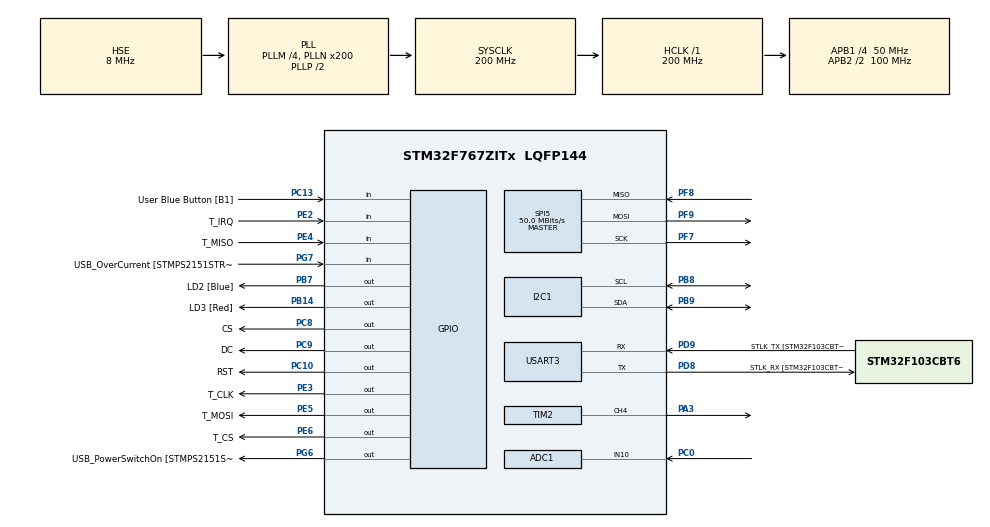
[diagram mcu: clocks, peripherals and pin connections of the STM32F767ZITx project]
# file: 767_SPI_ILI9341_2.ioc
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ADC1.Channel-0\#ChannelRegularConversion=ADC_CHANNEL_10
ADC1.ContinuousConvMode=ENABLE
ADC1.EOCSelection=ADC_EOC_SEQ_CONV
ADC1.NbrOfConversionFlag=1
ADC1.Rank-0\#ChannelRegularConversion=1
ADC1.SamplingTime-0\#ChannelRegularConversion=ADC_SAMPLETIME_3CYCLES
ADC1.master=1
CORTEX_M7.ART_ACCLERATOR_ENABLE=1
CORTEX_M7.CPU_DCache=Enabled
CORTEX_M7.CPU_ICache=Enabled
CORTEX_M7.PREFETCH_ENABLE=1
I2C1.Timing=0x00C0EAFF
Mcu.Family=STM32F7
Mcu.Name=STM32F767ZITx
Mcu.Package=LQFP144
NVIC.PriorityGroup=NVIC_PRIORITYGROUP_4
NVIC.TIM1_UP_TIM10_IRQn=true\:1\:0\:true\:false\:true\:true\:true\:true
NVIC.TIM2_IRQn=true\:2\:0\:true\:false\:true\:true\:true\:true
PA1.GPIO_Label=RMII_REF_CLK [LAN8742A-CZ-TR_REFCLK0]
PA1.Signal=ETH_REF_CLK
PA13.GPIO_Label=TMS
PA13.Mode=Serial_Wire
PA13.Signal=SYS_JTMS-SWDIO
PA14.GPIO_Label=TCK
PA14.Mode=Serial_Wire
PA14.Signal=SYS_JTCK-SWCLK
PA2.GPIO_Label=RMII_MDIO [LAN8742A-CZ-TR_MDIO]
PA2.Signal=ETH_MDIO
PA3.GPIO_Speed=GPIO_SPEED_FREQ_LOW
PA3.Signal=S_TIM2_CH4
PA7.GPIO_Label=RMII_CRS_DV [LAN8742A-CZ-TR_CRS_DV]
PA7.Signal=ETH_CRS_DV
PB13.GPIO_Label=RMII_TXD1 [LAN8742A-CZ-TR_TXD1]
PB13.Signal=ETH_TXD1
PB14.GPIO_Label=LD3 [Red]
PB14.Signal=GPIO_Output
PB3.GPIO_Label=SWO
PB3.Signal=SYS_JTDO-SWO
PB7.GPIO_Label=LD2 [Blue]
PB7.Signal=GPIO_Output
PB8.Mode=I2C
PB8.Signal=I2C1_SCL
PB9.Mode=I2C
PB9.Signal=I2C1_SDA
PC0.Signal=ADCx_IN10
PC1.GPIO_Label=RMII_MDC [LAN8742A-CZ-TR_MDC]
PC1.Signal=ETH_MDC
PC10.GPIO_Label=RST
PC10.GPIO_Speed=GPIO_SPEED_FREQ_VERY_HIGH
PC10.Signal=GPIO_Output
PC13.GPIO_Label=User Blue Button [B1]
PC13.Signal=GPIO_Input
PC14/OSC32_IN.Mode=LSE-External-Oscillator
PC14/OSC32_IN.Signal=RCC_OSC32_IN
PC15/OSC32_OUT.Mode=LSE-External-Oscillator
PC15/OSC32_OUT.Signal=RCC_OSC32_OUT
PC4.GPIO_Label=RMII_RXD0 [LAN8742A-CZ-TR_RXD0]
PC4.Signal=ETH_RXD0
PC5.GPIO_Label=RMII_RXD1 [LAN8742A-CZ-TR_RXD1]
PC5.Signal=ETH_RXD1
PC8.GPIO_Label=CS
PC8.GPIO_Speed=GPIO_SPEED_FREQ_VERY_HIGH
PC8.Signal=GPIO_Output
PC9.GPIO_Label=DC
PC9.GPIO_Speed=GPIO_SPEED_FREQ_VERY_HIGH
PC9.Signal=GPIO_Output
PD8.GPIO_Label=STLK_RX [STM32F103CBT6_PA3]
PD8.Mode=Asynchronous
PD8.Signal=USART3_TX
PD9.GPIO_Label=STLK_TX [STM32F103CBT6_PA2]
PD9.Mode=Asynchronous
PD9.Signal=USART3_RX
PE2.GPIO_Label=T_IRQ
PE2.Signal=GPIO_Input
PE3.GPIO_Label=T_CLK
PE3.GPIO_Speed=GPIO_SPEED_FREQ_VERY_HIGH
PE3.Signal=GPIO_Output
PE4.GPIO_Label=T_MISO
PE4.Signal=GPIO_Input
PE5.GPIO_Label=T_MOSI
PE5.GPIO_Speed=GPIO_SPEED_FREQ_VERY_HIGH
PE5.Signal=GPIO_Output
PE6.GPIO_Label=T_CS
PE6.GPIO_Speed=GPIO_SPEED_FREQ_VERY_HIGH
PE6.Signal=GPIO_Output
PF7.Mode=Full_Duplex_Master
PF7.Signal=SPI5_SCK
PF8.Mode=Full_Duplex_Master
PF8.Signal=SPI5_MISO
PF9.Mode=Full_Duplex_Master
PF9.Signal=SPI5_MOSI
PG11.GPIO_Label=RMII_TX_EN [LAN8742A-CZ-TR_TXEN]
PG11.Signal=ETH_TX_EN
PG13.GPIO_Label=RMII_TXD0 [LAN8742A-CZ-TR_TXD0]
PG13.Signal=ETH_TXD0
PG6.GPIO_Label=USB_PowerSwitchOn [STMPS2151STR_EN]
PG6.Signal=GPIO_Output
PG7.GPIO_Label=USB_OverCurrent [STMPS2151STR_FAULT]
PG7.Signal=GPIO_Input
PH0/OSC_IN.GPIO_Label=MCO [STM32F103CBT6_PA8]
PH0/OSC_IN.Mode=HSE-External-Clock-Source
PH0/OSC_IN.Signal=RCC_OSC_IN
PH1/OSC_OUT.Mode=HSE-External-Clock-Source
PH1/OSC_OUT.Signal=RCC_OSC_OUT
ProjectManager.HeapSize=0x200
ProjectManager.StackSize=0x400
ProjectManager.TargetToolchain=STM32CubeIDE
RCC.48MHZClocksFreq_Value=24000000
RCC.AHBFreq_Value=200000000
RCC.APB1CLKDivider=RCC_HCLK_DIV4
RCC.APB1Freq_Value=50000000
RCC.APB1TimFreq_Value=100000000
RCC.APB2CLKDivider=RCC_HCLK_DIV2
RCC.APB2Freq_Value=100000000
RCC.APB2TimFreq_Value=200000000
RCC.CortexFreq_Value=200000000
RCC.HCLKFreq_Value=200000000
RCC.HSE_VALUE=8000000
RCC.HSI_VALUE=16000000
RCC.PLLM=4
RCC.PLLMUL=RCC_PLL_MUL9
RCC.PLLN=200
RCC.PLLQ=9
RCC.PLLSourceVirtual=RCC_PLLSOURCE_HSE
RCC.PRESCALERUSB=RCC_USBCLKSOURCE_PLL_DIV1_5
RCC.SYSCLKFreq_VALUE=200000000
RCC.SYSCLKSource=RCC_SYSCLKSOURCE_PLLCLK
RCC.SYSCLKSourceVirtual=RCC_SYSCLKSOURCE_PLLCLK
RCC.USBFreq_Value=44444444.44444445
RCC.VCOOutputFreq_Value=400000000
SH.ADCx_IN10.0=ADC1_IN10,IN10
SH.S_TIM2_CH4.0=TIM2_CH4,PWM Generation4 CH4
SPI5.CalculateBaudRate=50.0 MBits/s
SPI5.DataSize=SPI_DATASIZE_8BIT
SPI5.Direction=SPI_DIRECTION_2LINES
SPI5.Mode=SPI_MODE_MASTER
SPI5.NSSPMode=SPI_NSS_PULSE_DISABLE
SPI5.VirtualType=VM_MASTER
TIM1.ClockDivision=TIM_CLOCKDIVISION_DIV1
TIM1.Period=65536-1
TIM1.Prescaler=20000-1
TIM2.Channel-PWM\ Generation4\ CH4=TIM_CHANNEL_4
TIM2.Period=199
TIM2.Prescaler=539
USART3.VirtualMode-Asynchronous=VM_ASYNC
VP_RNG_VS_RNG.Mode=RNG_Activate
VP_TIM1_VS_ClockSourceINT.Mode=Internal
VP_TIM2_VS_ClockSourceINT.Mode=Internal
board=NUCLEO-F767ZI

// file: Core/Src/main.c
/* USER CODE BEGIN Header */
/**
  ******************************************************************************
  * @file           : main.c
  * @brief          : Main program body
  ******************************************************************************
  * @attention
  *
  * <h2><center>&copy; Copyright (c) 2021 STMicroelectronics.
  * All rights reserved.</center></h2>
  *
  * This software component is licensed by ST under BSD 3-Clause license,
  * the "License"; You may not use this file except in compliance with the
  * License. You may obtain a copy of the License at:
  *                        opensource.org/licenses/BSD-3-Clause
  *
  ******************************************************************************
  */
/* USER CODE END Header */
#include "main.h"
#include "adc.h"
#include "i2c.h"
#include "rng.h"
#include "spi.h"
#include "tim.h"
#include "usart.h"
#include "gpio.h"

/* USER CODE BEGIN Includes */
#include "stdio.h"
#include "ILI9341_Touchscreen.h"

#include "ILI9341_STM32_Driver.h"
#include "ILI9341_GFX.h"

#include "snow_tiger.h"

#include "string.h"
#include <stdlib.h>
#include "stm32f7xx_hal.h"
#include "stdbool.h"
/* USER CODE END Includes */

/* USER CODE BEGIN PV */
/* Private variables ---------------------------------------------------------*/
float h = 30.0, t = 40.0;
uint16_t x_pos, y_pos = 0;
uint8_t step = 0;
HAL_StatusTypeDef status;
uint16_t Red = 0;
uint16_t Green = 0;
uint16_t Blue = 0;
uint16_t RGB_color;
uint8_t rCount = 0;
uint8_t gCount = 0;
uint8_t bCount = 0;
uint8_t rLength = 0;
uint8_t gLength = 0;
uint8_t bLength = 0;
int show_screen_2 = 0;
uint32_t count;
uint32_t prevCount;
uint32_t delayTime = 0;
uint16_t rgb = 0;
uint16_t exit_screen_2 = 1;
volatile uint32_t adc_val = 0;
#define P1011387_HEIGHT 132
#define P1011387_WIDTH 100
float brightness;

const uint16_t student_photo[26400]  = {
  0x9ef7, 0x9def, 0x9def, 0x7def, 0x7def, 0x7def, 0x7def, 0x5ce7, 0x5cef, 0x7def, 0x5de7, 0x5de7, 0xfade, 0xd5d5, 0xd1cc, 0x70c4, 0xb1cc, 0x33e5, 0x74ed, 0x74ed, 0xb6ed, 0x75ed, 0xd2e4, 0xf3e4, 0xd6ed, 0x17ee, 0x94e5, 0xd9ee, 0xfaee, 0x1aef, 0x1aef, 0x3bf7, 0x3bf7, 0x3bf7, 0x3bf7, 0x3bf7, 0x3bf7, 0x3bf7, 0x5bf7, 0x5bf7, 0x5bf7, 0x5bf7, 0x5bf7, 0x5bf7, 0x5bf7, 0x3bf7, 0x1bef, 0x1bef, 0x1aef, 0x1aef, 0x1aef, 0x1aef, 0x1aef, 0x1bf7, 0x1bef, 0x1aef, 0x5bef, 0x9df7, 0x9df7, 0x5bef, 0x16ef, 0xd4ee, 0xf5ee, 0x39ef, 0x7df7, 0x9ef7, 0x9ef7, 0x9ef7, 0x9ef7, 0x9ef7, 0x9ef7, 0x9ef7, 0x9ef7, 0x7def, 0x3ce7, 0xfcde, 0xfcd6, 0xfcd6, 0xfcd6, 0xfbd6, 0xfbd6, 0xfbd6, 0xfcd6, 0xfcd6, 0xfcd6, 0xdbde, 0x38e6, 0x96ed, 0xd4ed, 0x52ee, 0x32ee, 0xb5ed, 0x96ed, 0xb6ed, 0xf4ed, 0x91ee, 0x90ee, 0x90ee, 0x51ee, 0xd0ed,
  0x9ef7, 0x9ef7, 0x9ef7, 0x9def, 0x7def, 0x7def, 0x7bef, 0x5ae7, 0x5ae7, 0x5bef, 0x7def, 0x7de7, 0x5ce7, 0x57d6, 0xf1cc, 0x71c4, 0xb1cc, 0x53e5, 0x94ed, 0x54ed, 0x74ed, 0x95ed, 0x13e5, 0xd2dc, 0x74ed, 0xf6ed, 0x95e5, 0xd5dd, 0xf9ee, 0x1aef, 0x1aef, 0x1aef, 0x3bf7, 0x3bf7, 0x3bf7, 0x3bf7, 0x3bf7, 0x3bf7, 0x5bf7, 0x5bf7, 0x5bf7, 0x5bf7, 0x5bf7, 0x5bf7, 0x3bf7, 0x3bf7, 0x3bf7, 0x3bf7, 0x3bf7, 0x3bf7, 0x1aef, 0x1aef, 0x3bf7, 0x3bf7, 0x1bef, 0x1aef, 0x39ef, 0x7cf7, 0x9ef7, 0x9ef7, 0x9df7, 0x7cef, 0x38ef, 0x14ef, 0x58ef, 0x9cf7, 0x9ef7, 0x9ef7, 0x9ef7, 0x9ef7, 0x9ef7, 0x9ef7, 0x9ef7, 0x7def, 0x3ce7, 0xfcd6, 0xfcd6, 0xfcd6, 0xfcd6, 0xfbd6, 0xfbd6, 0xfbd6, 0xfcd6, 0xfcd6, 0xfcd6, 0xbade, 0xf8e5, 0xb5ed, 0x13ee, 0x52ee, 0xf4ed, 0x96ed, 0xb6ed, 0xd5ed, 0x72ee, 0x71ee, 0x32ee, 0xf4ed, 0x32ee, 0x71ee,
  0x9def, 0x9ef7, 0x9ef7, 0x9eef, 0x9def, 0x7cef, 0x7bef, 0x5ae7, 0x58e7, 0x5ae7, 0x7def, 0x7def, 0x7ce7, 0x99de, 0x33cd, 0x91c4, 0xf2d4, 0x93e5, 0xd3ed, 0x93ed, 0x33ed, 0x95ed, 0x54e5, 0xb1e4, 0xf2e4, 0x95ed, 0xd6ed, 0x33d5, 0x77e6, 0xfaee, 0xfaee, 0xfaee, 0x1aef, 0x3bf7, 0x3bf7, 0x3bf7, 0x3bf7, 0x3bf7, 0x3bf7, 0x5bf7, 0x5bf7, 0x5bf7, 0x5bf7, 0x3bf7, 0x3bf7, 0x3cf7, 0x5cf7, 0x3cf7, 0x3cf7, 0x3bf7, 0x3bf7, 0x3bf7, 0x3bf7, 0x3bf7, 0x1aef, 0x1aef, 0x17ef, 0x7bef, 0x9df7, 0x9ef7, 0x9ef7, 0x7bf7, 0x16ef, 0xd3f6, 0xf3f6, 0x56f7, 0x7bef, 0x9df7, 0x9ef7, 0x9ef7, 0x9ef7, 0x9ef7, 0x9ef7, 0x7def, 0x1cdf, 0xfcd6, 0xfcd6, 0xfcd6, 0xfcd6, 0xfbd6, 0xfbd6, 0xfbd6, 0xfcd6, 0xfcd6, 0xfcd6, 0x79de, 0xd7e5, 0xf4ed, 0x52ee, 0x13ee, 0xb5ed, 0xd5ed, 0x14ee, 0x52ee, 0x52ee, 0xd5ed, 0xd5ed, 0x32ee, 0x52ee, 0x95ed,
  0x7def, 0x9eef, 0x9ef7, 0x9ef7, 0x9def, 0x7bef, 0x7aef, 0x5ae7, 0x5ae7, 0x5be7, 0x7cef, 0x7bef, 0x39ef, 0xd8e6, 0xb5cd, 0xd1cc, 0x53dd, 0xf4ed, 0x13ee, 0xd3ed, 0x32ed, 0x53ed, 0x95ed, 0xd2e4, 0xb1e4, 0x13e5, 0xb6ed, 0x75e5, 0xb4d5, 0xd9ee, 0xfaee, 0xfaee, 0xfaee, 0x1aef, 0x3af7, 0x3bf7, 0x3bf7, 0x3bf7, 0x5bf7, 0x5bf7, 0x5bf7, 0x5bf7, 0x5bf7, 0x3bf7, 0x3bf7, 0x5cf7, 0x5cf7, 0x5cf7, 0x3bf7, 0x3bf7, 0x3bf7, 0x3bf7, 0x3bf7, 0x1bef, 0x1aef, 0x39ef, 0x16ef, 0x59ef, 0x9df7, 0x9ef7, 0x9ef7, 0x59f7, 0xf4f6, 0xb3ee, 0xd3f6, 0xf3f6, 0x35f7, 0x7af7, 0x9cf7, 0x9ef7, 0x9ef7, 0x9ef7, 0x9ef7, 0x5def, 0x1cdf, 0xfcd6, 0xfcd6, 0xfcd6, 0xfcd6, 0xfcd6, 0xfcd6, 0xfcd6, 0xfcd6, 0xfcd6, 0xfbd6, 0x59e6, 0xf6ed, 0x33ee, 0x72ee, 0x33ee, 0x33ee, 0x52ee, 0x71ee, 0x71ee, 0xd5ed, 0xd5ed, 0x52ee, 0x32ee, 0xb5ed, 0xb5ed,
  0x7def, 0x9def, 0x9ef7, 0x9ef7, 0x9def, 0x7cef, 0x7aef, 0x59e7, 0x5ae7, 0x5bef, 0x5bef, 0x58ef, 0x15ef, 0xd5ee, 0x15d6, 0x53cd, 0xb3dd, 0x14e6, 0xd3e5, 0xb2e5, 0x52ed, 0x12ed, 0x95ed, 0xf2e4, 0x91e4, 0xd2e4, 0x54ed, 0xd6ed, 0x74dd, 0x57e6, 0xfaee, 0xfaee, 0xd9ee, 0xfaee, 0x1aef, 0x1af7, 0x3bf7, 0x3bf7, 0x5bf7, 0x5bf7, 0x5bf7, 0x5bf7, 0x5bf7, 0x3bf7, 0x3bf7, 0x3bf7, 0x3bf7, 0x5cf7, 0x3bf7, 0x3bf7, 0x3bf7, 0x1aef, 0x1aef, 0x1aef, 0x1aef, 0x39ef, 0x16ef, 0x37ef, 0x7bf7, 0x9ef7, 0x9df7, 0x58f7, 0xd3f6, 0xd3ee, 0xf5ee, 0xd4ee, 0xf3f6, 0x34f7, 0x79f7, 0x9df7, 0x9ef7, 0x9ef7, 0x9ef7, 0x5de7, 0x1cdf, 0x1cdf, 0xfcd6, 0xfcd6, 0xfcd6, 0xfcd6, 0xfcd6, 0xfcd6, 0xfcd6, 0xfcd6, 0xfbde, 0x38e6, 0x14ee, 0x72ee, 0x91ee, 0x72ee, 0x53ee, 0x14ee, 0x13ee, 0x52ee, 0x14ee, 0x52ee, 0x52ee, 0xb5ed, 0xd5ed, 0x52ee,
  0x5bef, 0x7cef, 0x9df7, 0x9ef7, 0x9df7, 0x7cef, 0x7aef, 0x59e7, 0x5aef, 0x5bef, 0x5aef, 0x58ef, 0x36ef, 0xf4ee, 0x75de, 0xf5d5, 0xf4e5, 0x14e6, 0xd3e5, 0xb2e5, 0x72e5, 0xf2ec, 0x74ed, 0x13e5, 0x91e4, 0xd2e4, 0x13e5, 0xd6ed, 0xd6ed, 0xd5e5, 0xb9ee, 0xfaee, 0xd9ee, 0xd9ee, 0xd9ee, 0xfaee, 0x1aef, 0x3bf7, 0x3bf7, 0x3bf7, 0x5bf7, 0x3bf7, 0x3bf7, 0x3bf7, 0x3af7, 0x3af7, 0x3af7, 0x3bf7, 0x3bf7, 0x3bf7, 0x3af7, 0x1aef, 0x1aef, 0x1aef, 0x3bef, 0x39ef, 0x38ef, 0x15f7, 0x59f7, 0x7cf7, 0x7df7, 0x37f7, 0xf3f6, 0xf5ee, 0x38ef, 0x5aef, 0x37ef, 0x36ef, 0x59ef, 0x9df7, 0x9ef7, 0x9ef7, 0x9eef, 0x3ce7, 0x1cdf, 0x1cdf, 0xfcd6, 0xfcd6, 0xfcd6, 0xfcde, 0xfcd6, 0xfcd6, 0xfcd6, 0xfcde, 0xdbde, 0x57e6, 0x52ee, 0x91ee, 0x53ee, 0x14ee, 0xd5ed, 0xd5ed, 0x33ee, 0x91ee, 0x91ee, 0x71ee, 0x32ee, 0xd5ed, 0x32ee, 0x71ee,
  0x59ef, 0x37ef, 0x5bef, 0x9df7, 0x9df7, 0x7bef, 0x59ef, 0x59ef, 0x7bef, 0x5bef, 0x5aef, 0x59ef, 0x16ef, 0xf4ee, 0xd6ee, 0x98e6, 0x34e6, 0x34e6, 0xf3e5, 0x92e5, 0x72e5, 0xd1ec, 0x34ed, 0x13e5, 0xb1e4, 0x13ed, 0x33e5, 0xd6ed, 0x17ee, 0xb5ed, 0x37ee, 0xd9ee, 0xd9ee, 0xd9e6, 0xd9e6, 0xd9ee, 0xfaee, 0x1aef, 0x3bf7, 0x3bf7, 0x3bf7, 0x3bf7, 0x3bf7, 0x3af7, 0x3aef, 0x1aef, 0x1aef, 0x3aef, 0x3af7, 0x3af7, 0x3aef, 0x1aef, 0x1aef, 0x1aef, 0x5bef, 0x38ef, 0x59ef, 0x16f7, 0x15f7, 0x7af7, 0x7bf7, 0x36ef, 0xf4ee, 0x15ef, 0x59f7, 0x9df7, 0x7cf7, 0x7bef, 0x9cf7, 0x9ef7, 0x9ef7, 0x9ef7, 0x7def, 0x3ce7, 0x1cdf, 0xfcd6, 0xfcd6, 0x1cdf, 0xfcde, 0xfcde, 0xfcd6, 0xfcd6, 0xfcd6, 0x1cdf, 0xbade, 0x75ee, 0x72ee, 0x33ee, 0xd5ed, 0xb6ed, 0xb6ed, 0x14ee, 0x72ee, 0x53ee, 0x14ee, 0x13ee, 0x91ee, 0x52ee, 0x71ee, 0x90ee,
  0x5bef, 0x16ef, 0xf5ee, 0x5aef, 0x7def, 0x7bef, 0x7aef, 0x7aef, 0x7bef, 0x5bef, 0x5bef, 0x58ef, 0x15ef, 0xd3ee, 0xf7ee, 0xf9e6, 0x75e6, 0x53e6, 0xf2e5, 0x92e5, 0x72e5, 0xb1e4, 0x13ed, 0x33ed, 0xf2e4, 0x34ed, 0x34ed, 0xb5ed, 0xf6ed, 0xd6ed, 0xb5ed, 0x98ee, 0xd9ee, 0xd9e6, 0xb9e6, 0xb9e6, 0xd9ee, 0xf9ee, 0xfaee, 0x1aef, 0x3bf7, 0x3bf7, 0x3af7, 0x1aef, 0x1aef, 0x1aef, 0x1aef, 0x1aef, 0x3aef, 0x1aef, 0x1aef, 0x1aef, 0xfaee, 0x5cef, 0x5bef, 0x37ef, 0x5bef, 0x17f7, 0x14f7, 0x58f7, 0x58f7, 0x36ef, 0x16ef, 0x37ef, 0x7af7, 0x9ef7, 0x9ef7, 0x9ef7, 0x9ef7, 0x9ef7, 0x9ef7, 0x9ef7, 0x7def, 0x3ce7, 0xfcde, 0xfcd6, 0xfcd6, 0xfcde, 0x1cdf, 0x1cdf, 0x1cdf, 0xfcde, 0x1cdf, 0x1cdf, 0x99e6, 0x93ee, 0x52ee, 0xd5ed, 0x96ed, 0xb6ed, 0x14ee, 0x72ee, 0x33ee, 0xd5ed, 0xd5ed, 0x32ee, 0x52ee, 0xf3ed, 0xd4ed, 0x33ee,
  0x7def, 0x5bef, 0x16ef, 0x17ef, 0x5bef, 0x7cef, 0x7cef, 0x7cef, 0x7cef, 0x5cef, 0x59ef, 0x36ef, 0xf4ee, 0xd4ee, 0xf8ee, 0x1ae7, 0x95e6, 0x33e6, 0xf2e5, 0xb2e5, 0x92e5, 0xb1e4, 0xf2ec, 0x54ed, 0x34ed, 0x34ed, 0x33ed, 0x95ed, 0xb6ed, 0xf7ed, 0x95ed, 0x36ee, 0xb9e6, 0xd9e6, 0xd9e6, 0xb9e6, 0xb9e6, 0xb9e6, 0xd9ee, 0xfaee, 0x1aef, 0x1af7, 0x1aef, 0x1af7, 0x1af7, 0x1af7, 0x1af7, 0x1aef, 0x1aef, 0x1aef, 0x1aef, 0xfaee, 0x1bef, 0x7def, 0x5aef, 0x36ef, 0x7bf7, 0x59ef, 0x15f7, 0x37f7, 0x36f7, 0x57f7, 0x58ef, 0x38ef, 0x7aef, 0x9ef7, 0x9ef7, 0x9ef7, 0x9ef7, 0x9ef7, 0x9ef7, 0x9ef7, 0x7def, 0x3ce7, 0x1cdf, 0xfcd6, 0x1cdf, 0xfcde, 0xfcde, 0x1cdf, 0xfcde, 0x1cdf, 0x1cdf, 0xfcde, 0x97e6, 0x92ee, 0x33ee, 0xf5ed, 0x14ee, 0x53ee, 0x72ee, 0x33ee, 0xd6ed, 0xd6ed, 0x13ee, 0x52ee, 0xd5ed, 0x95ed, 0xf4ed, 0x71ee,
  0x7aef, 0x58ef, 0x35ef, 0x16ef, 0x7bef, 0x9def, 0x7def, 0x7def, 0x7def, 0x7cef, 0x38ef, 0x14ef, 0xf4f6, 0xd5ee, 0x19ef, 0x3be7, 0x76e6, 0x13e6, 0xf3ed, 0xb3e5, 0x52e5, 0xb1e4, 0xf2ec, 0x75ed, 0x75ed, 0x54ed, 0x13ed, 0x54ed, 0x95ed, 0xb6ed, 0xd6ed, 0xb5ed, 0x78e6, 0xd9e6, 0xd9e6, 0xb9e6, 0xb9e6, 0x98e6, 0x99e6, 0xb9ee, 0xf9ee, 0x1aef, 0x1af7, 0x1af7, 0x1af7, 0x1af7, 0x1af7, 0x1af7, 0x1aef, 0x1aef, 0x1aef, 0x3bef, 0x7df7, 0x9ef7, 0x7cef, 0x38ef, 0x7bf7, 0x7cf7, 0x38ef, 0x59ef, 0x79ef, 0x7aef, 0x7bef, 0x59ef, 0x7cef, 0x9ef7, 0x9ef7, 0x9ef7, 0x9ef7, 0x9ef7, 0x9ef7, 0x9ef7, 0x5def, 0x1cdf, 0x1cdf, 0x1cdf, 0x1cdf, 0xfcde, 0xfcde, 0xfcde, 0x1cdf, 0x1cdf, 0x1cdf, 0xfbde, 0xb6e6, 0x92ee, 0x92ee, 0x92ee, 0x91ee, 0x91ee, 0x53ee, 0xd5ed, 0xb6ed, 0xf5ed, 0x52ee, 0xd4ed, 0xb6ed, 0xd5ed, 0x91ee, 0x33ee,
  0x37ef, 0x37ef, 0x15ef, 0x59ef, 0x9def, 0x9def, 0x7def, 0x7def, 0x7def, 0x7def, 0x38ef, 0xf4ee, 0xd3ee, 0xd6ee, 0x5bef, 0x5ce7, 0x98e6, 0xf3e5, 0xd2ed, 0x52e5, 0xd1dc, 0x91e4, 0xf2ec, 0x75ed, 0x95ed, 0x54ed, 0x13ed, 0x33ed, 0x54ed, 0x75ed, 0xd6ed, 0x95ed, 0x57e6, 0xd9e6, 0xd9e6, 0xb9e6, 0xb9e6, 0xb9e6, 0x98e6, 0x98e6, 0xb9ee, 0xd9ee, 0xf9ee, 0xf9ee, 0x19ef, 0x19ef, 0x19ef, 0x1aef, 0x1aef, 0xfaee, 0x3cef, 0x9def, 0x9ef7, 0xbef7, 0x9ef7, 0x9df7, 0x9ef7, 0x9ef7, 0x9df7, 0x9df7, 0x9df7, 0x9df7, 0x9df7, 0x9cf7, 0x9df7, 0x9ef7, 0x9ef7, 0x9ef7, 0x9ef7, 0x9ef7, 0x9ef7, 0x9ef7, 0x5de7, 0x1cdf, 0x1cdf, 0x1cdf, 0x1cdf, 0x1cdf, 0x1cdf, 0xfcde, 0xfcde, 0xfcd6, 0x1cdf, 0xfbde, 0xd4e6, 0xb1ee, 0x72ee, 0x14ee, 0x15ee, 0x53ee, 0x14ee, 0x96ed, 0xb6ed, 0xf4ed, 0x52ee, 0x96ed, 0xb6f5, 0x32ee, 0x32ee, 0x76ed,
  0x59e7, 0x57ef, 0x36ef, 0x5bef, 0x9def, 0x9eef, 0x9def, 0x9def, 0x9eef, 0x9def, 0x3bef, 0xb6e6, 0xb5ee, 0x1aef, 0x7def, 0x7def, 0xfae6, 0x14de, 0x92e5, 0xf1dc, 0x91d4, 0x91e4, 0xb1ec, 0x75ed, 0xb5ed, 0x33ed, 0x13ed, 0x53ed, 0x54ed, 0x33ed, 0xd6ed, 0x95ed, 0xf6e5, 0x98e6, 0xd9ee, 0xd9ee, 0xb9e6, 0xb9e6, 0xb9e6, 0x98e6, 0x98e6, 0x58e6, 0x37e6, 0x37e6, 0x78e6, 0x78ee, 0xb8ee, 0xf9ee, 0x3bef, 0x7def, 0x9ef7, 0x9eef, 0x9def, 0x9eef, 0x9eef, 0x9eef, 0xbef7, 0xbef7, 0x9ef7, 0x9ef7, 0x9ef7, 0x9ef7, 0x9ef7, 0x9ef7, 0x9ef7, 0x9ef7, 0x9ef7, 0x9ef7, 0x9ef7, 0x9ef7, 0x9ef7, 0x9eef, 0x3ce7, 0x1cdf, 0x1cdf, 0x1cdf, 0x1cdf, 0xfcde, 0xfcde, 0xfcde, 0xfcde, 0x1cdf, 0x1cdf, 0xfade, 0xd4ee, 0x53ee, 0xd5ed, 0x96ed, 0xf5ed, 0x53ee, 0x52ee, 0x72ee, 0x92ee, 0x92ee, 0x92ee, 0x34ee, 0x53ee, 0x91ee, 0x72ee, 0x13ee,
  0x58ef, 0x36ef, 0x5ae7, 0x7def, 0x9def, 0x9eef, 0x9def, 0x9def, 0x9eef, 0x9def, 0x7def, 0x5bef, 0x5cef, 0x7def, 0x7de7, 0x7def, 0x3be7, 0x36de, 0x72e5, 0xd1dc, 0x91dc, 0x91e4, 0xb1ec, 0x33ed, 0x95ed, 0x54ed, 0x33ed, 0x53ed, 0x54ed, 0x13ed, 0x95ed, 0x95ed, 0xb5e5, 0x78e6, 0xb9e6, 0xb9e6, 0xb9e6, 0xb9e6, 0xb9e6, 0x99e6, 0x78e6, 0xb6cd, 0x929c, 0x318c, 0x929c, 0x17ce, 0x5def, 0x9def, 0x9ef7, 0x9ef7, 0x9eef, 0x9eef, 0x9def, 0x7def, 0x7def, 0x9def, 0x9def, 0x9eef, 0x9eef, 0x9ef7, 0x9ef7, 0x9ef7, 0x9ef7, 0x9ef7, 0x9ef7, 0x9ef7, 0x9ef7, 0x9ef7, 0x9ef7, 0x9ef7, 0x9ef7, 0x7def, 0x3ce7, 0x1cdf, 0x1cdf, 0x1cdf, 0x1cdf, 0x1cdf, 0x1cdf, 0x1cdf, 0x1cdf, 0x1cdf, 0x1cdf, 0xf9de, 0x75ee, 0xd5ed, 0x96ed, 0xb6ed, 0xf4ed, 0x72ee, 0x72ee, 0xf4ed, 0xb5ed, 0xd5ed, 0x52ee, 0x72ee, 0x54ee, 0x33ee, 0xb0ee, 0x52ee,
  0x59ef, 0x5be7, 0x7de7, 0x9def, 0x9eef, 0x9eef, 0x9eef, 0x9eef, 0x9def, 0x7cef, 0x7bef, 0x7bef, 0x7cef, 0x7def, 0x7de7, 0x9def, 0x5def, 0x58de, 0xf1d4, 0x91d4, 0x91dc, 0x91ec, 0x70ec, 0xd2ec, 0x54ed, 0x54ed, 0x33ed, 0x34ed, 0x75ed, 0x33ed, 0x74ed, 0x95ed, 0x74e5, 0x37e6, 0xb9e6, 0xb9e6, 0xb9e6, 0xb8e6, 0x98e6, 0x98e6, 0xf6d5, 0xf3ac, 0x1084, 0x1094, 0x929c, 0xbad6, 0x9ef7, 0x9ef7, 0x9ef7, 0x9eef, 0x9eef, 0x9eef, 0x9eef, 0x9eef, 0x9eef, 0x9def, 0x9def, 0x9def, 0x9def, 0x9eef, 0x9ef7, 0x9ef7, 0x9ef7, 0x9ef7, 0x9ef7, 0x9ef7, 0x9ef7, 0x9ef7, 0x9ef7, 0x9ef7, 0x9ef7, 0x7def, 0x1cdf, 0x1cdf, 0x1cdf, 0x1cdf, 0x1cdf, 0x1cdf, 0x1cdf, 0x1cdf, 0x1cdf, 0x1cdf, 0x1cdf, 0xf8e6, 0x35ee, 0xb6ed, 0xb6ed, 0xf5ed, 0x33ee, 0x53ee, 0xd5ed, 0xb6ed, 0xb6ed, 0x14ee, 0x33ee, 0xd5ed, 0xb6ed, 0xd5ed, 0xf4ed, 0x96ed,
  0x7de7, 0x7de7, 0x7de7, 0x7def, 0x9eef, 0x9eef, 0x9def, 0x7cef, 0x7aef, 0x57ef, 0x5aef, 0x5aef, 0x59ef, 0x7bef, 0x7def, 0x9eef, 0x7def, 0xbae6, 0x53d5, 0xb1dc, 0xb1e4, 0x91ec, 0x70ec, 0x91ec, 0xf2ec, 0x12ed, 0x33ed, 0x33ed, 0x54ed, 0x75ed, 0x54ed, 0x95ed, 0x53e5, 0xf6e5, 0x98e6, 0xb9e6, 0xb8e6, 0xb8e6, 0x98e6, 0x57de, 0x54bd, 0x518c, 0xf083, 0x109c, 0x92ac, 0xdade, 0x9eef, 0x9ef7, 0x9ef7, 0xbef7, 0xbef7, 0xbef7, 0x9ef7, 0x9eef, 0x9eef, 0x9eef, 0x9eef, 0x9def, 0x9def, 0x9def, 0x9eef, 0x9ef7, 0x9ef7, 0x9ef7, 0x9ef7, 0x9ef7, 0x9ef7, 0x9ef7, 0x9ef7, 0x9ef7, 0x9ef7, 0x7def, 0x1cdf, 0x1cdf, 0x1cdf, 0x1cdf, 0x1cdf, 0x1cdf, 0xfcde, 0x1cdf, 0xfcde, 0x1cdf, 0x1cdf, 0xb8e6, 0xf6ed, 0xb6ed, 0xf5ed, 0x53ee, 0x53ee, 0xf5ed, 0xd5ed, 0xf5ed, 0x14ee, 0x33ee, 0xd5ed, 0xb6ed, 0xd5ed, 0xd4ed, 0x96ed, 0x96f5,
  0x7de7, 0x7de7, 0x7def, 0x7def, 0x9def, 0x9def, 0x7bef, 0x58ef, 0x35f7, 0x14f7, 0x59ef, 0x5aef, 0x37ef, 0x59ef, 0x9def, 0x9ef7, 0x7def, 0x3bef, 0x37e6, 0x13e5, 0xd2ec, 0xb1ec, 0x70ec, 0x50ec, 0x90ec, 0xb1ec, 0x12ed, 0x33ed, 0x34ed, 0x75ed, 0x74ed, 0x95ed, 0x33ed, 0x95e5, 0x57e6, 0xb8e6, 0xb9e6, 0xb8e6, 0x78e6, 0xb5cd, 0x929c, 0x1184, 0x1094, 0x30ac, 0xb2b4, 0xfbde, 0x9eef, 0x9eef, 0x9ef7, 0xbef7, 0xbef7, 0xbef7, 0xbef7, 0xbef7, 0xbef7, 0xbef7, 0x9eef, 0x9eef, 0x9eef, 0x9def, 0x9def, 0x9eef, 0x9ef7, 0x9ef7, 0x9ef7, 0x9ef7, 0x9ef7, 0x9ef7, 0x9ef7, 0x9ef7, 0x9ef7, 0x5de7, 0x1cdf, 0x1cdf, 0x1cdf, 0x1cdf, 0xfcde, 0x1cdf, 0xfcde, 0x1cdf, 0xfcde, 0x1cdf, 0x1cdf, 0x99e6, 0xf6ed, 0x14ee, 0x73ee, 0x72ee, 0x33ee, 0x14ee, 0x53ee, 0x53ee, 0x53ee, 0xf5ed, 0xb6ed, 0xd5ed, 0xf4ed, 0x96ed, 0x96ed, 0x96ed,
  0x7de7, 0x7de7, 0x9def, 0x9def, 0x9def, 0x7cef, 0x58ef, 0x35f7, 0x33f7, 0x15ef, 0x5aef, 0x59ef, 0x35f7, 0x57ef, 0x7cef, 0x7def, 0x7bef, 0x59ef, 0x1be7, 0x37e6, 0x12e5, 0xb1ec, 0x50ec, 0x2fec, 0x50ec, 0x70ec, 0xd1ec, 0x13ed, 0x33ed, 0x34ed, 0x54ed, 0x75ed, 0x54ed, 0x74e5, 0x36e6, 0x98e6, 0x98e6, 0x98e6, 0xf6d5, 0xd2ac, 0x308c, 0x1084, 0x30a4, 0x91cc, 0xf2cc, 0xfbe6, 0x9ef7, 0x9eef, 0x9ef7, 0xbef7, 0xbef7, 0xbef7, 0xbef7, 0xbef7, 0xbef7, 0xbef7, 0x9ef7, 0x9eef, 0x9eef, 0x9def, 0x9def, 0x9def, 0x9ef7, 0x9ef7, 0x9ef7, 0x9ef7, 0x9ef7, 0x9ef7, 0x9ef7, 0x9ef7, 0x9def, 0x3ce7, 0x1cdf, 0x1cdf, 0x1cdf, 0x1cdf, 0x1cdf, 0x1cdf, 0x1cdf, 0x1cdf, 0x1cdf, 0x1cdf, 0x1cdf, 0x78e6, 0x54ee, 0x73ee, 0x53ee, 0x53ee, 0x52ee, 0x53ee, 0x34ee, 0x34ee, 0x53ee, 0xf5ed, 0xf5ed, 0x13ee, 0xf4ed, 0x96ed, 0xb6ed, 0xf4ed,
  0x7de7, 0x7de7, 0x7def, 0x9eef, 0x9def, 0x7def, 0x5aef, 0x57ef, 0x36ef, 0x38ef, 0x5bef, 0x39ef, 0x15f7, 0x36f7, 0x5aef, 0x5aef, 0x37ef, 0x38ef, 0x7def, 0xfbe6, 0x74e5, 0x91ec, 0x50ec, 0x2fec, 0x2fec, 0x30ec, 0x70ec, 0xd2ec, 0x33ed, 0x33ed, 0x33ed, 0x54ed, 0x54ed, 0x33e5, 0xf6e5, 0x98e6, 0x98e6, 0x16de, 0x13b5, 0x3094, 0x1094, 0x1094, 0x51b4, 0xd2dc, 0x54dd, 0xfbe6, 0x9def, 0x9eef, 0x9ef7, 0xbef7, 0xbef7, 0xbef7, 0xbef7, 0xbef7, 0xbef7, 0xbef7, 0x9ef7, 0x9ef7, 0x9eef, 0x9def, 0x7def, 0x9def, 0x9eef, 0x9ef7, 0x9ef7, 0x9ef7, 0x9ef7, 0x9ef7, 0x9ef7, 0x9ef7, 0x7def, 0x3cdf, 0x1cdf, 0x1cdf, 0x1cdf, 0x1cdf, 0x1cdf, 0x1cdf, 0x1cdf, 0x1cdf, 0x1cdf, 0x1cdf, 0xfbde, 0x76e6, 0x11e6, 0x71e5, 0x92e5, 0x32ee, 0x32ee, 0xb4ed, 0xd5ed, 0x33ee, 0x92ee, 0x73ee, 0x53ee, 0x72ee, 0x53ee, 0x14ee, 0x53ee, 0x92ee,
  0x7de7, 0x7def, 0x7eef, 0x9eef, 0x7eef, 0x7def, 0x7bef, 0x59ef, 0x59ef, 0x5bef, 0x5cef, 0x38ef, 0x15ef, 0x36ef, 0x37ef, 0x36ef, 0x15f7, 0x38ef, 0x7def, 0x5cef, 0x38e6, 0x91ec, 0x50ec, 0x2fec, 0x2fec, 0x2fec, 0x50ec, 0xb1ec, 0x13ed, 0x13ed, 0x13ed, 0x13ed, 0x34ed, 0x33e5, 0xd5e5, 0x77e6, 0x57e6, 0x74c5, 0x71a4, 0x109c, 0x109c, 0x0f9c, 0x50bc, 0xd2e4, 0x75e5, 0x1be7, 0x7def, 0x9ef7, 0x9ef7, 0xbef7, 0xbef7, 0xbef7, 0xbef7, 0xbef7, 0xbef7, 0xbef7, 0xbef7, 0x9ef7, 0x9ef7, 0x9eef, 0x7def, 0x7def, 0x9def, 0x9ef7, 0x9ef7, 0x9ef7, 0x9ef7, 0x9ef7, 0x9ef7, 0x9ef7, 0x7def, 0x1cdf, 0x1cdf, 0x1cdf, 0x1cdf, 0x1cdf, 0x1cdf, 0xfcde, 0x1cdf, 0x1cdf, 0x1cdf, 0x1cdf, 0xdbde, 0x74e6, 0x0fdd, 0x4ed4, 0x50e5, 0xd0e5, 0xf0e4, 0x90e4, 0x71e5, 0x11ee, 0xb0ed, 0xd1ed, 0x71ee, 0x91ee, 0x72ee, 0x92ee, 0x72ee, 0x52ee,
  0x7de7, 0x7eef, 0x9eef, 0x7eef, 0x7def, 0x7def, 0x7cef, 0x7cef, 0x5aef, 0x5bef, 0x7cef, 0x38ef, 0x36ef, 0x58ef, 0x57ef, 0x35f7, 0x14f7, 0x38ef, 0x7def, 0x7def, 0xdae6, 0xd2e4, 0x50ec, 0x50ec, 0x2fec, 0x2fec, 0x2fec, 0x71ec, 0xf2ec, 0x33ed, 0x13ed, 0xf3ec, 0x13ed, 0xf2e4, 0xd5e5, 0x57e6, 0xb5cd, 0xb1a4, 0x309c, 0x0f9c, 0xef93, 0xefa3, 0x0fcc, 0x70dc, 0x75dd, 0x3ce7, 0x9def, 0x9ef7, 0x9ef7, 0xbef7, 0xbef7, 0xbef7, 0xbef7, 0xbef7, 0xbef7, 0xbef7, 0xbef7, 0x9ef7, 0x9ef7, 0x9eef, 0x7def, 0x7def, 0x9def, 0x9eef, 0x9ef7, 0x9ef7, 0x9ef7, 0x9ef7, 0x9ef7, 0x9ef7, 0x7def, 0x1cdf, 0x1cdf, 0x1cdf, 0xfcde, 0xfcde, 0xfcde, 0xfcde, 0x1cdf, 0x1cdf, 0x1cdf, 0x1cdf, 0xbad6, 0xf2d5, 0x4dc4, 0x4dcc, 0x8fdd, 0xefdc, 0xcedb, 0x8ee4, 0xd0e5, 0x6fe5, 0x6eec, 0xb0ed, 0x51ee, 0x0fe5, 0x8fe4, 0xf0e4, 0xd1ed, 0x31e5,
  0x7ddf, 0x7ee7, 0x9eef, 0x7eef, 0x7eef, 0x7def, 0x7def, 0x7def, 0x5bef, 0x7cef, 0x7cef, 0x59ef, 0x38ef, 0x5aef, 0x58ef, 0x34f7, 0x14f7, 0x38ef, 0x7def, 0x7def, 0x1cef, 0x74e5, 0x70ec, 0x50ec, 0x2fe4, 0x2fe4, 0x2fec, 0x50ec, 0xd2ec, 0x33ed, 0x13ed, 0xf2ec, 0xf3ec, 0xf2e4, 0x74e5, 0xb5cd, 0xd39c, 0x308c, 0x0f9c, 0x0f9c, 0x0f9c, 0xeeab, 0xeed3, 0x2fdc, 0x54dd, 0x5de7, 0x9eef, 0x9ef7, 0x9ef7, 0xbef7, 0xbef7, 0xbef7, 0xbef7, 0xbef7, 0xbef7, 0xbef7, 0xbef7, 0xbef7, 0x9ef7, 0x9eef, 0x9def, 0x7de7, 0x7de7, 0x9def, 0x9ef7, 0x9ef7, 0x9ef7, 0x9ef7, 0x9ef7, 0x9eef, 0x5de7, 0x1cdf, 0x1cdf, 0x1cdf, 0xfcde, 0xfcde, 0x1cdf, 0x1cdf, 0x1cdf, 0x1cdf, 0x1cdf, 0x1cdf, 0x79ce, 0xb0c4, 0x0cbc, 0x4ed5, 0x4fd5, 0xedc3, 0xccc3, 0x2ed5, 0xafdd, 0x6dd4, 0xcedc, 0x10e6, 0xafe4, 0xcee3, 0xcee3, 0x8fe4, 0x2fe5, 0xcee3,
  0x5ddf, 0x7de7, 0x9eef, 0x7eef, 0x7eef, 0x7def, 0x7def, 0x7def, 0x7de7, 0x7de7, 0x7cef, 0x5aef, 0x59ef, 0x5aef, 0x58ef, 0x36ef, 0x36ef, 0x38ef, 0x7def, 0x7def, 0x5def, 0x38e6, 0x70ec, 0x50ec, 0x0fec, 0x0fec, 0x0fec, 0x50ec, 0x91ec, 0xf2ec, 0x12ed, 0xd2ec, 0xf2ec, 0xf3e4, 0xb2cc, 0x5194, 0x317c, 0x308c, 0x30a4, 0x50ac, 0x70b4, 0x50cc, 0x0fdc, 0x2fd4, 0x75d5, 0x5de7, 0x9def, 0x9ef7, 0x9ef7, 0xbef7, 0xbef7, 0xbef7, 0xbef7, 0xbef7, 0xbef7, 0xbef7, 0xbef7, 0x9ef7, 0x9ef7, 0x9eef, 0x9def, 0x7de7, 0x7de7, 0x7de7, 0x7def, 0x9eef, 0x9ef7, 0x9ef7, 0x9ef7, 0x7def, 0x5de7, 0x1cdf, 0x1cdf, 0x1cdf, 0x1cdf, 0x1cdf, 0x1cdf, 0x1cdf, 0x1cdf, 0x1cdf, 0x1cdf, 0x1cdf, 0x17ce, 0x90c4, 0x6fd5, 0x50e6, 0xeecc, 0xacbb, 0xcecc, 0xefe5, 0xced4, 0x0dcc, 0x6edd, 0x0ed5, 0x6cbb, 0x4cbb, 0xcdcb, 0x4fdd, 0xadc3, 0x8dcb,
  0x5edf, 0x7de7, 0x7eef, 0x7eef, 0x7eef, 0x7eef, 0x9def, 0x7de7, 0x7de7, 0x7de7, 0x7de7, 0x5ce7, 0x5cef, 0x5aef, 0x59ef, 0x7aef, 0x36ef, 0x37ef, 0x7def, 0x7def, 0x7def, 0xdae6, 0xd2e4, 0x71ec, 0x2fec, 0x0fe4, 0x50e4, 0x30ec, 0x91ec, 0xf2ec, 0x13ed, 0xf3ec, 0xd2ec, 0xd2e4, 0x71c4, 0x118c, 0x1174, 0x309c, 0x91c4, 0xd2dc, 0xd2dc, 0x91dc, 0x2fd4, 0x70c4, 0xb6cd, 0x7def, 0x9def, 0x9ef7, 0xbef7, 0xbef7, 0xbef7, 0xbef7, 0xbef7, 0xbef7, 0xbef7, 0xbef7, 0x9ef7, 0x9ef7, 0x9ef7, 0x9eef, 0x9def, 0x7de7, 0x7de7, 0x7de7, 0x7de7, 0x9def, 0x9ef7, 0x9ef7, 0x9ef7, 0x7def, 0x5de7, 0x1cdf, 0x1cdf, 0x1cdf, 0xfcde, 0xfcde, 0x1cdf, 0x1cdf, 0x1cdf, 0x1cdf, 0x1cdf, 0x1cdf, 0xb6cd, 0x91d5, 0xd0dd, 0x10de, 0xeecc, 0x0ecd, 0x50e6, 0x8fdd, 0xecc3, 0x4dcc, 0xafdd, 0x6dcc, 0x2bbb, 0x6cbb, 0x6dc4, 0x6dc4, 0x4bbb, 0x8cbb,
  0x5ddf, 0x7ddf, 0x7eef, 0x7eef, 0x7eef, 0x7eef, 0x9def, 0x7def, 0x7de7, 0x7de7, 0x7def, 0x7de7, 0x7def, 0x7cef, 0x7cef, 0x7aef, 0x37ef, 0x39ef, 0x7de7, 0x7def, 0x7de7, 0x3cef, 0x75e5, 0x71ec, 0x30e4, 0x0fec, 0x2fe4, 0x50ec, 0x71ec, 0xb2ec, 0xf3ec, 0xf3ec, 0xd2ec, 0x91e4, 0x91d4, 0x3194, 0xf07b, 0x0fa4, 0x50c4, 0xb1d4, 0x91d4, 0x70d4, 0x0fcc, 0x91bc, 0xf7cd, 0x7def, 0x9eef, 0x9ef7, 0xbef7, 0xbef7, 0xbef7, 0x9ef7, 0x9ef7, 0x9ef7, 0x9ef7, 0xbef7, 0xbef7, 0x9ef7, 0x9ef7, 0x9ef7, 0x9ef7, 0x7def, 0x7de7, 0x7ddf, 0x7de7, 0x7def, 0x9eef, 0x9ef7, 0x9ef7, 0x7def, 0x3ce7, 0xfcde, 0x1cdf, 0x1cdf, 0x1cdf, 0x1cdf, 0x1cdf, 0xfcd6, 0xfcde, 0xfcde, 0xfcde, 0xfcde, 0x36d6, 0x11de, 0x2ecd, 0x8fd5, 0xf0dd, 0xf0dd, 0x30e6, 0x0ed5, 0x0dc4, 0x6fd5, 0x30e6, 0xeed4, 0xacbb, 0x2dc4, 0x6fd5, 0x4dc4, 0x6dc4, 0xf0dd,
  0x5ddf, 0x5ddf, 0x7ee7, 0x9eef, 0x7eef, 0x7eef, 0x7def, 0x7def, 0x7de7, 0x7def, 0x9def, 0x7def, 0x7de7, 0x7def, 0x9def, 0x7cef, 0x7bef, 0x7cef, 0x7de7, 0x7def, 0x7de7, 0x5ce7, 0x58de, 0x91e4, 0x70e4, 0x2fe4, 0x0fe4, 0x2fec, 0x70ec, 0x91ec, 0xd2ec, 0xf2ec, 0xf2ec, 0x71ec, 0x71dc, 0x31a4, 0xf083, 0xefa3, 0x0fc4, 0x0ed4, 0x0ed4, 0x2fcc, 0x30bc, 0xb2bc, 0x58d6, 0x9eef, 0x9eef, 0x9eef, 0x9ef7, 0x9ef7, 0x9ef7, 0x9ef7, 0x9ef7, 0x9ef7, 0x9eef, 0x9ef7, 0xbef7, 0xbef7, 0xbef7, 0x9ef7, 0x9ef7, 0x9def, 0x7de7, 0x7ddf, 0x7de7, 0x7de7, 0x9eef, 0x9ef7, 0x9ef7, 0x7def, 0x3ce7, 0xfcd6, 0xfcde, 0x1cdf, 0x1cdf, 0x1cdf, 0xfcde, 0xfcde, 0x1cdf, 0x1cdf, 0xfcde, 0xfcde, 0xb6e6, 0x90d5, 0x2dc4, 0x2fd5, 0x10e6, 0xcfdd, 0xefdd, 0x8fdd, 0x4fd5, 0x10de, 0xefdd, 0xcfdd, 0xafdd, 0x6fd5, 0xf0dd, 0x30e6, 0x30e6, 0xafdd,
  0x5ddf, 0x5ddf, 0x7de7, 0x7eef, 0x7eef, 0x7eef, 0x7def, 0x7def, 0x7de7, 0x9eef, 0x9eef, 0x9def, 0x7de7, 0x7de7, 0x9def, 0x9df7, 0x9def, 0x9def, 0x7de7, 0x7def, 0x7de7, 0x5de7, 0xfbe6, 0xf2dc, 0x71ec, 0x2fe4, 0x0fdc, 0x0fe4, 0x50ec, 0x71ec, 0xb1ec, 0xf2ec, 0xf2ec, 0x71ec, 0x71e4, 0x51ac, 0xf083, 0xef9b, 0x0fbc, 0xeecb, 0x0fd4, 0x2fc4, 0x30b4, 0xb2bc, 0xbad6, 0x9eef, 0x9eef, 0x9eef, 0x9ef7, 0x9ef7, 0x9ef7, 0xbef7, 0xbef7, 0x9ef7, 0x9def, 0x9eef, 0x9ef7, 0xbef7, 0xbef7, 0x9ef7, 0x9ef7, 0x9def, 0x7de7, 0x7ddf, 0x7ddf, 0x7de7, 0x9def, 0x9ef7, 0x9ef7, 0x7def, 0x3cdf, 0xfcde, 0xfcde, 0x1cdf, 0x1cdf, 0x1cdf, 0x1cdf, 0x1cdf, 0x1cdf, 0x1cdf, 0xfcde, 0xfcde, 0xd5e6, 0xefcc, 0xecc3, 0x2ed5, 0x2ed5, 0x2ed5, 0x30e6, 0x30e6, 0xefdd, 0x8fd5, 0x4dc4, 0xcdc3, 0xedc3, 0x2cc4, 0xcfdd, 0x4fd5, 0x8dcc, 0x2dbc,
  0x5ddf, 0x5ddf, 0x7de7, 0x7eef, 0x7eef, 0x7eef, 0x7eef, 0x7def, 0x7de7, 0x9eef, 0x9eef, 0x9eef, 0x7de7, 0x7de7, 0x7def, 0x9ef7, 0x9ef7, 0x9eef, 0x7def, 0x7de7, 0x7def, 0x7de7, 0x5cef, 0xb6dd, 0x91e4, 0x2fe4, 0x0edc, 0x2fdc, 0x50ec, 0x70ec, 0x91ec, 0xd2ec, 0xd2ec, 0x91ec, 0x91ec, 0x51b4, 0xf08b, 0xef93, 0xefb3, 0x0fc4, 0x30cc, 0x2fbc, 0x0fb4, 0xd3b4, 0x1bdf, 0x9eef, 0x9eef, 0x9eef, 0xbef7, 0xbef7, 0xbef7, 0xbef7, 0xbef7, 0x9eef, 0x9def, 0x7def, 0x9eef, 0x9ef7, 0xbef7, 0xbef7, 0x9ef7, 0x9eef, 0x7de7, 0x7ddf, 0x7ddf, 0x7de7, 0x7de7, 0x9eef, 0x9ef7, 0x7def, 0x1cdf, 0x1cdf, 0x1cdf, 0x1cdf, 0x1cdf, 0x1cdf, 0xfcd6, 0xfcde, 0x1cdf, 0x1cdf, 0xfcde, 0xfbde, 0x94de, 0x0fd5, 0x0ed5, 0xcfdd, 0x0ed5, 0xcdcc, 0x4fdd, 0x0ed5, 0x2ed5, 0x0ed5, 0x8cc3, 0x4cc3, 0xccc3, 0x4ed5, 0x2ed5, 0x6cbb, 0x4cbb, 0x2fd5,
  0x5ddf, 0x5ddf, 0x7ddf, 0x7de7, 0x7eef, 0x7ee7, 0x7eef, 0x7def, 0x7de7, 0x9def, 0x9eef, 0x9eef, 0x7def, 0x7de7, 0x7de7, 0x9ef7, 0x9ef7, 0x9ef7, 0x9def, 0x7de7, 0x7def, 0x7def, 0x7def, 0xbade, 0xd2d4, 0x50e4, 0x0fdc, 0x0fdc, 0x30e4, 0x50ec, 0x91ec, 0xb2ec, 0xd2ec, 0xb1ec, 0x71ec, 0x50c4, 0x1094, 0xef93, 0x0fac, 0x30bc, 0x50cc, 0x0fcc, 0xefbb, 0x13b5, 0x5ce7, 0x9eef, 0x9eef, 0x9eef, 0x9ef7, 0x9ef7, 0xbef7, 0xbef7, 0xbef7, 0x9eef, 0x7de7, 0x7de7, 0x9def, 0x9ef7, 0xbef7, 0x9ef7, 0x9ef7, 0x9eef, 0x9def, 0x7de7, 0x7ddf, 0x7ddf, 0x7de7, 0x9eef, 0x9ef7, 0x7def, 0x1cdf, 0x1cdf, 0x1cdf, 0x1cdf, 0x1cdf, 0x1cdf, 0xfcde, 0xfcd6, 0xfcd6, 0xfcde, 0xfcde, 0xfcde, 0x54de, 0xf0dd, 0xcfdd, 0xefdd, 0x8fdd, 0xadcc, 0x0cc4, 0x4dcc, 0x0ed5, 0x4dcc, 0x4cc3, 0x8cc3, 0x8dcc, 0xafdd, 0xacc3, 0x4cbb, 0x6cbb, 0x51e6,
  0x7ddf, 0x5dd7, 0x7ddf, 0x7de7, 0x7eef, 0x7de7, 0x7de7, 0x7def, 0x7de7, 0x9def, 0x9eef, 0x9eef, 0x7def, 0x7de7, 0x7de7, 0x9eef, 0x9ef7, 0x9ef7, 0x9def, 0x7def, 0x7def, 0x7def, 0x7def, 0x3ce7, 0x95c5, 0x71dc, 0x2fdc, 0x2fd4, 0x0fe4, 0x50ec, 0x91ec, 0xb2ec, 0xb2ec, 0xb2ec, 0x70ec, 0x50d4, 0x10a4, 0xefa3, 0xefb3, 0x0fac, 0x0fbc, 0xeecb, 0xeec3, 0x34bd, 0x7def, 0x9eef, 0x9eef, 0x9ef7, 0x9ef7, 0x9ef7, 0x9ef7, 0xbef7, 0xbef7, 0x9eef, 0x7de7, 0x5ddf, 0x7de7, 0x9eef, 0x9ef7, 0x9ef7, 0x9ef7, 0x9eef, 0x9eef, 0x7de7, 0x7de7, 0x7de7, 0x7de7, 0x7de7, 0x9def, 0x5def, 0x1cdf, 0x1cdf, 0xfcd6, 0x1cdf, 0x1cdf, 0x1cdf, 0x1cdf, 0x1cdf, 0xfcde, 0xfcde, 0x1cdf, 0xfcde, 0x54de, 0xf0dd, 0xaed4, 0x2edd, 0x8fdd, 0x4dcc, 0xacc3, 0xcdd4, 0x4ed5, 0xacbb, 0x4cbb, 0xcdc3, 0x6fdd, 0xeed4, 0x4cbb, 0x4cbb, 0x8cc3, 0x91ee,
  0x7ddf, 0x5dd7, 0x5ddf, 0x7de7, 0x7eef, 0x7ee7, 0x7de7, 0x7def, 0x7def, 0x7eef, 0x9eef, 0x9eef, 0x7def, 0x7de7, 0x7de7, 0x7def, 0x9ef7, 0x9ef7, 0x9def, 0x7def, 0x7def, 0x7def, 0x7def, 0x7de7, 0xbace, 0x91cc, 0x50dc, 0x2fd4, 0x0fdc, 0x2fe4, 0x71ec, 0xb2ec, 0xd2ec, 0xb2ec, 0x50ec, 0x30dc, 0x10b4, 0xefab, 0xeebb, 0x0fb4, 0x0fb4, 0x0ec4, 0x2fc4, 0x95cd, 0x7def, 0x9def, 0x9eef, 0x9ef7, 0x9ef7, 0x9ef7, 0x9ef7, 0x9ef7, 0x9ef7, 0x9eef, 0x5ddf, 0x3dbf, 0x5dcf, 0x7def, 0x9ef7, 0xbef7, 0x9ef7, 0x9eef, 0x9eef, 0x9def, 0x7de7, 0x7de7, 0x7ddf, 0x7de7, 0x7def, 0x5def, 0x1cdf, 0xfcde, 0xfcde, 0x1cdf, 0x1cdf, 0x1cdf, 0x1cdf, 0x1cdf, 0x1cdf, 0x1cdf, 0x1cdf, 0xfcde, 0xb5e6, 0x4fd5, 0xcccb, 0xaed4, 0xced4, 0x0dcc, 0xaed4, 0xefdd, 0x4ed5, 0x6cbb, 0x4cbb, 0x2dc4, 0xf0e5, 0x2dc4, 0x4cbb, 0x4cbb, 0x2cc4, 0x91e6,
  0x7de7, 0x5dd7, 0x5dd7, 0x7de7, 0x7ee7, 0x7ee7, 0x7de7, 0x7de7, 0x7def, 0x7def, 0x9eef, 0x9eef, 0x9def, 0x7de7, 0x7de7, 0x7de7, 0x9def, 0x9ef7, 0x9eef, 0x7def, 0x7def, 0x7def, 0x7def, 0x7def, 0x3ce7, 0x75c5, 0x71dc, 0x2fcc, 0x2fd4, 0x2fe4, 0x70ec, 0xb1ec, 0xd2ec, 0xb2ec, 0x70ec, 0x50e4, 0x30c4, 0xefab, 0xefb3, 0x2fbc, 0x2fbc, 0x50bc, 0xb1bc, 0x74bd, 0x99ce, 0xbad6, 0x3ce7, 0x7def, 0x7def, 0x5def, 0x7def, 0x5de7, 0x7def, 0x9def, 0x5ddf, 0x1da7, 0x1db7, 0x5ddf, 0x9ef7, 0x9ef7, 0xbef7, 0x9eef, 0x9eef, 0x9def, 0x7def, 0x7de7, 0x7de7, 0x7de7, 0x7de7, 0x5def, 0x1cdf, 0xfcd6, 0xfcde, 0x1cdf, 0xfcde, 0x1cdf, 0xfcde, 0x1cdf, 0x1cdf, 0x1cdf, 0xfcde, 0xfcde, 0xb5e6, 0xcecc, 0x8dd4, 0x6fdd, 0xcecc, 0xeed4, 0xafdd, 0xcfdd, 0x0ed5, 0x6cbb, 0xacbb, 0x0ed5, 0xf0e5, 0x8cbb, 0x4cbb, 0xccc3, 0x6ed5, 0xefdd,
  0x7de7, 0x5dd7, 0x5dd7, 0x5ddf, 0x7de7, 0x7ee7, 0x7de7, 0x7de7, 0x7def, 0x7def, 0x9eef, 0x9eef, 0x9def, 0x7def, 0x7de7, 0x7de7, 0x7def, 0x9ef7, 0x9ef7, 0x9def, 0x7def, 0x7def, 0x7def, 0x7def, 0x7def, 0x9ace, 0x91cc, 0x2fc4, 0x2fc4, 0x2fdc, 0x50e4, 0x91ec, 0xb1ec, 0xd2ec, 0xb2ec, 0xb1e4, 0x71c4, 0x50ac, 0x50ac, 0x70ac, 0x71ac, 0x91a4, 0x919c, 0x719c, 0x7194, 0x9294, 0x55ad, 0x79ce, 0x38ce, 0xb6bd, 0xb6b5, 0x14a5, 0x55ad, 0x79ce, 0x1cd7, 0xfcae, 0xdca6, 0x3dd7, 0x7def, 0x9eef, 0x9eef, 0x9eef, 0x9eef, 0x9eef, 0x9def, 0x7de7, 0x7de7, 0x7de7, 0x7de7, 0x5de7, 0x1cdf, 0x1cdf, 0x1cdf, 0x1cdf, 0xfcd6, 0xfcde, 0xfcd6, 0x1cdf, 0x1cdf, 0x1cdf, 0x1cdf, 0xfcde, 0x35d6, 0x4fcd, 0x8fd5, 0xafdd, 0xafdd, 0x6fdd, 0xadcc, 0x2ed5, 0x8ed5, 0x2dbc, 0xadcc, 0x2ecd, 0xf0dd, 0xacbb, 0x2dc4, 0x8fdd, 0xcdcc, 0x0fe6,
  0x7de7, 0x5ddf, 0x5dd7, 0x5ddf, 0x7de7, 0x7eef, 0x7de7, 0x7de7, 0x7def, 0x7def, 0x9eef, 0x9eef, 0x9ef7, 0x7def, 0x7de7, 0x7de7, 0x7de7, 0x9eef, 0x9ef7, 0x7def, 0x7def, 0x7def, 0x7def, 0x7def, 0x7def, 0x5ce7, 0x34bd, 0x30c4, 0x0fbc, 0x2fcc, 0x70e4, 0x91e4, 0xb1ec, 0xd1e4, 0xb1d4, 0x91c4, 0x71ac, 0x719c, 0x919c, 0x919c, 0x5094, 0xef8b, 0x8e7b, 0x4d73, 0x0c6b, 0xaa5a, 0xcb62, 0xcf83, 0xef83, 0x8e7b, 0xcf83, 0xcf7b, 0x8e73, 0x3084, 0x349d, 0x5695, 0xd895, 0xbbbe, 0x5de7, 0x7def, 0x9def, 0x9def, 0x9def, 0x9eef, 0x9eef, 0x9def, 0x7de7, 0x7ddf, 0x7de7, 0x5ce7, 0x1cdf, 0xfcd6, 0xfcd6, 0xfcde, 0xfcd6, 0xfcd6, 0xfcde, 0xfcde, 0xfcd6, 0x1cdf, 0x1cdf, 0x1cdf, 0xf6cd, 0xf1dd, 0xcdd4, 0x2ed5, 0x10de, 0xcecc, 0x8cbb, 0x8dcc, 0x30e6, 0xefdd, 0x6dc4, 0x6dcc, 0x70e6, 0x10de, 0xf0dd, 0x8dc4, 0xadcc, 0x6ed5,
  0x7de7, 0x5ddf, 0x5dd7, 0x5edf, 0x7de7, 0x7eef, 0x7de7, 0x7de7, 0x7def, 0x7def, 0x9def, 0x9def, 0x9eef, 0x9eef, 0x7def, 0x5de7, 0x7de7, 0x7def, 0x9ef7, 0x9def, 0x7def, 0x7def, 0x7def, 0x7def, 0x7def, 0x7de7, 0x58ce, 0x50bc, 0x0fb4, 0x2fc4, 0x70dc, 0x70dc, 0x70dc, 0x90cc, 0x2fb4, 0x0f9c, 0x3094, 0x719c, 0x919c, 0x308c, 0xae7b, 0xae7b, 0x0f84, 0xce7b, 0x0c6b, 0x2852, 0x074a, 0x695a, 0x895a, 0x8a5a, 0x2c6b, 0xef83, 0x0f8c, 0x6d7b, 0x107c, 0xd37c, 0x7374, 0x7695, 0xdbce, 0x5de7, 0x5de7, 0x5de7, 0x7de7, 0x9def, 0x9def, 0x7def, 0x7de7, 0x7de7, 0x7de7, 0x5de7, 0x1cdf, 0xfcde, 0xfcde, 0xfcde, 0xfcde, 0xfcd6, 0xfcde, 0xfcde, 0xfcd6, 0xfcde, 0x1cdf, 0x1cdf, 0x77d6, 0x70d5, 0xecc3, 0xeed4, 0x6fd5, 0x0dc4, 0x4cbb, 0x8cbb, 0x2dc4, 0x4ec4, 0x4bb3, 0x2dc4, 0x0fde, 0xcfdd, 0xccc3, 0x6cc3, 0xafdd, 0x6dcc,
  0x7de7, 0x5ddf, 0x5dd7, 0x5dd7, 0x7ddf, 0x7ee7, 0x7de7, 0x7de7, 0x7def, 0x7def, 0x7def, 0x9def, 0x9def, 0x9eef, 0x7def, 0x7de7, 0x5de7, 0x7def, 0x9ef7, 0x9ef7, 0x9def, 0x7def, 0x7def, 0x7def, 0x7def, 0x7def, 0x3cdf, 0xf3bc, 0x50bc, 0x50bc, 0x50cc, 0x50d4, 0x50c4, 0x70b4, 0x70ac, 0x509c, 0x5094, 0x919c, 0x719c, 0xcf83, 0x6d73, 0xae7b, 0xcf7b, 0x0c6b, 0x6952, 0x6952, 0x4852, 0x895a, 0x0752, 0xa641, 0x084a, 0x2c6b, 0x4c73, 0xcb62, 0xcb62, 0x4d6b, 0xae6b, 0xcf73, 0x75a5, 0x79ce, 0x9ace, 0xbace, 0xfbd6, 0x5ce7, 0x7def, 0x9def, 0x7de7, 0x7de7, 0x7de7, 0x5de7, 0x1cdf, 0xfcde, 0x1cdf, 0x1cdf, 0xfcde, 0xfcd6, 0xfcd6, 0xfcde, 0xfcde, 0xfcde, 0xfcde, 0xfcde, 0x97de, 0xafcc, 0xecc3, 0x4ed5, 0xeed4, 0xacc3, 0xccc3, 0x2dc4, 0x4dc4, 0xccc3, 0xacc3, 0xcdcc, 0x2ed5, 0x0dd5, 0x2bbb, 0xabc3, 0x30e6, 0xaccb,
  0x7de7, 0x5ddf, 0x5dd7, 0x5dd7, 0x7ddf, 0x7de7, 0x7ee7, 0x7ee7, 0x7def, 0x7def, 0x7def, 0x9def, 0x9def, 0x9eef, 0x9def, 0x7de7, 0x5ddf, 0x7de7, 0x9eef, 0x9ef7, 0x9eef, 0x7def, 0x7def, 0x7def, 0x7de7, 0x7def, 0x5de7, 0xf7c5, 0x91b4, 0x70bc, 0x70bc, 0x91bc, 0x70ac, 0x509c, 0x5094, 0xef8b, 0xae83, 0xce83, 0xce83, 0x6d73, 0x0c6b, 0x2c6b, 0xeb62, 0x4852, 0x695a, 0xea72, 0x0b73, 0x4b7b, 0x0a7b, 0x685a, 0xe749, 0x4952, 0x4952, 0x084a, 0xaa5a, 0x4d73, 0x6d73, 0x6d73, 0x308c, 0x55ad, 0x17be, 0x99c6, 0xbace, 0xfbd6, 0x5ce7, 0x7def, 0x7def, 0x7de7, 0x7de7, 0x5de7, 0x1cdf, 0x1cdf, 0x1cdf, 0x1cdf, 0x1cdf, 0x1cdf, 0x1cdf, 0x1cdf, 0xfcde, 0xfcde, 0xfcde, 0xfcde, 0x37d6, 0x4fc4, 0xeed4, 0x10e6, 0x0ed5, 0xadcc, 0x6dcc, 0x4dc4, 0xaecc, 0x8cc3, 0x4dcc, 0xcfdd, 0x4ed5, 0x2ccc, 0x2bc3, 0x0ccc, 0x50e6, 0x4bc3,
  0x9def, 0x7ddf, 0x5dd7, 0x5dd7, 0x7ddf, 0x7de7, 0x7eef, 0x7ee7, 0x7def, 0x7def, 0x7def, 0x7def, 0x9def, 0x9eef, 0x9eef, 0x7de7, 0x5ddf, 0x7de7, 0x9def, 0x9ef7, 0x9ef7, 0x7def, 0x7def, 0x7de7, 0x7de7, 0x5de7, 0x3cdf, 0x9ace, 0xf3bc, 0x70b4, 0x91bc, 0xd2b4, 0x509c, 0xae83, 0x4d73, 0x0c6b, 0xeb6a, 0x2c73, 0x6d73, 0x2c6b, 0xeb62, 0xaa5a, 0x8a62, 0x0a7b, 0x2ea4, 0x31c5, 0x73c5, 0xd5cd, 0xb4d5, 0x8fb4, 0xea72, 0x2752, 0xa641, 0xa741, 0xaa5a, 0x0c63, 0x0c6b, 0x2c6b, 0x8e7b, 0xef83, 0xd29c, 0xb6ad, 0xf7b5, 0xf7bd, 0xbad6, 0x5de7, 0x7de7, 0x7de7, 0x7de7, 0x5de7, 0x1cdf, 0x1cdf, 0x1cdf, 0x1cdf, 0xfcd6, 0x1cdf, 0x1cdf, 0x1cdf, 0xfcd6, 0xfcde, 0xfcde, 0x1cdf, 0xb6cd, 0xafc4, 0x6fd5, 0x10de, 0xefdd, 0xcdcc, 0xecc3, 0x8dcc, 0x0ed5, 0x6dcc, 0x2ed5, 0x6ed5, 0x6edd, 0x6bbb, 0x2bc3, 0x8dd4, 0x50e6, 0x4dd4,
  0x9eef, 0x7de7, 0x5ddf, 0x5dd7, 0x7ddf, 0x7de7, 0x7de7, 0x7de7, 0x7def, 0x9def, 0x7def, 0x7def, 0x9def, 0x9def, 0x9ef7, 0x7def, 0x5ddf, 0x5ddf, 0x7def, 0x9ef7, 0x9ef7, 0x7def, 0x7def, 0x7def, 0x7ddf, 0x5ddf, 0x3cdf, 0xfcde, 0x75bd, 0xd2b4, 0xb1b4, 0x50a4, 0x8d7b, 0x4d73, 0x0c6b, 0x8a5a, 0x4952, 0x695a, 0xaa62, 0xca62, 0xca62, 0xaa62, 0xa96a, 0xcd9b, 0xd4dd, 0xb8e6, 0x1aef, 0x3bf7, 0x1aef, 0x36e6, 0x6ebc, 0x0a83, 0x275a, 0xa639, 0x8a5a, 0x0c63, 0xeb62, 0xcb62, 0x0c6b, 0x4d73, 0x8d7b, 0x518c, 0x75a5, 0xd7b5, 0x17be, 0xbace, 0x3cdf, 0x7de7, 0x7de7, 0x7de7, 0x3cdf, 0x1cdf, 0x1cdf, 0x1cdf, 0xfcd6, 0xfcde, 0xfcde, 0xfcd6, 0xfcd6, 0xfcde, 0x1cdf, 0x1bdf, 0xb6cd, 0x91d5, 0xeecc, 0x4ed5, 0xafdd, 0x6dcc, 0xccc3, 0xadcc, 0x6fd5, 0xcfdd, 0x4ed5, 0xcdcc, 0x6ed5, 0x2bbb, 0x6bc3, 0x6fd5, 0x50e6, 0xafdd,
  0x9def, 0x7de7, 0x7de7, 0x5dd7, 0x7ddf, 0x7de7, 0x7de7, 0x7de7, 0x7def, 0x9def, 0x7def, 0x9def, 0x9def, 0x9def, 0x9ef7, 0x7def, 0x7de7, 0x5ddf, 0x7de7, 0x9ef7, 0x9ef7, 0x7def, 0x7def, 0x7def, 0x5ddf, 0x3cd7, 0xdbce, 0xdbd6, 0x17c6, 0x33b5, 0x70a4, 0x8d83, 0xca6a, 0x0b6b, 0x2c6b, 0xaa62, 0x084a, 0xc741, 0x284a, 0x4952, 0x695a, 0xca6a, 0x2b83, 0x2eac, 0x56e6, 0x1aef, 0x5bf7, 0x5cf7, 0x3bf7, 0xd9ee, 0x92dd, 0xeca3, 0xc96a, 0x6952, 0x8a5a, 0x8a5a, 0x8a5a, 0xaa5a, 0xeb6a, 0x2c6b, 0x4d73, 0x8e7b, 0x9194, 0xf7b5, 0x99ce, 0x38c6, 0x79ce, 0x3cdf, 0x7de7, 0x7de7, 0x3ce7, 0x1cdf, 0x1cdf, 0x1cdf, 0x1cdf, 0xfcde, 0xfcde, 0xfcd6, 0xfbd6, 0xfcd6, 0x1cdf, 0xfcde, 0xf6d5, 0xd1dd, 0x8edc, 0xeedc, 0x2edd, 0x2dd4, 0x0dcc, 0x6ed4, 0x2fdd, 0x6fdd, 0x4dd4, 0x0ed5, 0x6edd, 0x6cc3, 0x2dcc, 0xf0dd, 0xaee5, 0x0cd4,
  0x9eef, 0x7def, 0x7def, 0x7ddf, 0x7de7, 0x7ee7, 0x7de7, 0x7de7, 0x7def, 0x9def, 0x9def, 0x9def, 0x7def, 0x7def, 0x9ef7, 0x9eef, 0x7de7, 0x5ddf, 0x7ddf, 0x9def, 0x9ef7, 0x7def, 0x7def, 0x5de7, 0x3cdf, 0x39be, 0xd394, 0xb29c, 0x54ad, 0xd2a4, 0x8d83, 0xaa62, 0xca62, 0x2c73, 0x8d7b, 0x6d7b, 0xaa62, 0xe749, 0xe741, 0x8a5a, 0xca62, 0xca6a, 0x8c8b, 0xf1bc, 0xd9ee, 0x3bf7, 0x5cf7, 0x7cf7, 0x5cf7, 0x1aef, 0x56e6, 0x6eb4, 0x6962, 0xaa5a, 0xcb62, 0xaa5a, 0x8a5a, 0xaa62, 0xeb62, 0xeb62, 0x0c6b, 0x4d73, 0xef83, 0x55ad, 0x9ace, 0x79c6, 0x9ace, 0x3cdf, 0x7de7, 0x7de7, 0x5de7, 0x1cdf, 0xfcde, 0x1cdf, 0x1cdf, 0xfcde, 0xfcde, 0xfcd6, 0xfbd6, 0xfbd6, 0xfcde, 0xfcde, 0x56de, 0x92e5, 0xafe4, 0x70e5, 0x2fe5, 0x4ee4, 0xafdc, 0x0fdd, 0x2fe5, 0xaee4, 0xcde3, 0x2ee5, 0xcfe5, 0x4ddc, 0x8fe5, 0x6fe5, 0x2ee5, 0x2be3,
  0x9ef7, 0x9def, 0x7def, 0x7de7, 0x7de7, 0x7eef, 0x7eef, 0x7eef, 0x7def, 0x9def, 0x9def, 0x9def, 0x9def, 0x7def, 0x9eef, 0x9ef7, 0x7def, 0x5ddf, 0x5dd7, 0x7def, 0x9eef, 0x7def, 0x7def, 0x5ce7, 0x9ac6, 0x96a5, 0xd38c, 0x8e73, 0xae83, 0xae83, 0xeb6a, 0xaa62, 0x0b73, 0x6d7b, 0x8d7b, 0x4c73, 0x895a, 0xe749, 0x084a, 0xaa62, 0xea6a, 0xea72, 0xcc9b, 0x93d5, 0xf9ee, 0x5cf7, 0x7cf7, 0x7dff, 0x7cf7, 0x5bf7, 0xf9ee, 0xd0c4, 0x686a, 0x2852, 0x4952, 0x6952, 0xeb62, 0x0c6b, 0xeb62, 0x8a5a, 0x8a5a, 0xeb6a, 0x8e7b, 0xb29c, 0xd6b5, 0xf7bd, 0xbace, 0xfbd6, 0x3cdf, 0x5ddf, 0x5de7, 0x1cdf, 0x1cdf, 0xfcde, 0xfcde, 0xfcde, 0xfcd6, 0x1cdf, 0xfcd6, 0xfcd6, 0xfcde, 0xfcde, 0x97e6, 0xd4ed, 0xb2ed, 0x31ee, 0xd1ed, 0x72e5, 0x92e5, 0xb2e5, 0xd1e5, 0x32ed, 0xd2ec, 0xb1ed, 0x70ee, 0xd0ed, 0xd2ed, 0x70e5, 0x50e5, 0xefeb,
  0x9ef7, 0x9def, 0x7def, 0x7def, 0x7def, 0x7eef, 0x7def, 0x7eef, 0x7eef, 0x9eef, 0x9def, 0x9def, 0x9def, 0x9def, 0x9def, 0x9ef7, 0x9eef, 0x7de7, 0x5dd7, 0x7de7, 0x9def, 0x9def, 0x7def, 0x3ce7, 0xf8b5, 0xd7ad, 0xb6a5, 0x1084, 0x2c73, 0xeb6a, 0xaa62, 0xaa62, 0x6d7b, 0x8d7b, 0xcb62, 0x284a, 0xa641, 0xa639, 0xe749, 0x4852, 0x8962, 0x2b7b, 0x2ea4, 0x72d5, 0x76e6, 0xf8ee, 0x1af7, 0x3bf7, 0x3af7, 0x1af7, 0xf9ee, 0x31cd, 0xea7a, 0x285a, 0xc749, 0x4852, 0x4d73, 0xcb62, 0x4952, 0x284a, 0xe741, 0x4852, 0x0b6b, 0xb294, 0xf7b5, 0xf7b5, 0xbace, 0xfbd6, 0x1bd7, 0x5ddf, 0x7de7, 0x1cdf, 0xfcde, 0xfcde, 0xfcde, 0xfcde, 0x1cdf, 0xfcde, 0xfcd6, 0xfcd6, 0xfcde, 0xfcde, 0x77e6, 0xf4ed, 0x33ee, 0x33ee, 0xf3ed, 0x32ee, 0x13ee, 0xf3ed, 0x12ee, 0xb5ed, 0x95ed, 0x12ee, 0x52ee, 0xf3ed, 0x95ed, 0xf2ed, 0xd2ed, 0x55ed,
  0x9ef7, 0x9eef, 0x9def, 0x9def, 0x9def, 0x9def, 0x9def, 0x9eef, 0x9eef, 0x9eef, 0x9eef, 0x9eef, 0x9eef, 0x9def, 0x9def, 0x9eef, 0x9ef7, 0x7de7, 0x5dd7, 0x5ddf, 0x9def, 0x7def, 0x7def, 0x3ce7, 0x18b6, 0x149d, 0x55a5, 0x108c, 0x0c73, 0xeb6a, 0xeb6a, 0xeb6a, 0x8e7b, 0x8e73, 0x0c63, 0x895a, 0xc741, 0x8639, 0xc741, 0xc749, 0xc749, 0x4852, 0xca6a, 0x4b7b, 0x4eac, 0x92d5, 0x55e6, 0x97ee, 0x55e6, 0xd4dd, 0x52cd, 0xed9b, 0x8962, 0x2852, 0xc749, 0x4852, 0x8a5a, 0xe741, 0xe741, 0xc741, 0x8639, 0xa641, 0x2852, 0x3084, 0x17be, 0x58c6, 0xdbd6, 0x1cd7, 0x1cd7, 0x5ddf, 0x7de7, 0x3ce7, 0xfcde, 0x1cdf, 0xfcde, 0xfcde, 0xfcde, 0xfcde, 0xfcd6, 0xfcde, 0xfcde, 0xfbde, 0x17e6, 0x13ee, 0x13ee, 0xb5ed, 0xd4ed, 0x52ee, 0x52ee, 0x32ee, 0x32ee, 0xd5ed, 0xd4ed, 0x51ee, 0x13ee, 0xb5ed, 0x95ed, 0x12ee, 0x13ee, 0xb5ed,
  0x9eef, 0x9def, 0x9def, 0x9def, 0x9def, 0x9eef, 0x9eef, 0x9eef, 0x9def, 0x9eef, 0x9eef, 0x9eef, 0x9eef, 0x9eef, 0x9eef, 0x9eef, 0x9ef7, 0x9eef, 0x7ddf, 0x5dd7, 0x7de7, 0x7def, 0x7def, 0x5ce7, 0xdbc6, 0x3184, 0xae7b, 0x4d73, 0xaa62, 0x495a, 0xeb6a, 0x0b6b, 0xaa62, 0x6952, 0x084a, 0x4952, 0x284a, 0xe749, 0x695a, 0xea72, 0x6b8b, 0x2ea4, 0x4ea4, 0x4b83, 0x2983, 0x4db4, 0xd2e5, 0x55e6, 0x71dd, 0xcba3, 0x2b7b, 0x8d83, 0x2b73, 0x8962, 0x8639, 0x6539, 0x8639, 0x8639, 0x8639, 0x6639, 0x2531, 0x4531, 0xe749, 0x2c6b, 0xd29c, 0x38be, 0xfbd6, 0x1cdf, 0x3cdf, 0x5ddf, 0x7de7, 0x5de7, 0xfcde, 0xfcde, 0x1cdf, 0xfcde, 0xfcde, 0xfcd6, 0xfcd6, 0xfcd6, 0xfcde, 0xfbde, 0x37e6, 0x33ee, 0xf4ed, 0x96ed, 0x13ee, 0x32ee, 0xf3ed, 0x13ee, 0x13ee, 0x33ee, 0x13ee, 0x13ee, 0x33ee, 0x96ed, 0x96f5, 0x13ee, 0x71ee, 0x71ee,
  0x9def, 0x7def, 0x7def, 0x7def, 0x9def, 0x9eef, 0x9eef, 0x9eef, 0x9eef, 0x9eef, 0x9eef, 0x9eef, 0x9eef, 0x9eef, 0x9eef, 0x9eef, 0x9ef7, 0x9eef, 0x7de7, 0x5ddf, 0x7ddf, 0x9def, 0x7def, 0x5ce7, 0xbbc6, 0x8e73, 0x084a, 0xaa5a, 0xaa5a, 0x4952, 0xeb62, 0xca62, 0xe749, 0xa741, 0xc741, 0x8639, 0xe749, 0xeb6a, 0x4c7b, 0x4a8b, 0x0dac, 0x31cd, 0xb3d5, 0xafbc, 0xcc9b, 0xcba3, 0xb2dd, 0x35e6, 0xcfcc, 0xeca3, 0x8fb4, 0x8fb4, 0x8fb4, 0x4a83, 0x8541, 0x6539, 0x8639, 0x8639, 0xa639, 0x6531, 0x0429, 0x2529, 0xe749, 0x4852, 0x0852, 0xcb62, 0xb29c, 0x99ce, 0x3cdf, 0x5ddf, 0x7de7, 0x7de7, 0x1cdf, 0xfcde, 0xfcde, 0xfcde, 0xfcde, 0xfcd6, 0xfcd6, 0xfcd6, 0xfcde, 0xdbde, 0x55e6, 0x13ee, 0xb5ed, 0x95ed, 0x32ee, 0x13ee, 0x96ed, 0xb5ed, 0xf4ed, 0x71ee, 0x33ee, 0xd4ed, 0x52ee, 0x95ed, 0x95ed, 0x13ee, 0x33ee, 0xd4ed,
  0x7def, 0x7def, 0x7def, 0x7def, 0x9def, 0x9eef, 0x9eef, 0x9ef7, 0x9eef, 0x9eef, 0x9eef, 0x9ef7, 0x9ef7, 0x9eef, 0x9eef, 0x7def, 0x9eef, 0x9eef, 0x7def, 0x5ddf, 0x5ddf, 0x7de7, 0x7def, 0x5ce7, 0xbbc6, 0xab5a, 0x6631, 0xa639, 0xe741, 0x8a52, 0x8a52, 0x284a, 0xa639, 0x4531, 0x8639, 0x8639, 0xa641, 0x275a, 0x896a, 0xc972, 0x8b93, 0x4eac, 0xafb4, 0x8fb4, 0x6eb4, 0x2db4, 0x76ee, 0xb8ee, 0xaec4, 0x6eb4, 0x4eac, 0x4eb4, 0xb0bc, 0x4a93, 0xa549, 0xa641, 0xa639, 0xc741, 0xe749, 0x6639, 0x2429, 0x4531, 0xa639, 0xe749, 0x0852, 0xaa62, 0x8d7b, 0xf3a4, 0x1bdf, 0x5de7, 0x7de7, 0x9eef, 0x3cdf, 0xfcde, 0xfcde, 0xfcde, 0xfcde, 0xfbd6, 0xfbd6, 0xfcd6, 0xfcde, 0xbade, 0x74e6, 0xf3ed, 0x95ed, 0xb5ed, 0x32ee, 0xf3ed, 0xd5ed, 0xd5ed, 0xb4ed, 0x13ee, 0xf5ed, 0xb4ed, 0x31ee, 0x95ed, 0xb4ed, 0x32ee, 0x95ed, 0x75ed,
  0x7def, 0x7def, 0x7def, 0x7def, 0x9def, 0x9eef, 0x9eef, 0x9ef7, 0x9eef, 0x9eef, 0x9ef7, 0x9ef7, 0x9ef7, 0x9eef, 0x9eef, 0x7de7, 0x9def, 0x9ef7, 0x7def, 0x5ddf, 0x5ddf, 0x5ddf, 0x5de7, 0x3ce7, 0x79be, 0x4952, 0x4529, 0x2529, 0x4531, 0x6531, 0x4529, 0x4529, 0x2429, 0x0429, 0x6539, 0xe749, 0x275a, 0xa86a, 0xe972, 0xc972, 0x0a7b, 0x8c93, 0x4eac, 0xd0bc, 0x11cd, 0x31cd, 0x1af7, 0xd8ee, 0xd0cc, 0x10c5, 0x0d9c, 0x8b83, 0xab83, 0xe972, 0xc649, 0xa641, 0xa641, 0x8639, 0x4531, 0x4531, 0xa639, 0xa641, 0xc641, 0x084a, 0x4952, 0x895a, 0xca6a, 0x308c, 0xbace, 0x5de7, 0x7de7, 0x9eef, 0x5de7, 0xfcde, 0xfcde, 0x1cdf, 0xfcde, 0xfbd6, 0xfbd6, 0xfcd6, 0xfbde, 0xb9e6, 0x53ee, 0xd4ed, 0x96ed, 0xf4ed, 0x71ee, 0x32ee, 0xd4ed, 0xb5ed, 0xd4ed, 0x32ee, 0xd5ed, 0xb4ed, 0x51ee, 0xf3ed, 0x32ee, 0xd4ed, 0x95ed, 0x76ed,
  0x7def, 0x7def, 0x7def, 0x7def, 0x9def, 0x9eef, 0x9ef7, 0x9ef7, 0x9eef, 0x9def, 0x9eef, 0x9ef7, 0x9ef7, 0x9ef7, 0x9def, 0x7de7, 0x7de7, 0x9def, 0x7def, 0x7de7, 0x5ddf, 0x5ddf, 0x5de7, 0x3cdf, 0xd394, 0xe741, 0x6531, 0x2429, 0x2529, 0x2429, 0x0421, 0x0421, 0x0421, 0x0421, 0x4431, 0x275a, 0xe97a, 0x8a93, 0x2cac, 0x6dbc, 0xafbc, 0x10c5, 0x72d5, 0xb2dd, 0x30d5, 0x93dd, 0x3af7, 0xf9f6, 0x92dd, 0x91dd, 0x72d5, 0x6eac, 0xab8b, 0xc872, 0x4762, 0xc649, 0x8539, 0x4531, 0x4531, 0x4531, 0x6531, 0x8639, 0x8639, 0x8639, 0xc741, 0x074a, 0xca62, 0xb29c, 0xfbd6, 0x5de7, 0x7de7, 0x9eef, 0x7de7, 0x1cdf, 0xfcde, 0x1cdf, 0xfcde, 0xfcde, 0xfbd6, 0xfcd6, 0xfcde, 0xd8e6, 0x34ee, 0xb5ed, 0xb5ed, 0x13ee, 0x71ee, 0x51ee, 0xf3ed, 0x94ed, 0xf3ed, 0x32ee, 0xb5ed, 0xb5ed, 0x32ee, 0x71ee, 0x13ee, 0xb5ed, 0x95ed, 0xb4ed,
  0x7def, 0x7def, 0x7def, 0x9def, 0x7def, 0x9def, 0x9ef7, 0x9ef7, 0x9eef, 0x9def, 0x9eef, 0x9ef7, 0x9ef7, 0x9ef7, 0x9def, 0x7de7, 0x7de7, 0x7def, 0x7def, 0x7de7, 0x5ddf, 0x5ddf, 0x5de7, 0x1cd7, 0x4e6b, 0xc741, 0xc739, 0x6531, 0x6531, 0x2529, 0x0421, 0xe420, 0xe420, 0x0429, 0x8541, 0x8772, 0x8a9b, 0x2cb4, 0xefcc, 0x91dd, 0x34e6, 0x96e6, 0x55e6, 0x92dd, 0x10d5, 0xf3e5, 0x1af7, 0x19f7, 0x34ee, 0x71dd, 0xf3e5, 0xb2dd, 0xefc4, 0x2cac, 0x8a93, 0xc87a, 0x065a, 0x8541, 0x8639, 0x4531, 0x2429, 0x2429, 0x4531, 0x6531, 0x8639, 0xc749, 0xeb6a, 0x34a5, 0x3cdf, 0x7de7, 0x7de7, 0x7de7, 0x9def, 0x1cdf, 0x1cdf, 0xfcde, 0x1cdf, 0xfbde, 0xfbd6, 0xfcd6, 0xfcde, 0xd7e6, 0x15ee, 0xb6ed, 0xf4ed, 0x13ee, 0xf3ed, 0x33ee, 0xf3ed, 0xb4ed, 0x32ee, 0x33ee, 0xb5ed, 0xb5ed, 0x32ee, 0x32ee, 0xb5ed, 0xd5ed, 0xd4ed, 0x32ee,
  0x7de7, 0x7def, 0x7def, 0x7def, 0x7def, 0x9def, 0x9eef, 0x9ef7, 0x9ef7, 0x9def, 0x9eef, 0x9ef7, 0x9ef7, 0x9ef7, 0x9def, 0x7de7, 0x7de7, 0x7de7, 0x7def, 0x7de7, 0x5ddf, 0x5ddf, 0x5ddf, 0x1cdf, 0xcf7b, 0xc739, 0xc739, 0x8631, 0x6631, 0x4529, 0x2429, 0x0429, 0x0429, 0x4439, 0x4762, 0x298b, 0xcbab, 0x8ec4, 0x30dd, 0xb2e5, 0x14e6, 0x35e6, 0xb2dd, 0x50dd, 0xb2e5, 0xb2e5, 0x35ee, 0x96ee, 0x54ee, 0x14e6, 0x91e5, 0xf3e5, 0xd3dd, 0x10cd, 0x6dbc, 0xcbab, 0xc882, 0xc551, 0x4531, 0x2429, 0x0429, 0x0429, 0x2429, 0x4531, 0x6539, 0xc741, 0x0c6b, 0xb6b5, 0x5ce7, 0x7de7, 0x7de7, 0x7de7, 0x9eef, 0x5de7, 0x1cdf, 0x1cdf, 0x1cdf, 0xfbde, 0xfbd6, 0xfbd6, 0xfbd6, 0x97e6, 0xd6ed, 0xb6ed, 0x33ee, 0x14ee, 0xf5ed, 0x34ee, 0xf3ed, 0xf3ed, 0x32ee, 0xf3ed, 0xd5ed, 0xd4ed, 0x51ee, 0x12ee, 0x96f5, 0xd5ed, 0x32ee, 0x13ee,
  0x7de7, 0x7de7, 0x7de7, 0x7def, 0x7def, 0x9def, 0x9eef, 0x9ef7, 0x9ef7, 0x9eef, 0x9eef, 0x9ef7, 0x9ef7, 0x9ef7, 0x9def, 0x7de7, 0x7ddf, 0x7de7, 0x7def, 0x7de7, 0x7de7, 0x5ddf, 0x5ddf, 0x3cdf, 0xd7b5, 0xcb52, 0x8631, 0x4529, 0x2429, 0x0421, 0x2429, 0x6539, 0x8541, 0xe651, 0xc872, 0x8b9b, 0x0cac, 0xaec4, 0x30dd, 0xb2e5, 0xb2e5, 0x51dd, 0xaecc, 0x2cbc, 0x0cb4, 0x8aa3, 0x4cbc, 0xaec4, 0x4dbc, 0x50d5, 0x30dd, 0xefd4, 0x72dd, 0x31dd, 0xaed4, 0xaecc, 0xcaab, 0x2662, 0x2431, 0xe420, 0xe320, 0xe320, 0x0429, 0x2429, 0x6531, 0xc741, 0x0c6b, 0x96b5, 0xfbde, 0x5de7, 0x5de7, 0x7de7, 0x9eef, 0x7de7, 0x1cdf, 0xfcde, 0xfcde, 0xfbd6, 0xdbd6, 0xfbd6, 0xfbd6, 0x38e6, 0xb6ed, 0xd5ed, 0x33ee, 0xf4ed, 0x14ee, 0x33ee, 0x13ee, 0x12ee, 0x13ee, 0xf4ed, 0xf3ed, 0x12ee, 0x31ee, 0x12ee, 0x95f5, 0xf3ed, 0x12ee, 0xb6ed,
  0x5ddf, 0x7de7, 0x7de7, 0x7de7, 0x7def, 0x9def, 0x9eef, 0x9ef7, 0x9ef7, 0x9ef7, 0x9ef7, 0x9eef, 0x9def, 0x7def, 0x7def, 0x7de7, 0x7ddf, 0x7de7, 0x7de7, 0x7de7, 0x7de7, 0x5ddf, 0x3dd7, 0x1cd7, 0xfbd6, 0x96a5, 0x4e5b, 0xa731, 0x2529, 0x0421, 0x2439, 0xc651, 0x686a, 0xe97a, 0x6b8b, 0xeca3, 0x2db4, 0x8ec4, 0x0fd5, 0x50dd, 0x50dd, 0x0fd5, 0x6dc4, 0x299b, 0x877a, 0x6772, 0xe892, 0x6aa3, 0x299b, 0xaab3, 0x50dd, 0xefd4, 0xefdc, 0x30dd, 0x10dd, 0x0fdd, 0x6dc4, 0xc882, 0x6439, 0xe428, 0xe420, 0xe320, 0x0421, 0x2429, 0x6539, 0xc741, 0x0b6b, 0x34a5, 0x38be, 0x3cdf, 0x5ddf, 0x7de7, 0x9eef, 0x9eef, 0x5de7, 0x1cdf, 0xfcde, 0xfbd6, 0xdbd6, 0xfbd6, 0xfbde, 0x18ee, 0x96ed, 0x13ee, 0x13ee, 0xd5ed, 0x14ee, 0x13ee, 0x13ee, 0x13ee, 0xd4ed, 0x13ee, 0x71ee, 0x31ee, 0xf3ed, 0x12ee, 0xb4ed, 0x11ee, 0xb4ed, 0x96f5,
  0x3dc7, 0x7ddf, 0x7ddf, 0x7de7, 0x7de7, 0x9def, 0x9eef, 0x9ef7, 0x9ef7, 0x9ef7, 0x9ef7, 0x9eef, 0x7def, 0x7def, 0x7def, 0x7de7, 0x7de7, 0x7ddf, 0x7de7, 0x7de7, 0x7de7, 0x5ddf, 0xfcce, 0xdbce, 0xfbd6, 0xbbc6, 0xf89d, 0x4e5b, 0x493a, 0x8631, 0x8541, 0xe659, 0xa87a, 0x8b93, 0x0da4, 0x2dac, 0x4db4, 0x6dc4, 0xaecc, 0xced4, 0xefd4, 0x10d5, 0xaecc, 0xcbab, 0x6a9b, 0x8ba3, 0x2db4, 0xb0cc, 0xafcc, 0xaecc, 0xd2e5, 0x91e5, 0xced4, 0xced4, 0xefdc, 0x30dd, 0xced4, 0x699b, 0xc551, 0x2431, 0x0429, 0xe420, 0xe420, 0x2429, 0x8639, 0x4952, 0x8e73, 0xb294, 0x55ad, 0xbace, 0x5ddf, 0x7de7, 0x9def, 0x9eef, 0x9eef, 0x3cdf, 0xfcde, 0xfbde, 0xfbd6, 0xfbd6, 0xfbde, 0xf8ed, 0xb6ed, 0x32ee, 0xf3ed, 0x95ed, 0xf4ed, 0x12ee, 0xd3ed, 0xd4ed, 0x95ed, 0xd4ed, 0x31ee, 0xf2ed, 0x94ed, 0x31ee, 0x12ee, 0xd2ed, 0xb5ed, 0x96ed,
  0x3daf, 0x5dd7, 0x5ddf, 0x5ddf, 0x7de7, 0x7def, 0x9def, 0x9ef7, 0x9ef7, 0x9ef7, 0x9ef7, 0x7def, 0x7def, 0x7def, 0x7def, 0x7de7, 0x7de7, 0x5ddf, 0x7de7, 0x7de7, 0x5de7, 0x5ddf, 0x3cd7, 0xbbc6, 0x9ac6, 0x39b6, 0x7595, 0xcf6b, 0xcb4a, 0xa631, 0xc651, 0x6772, 0x0983, 0xcc9b, 0x2da4, 0x4eac, 0x2db4, 0x4dbc, 0x6dc4, 0x8dcc, 0x8dc4, 0x4dbc, 0x4dbc, 0x0dbc, 0xccbb, 0x0dcc, 0xf1dc, 0x73e5, 0x52e5, 0x71e5, 0xb2e5, 0x30d5, 0xcfd4, 0x8dd4, 0xaed4, 0xeedc, 0xced4, 0xcaab, 0x466a, 0x6441, 0x0329, 0xe320, 0xe420, 0x0429, 0x4531, 0x284a, 0x508c, 0x58c6, 0x79c6, 0x7ace, 0x5de7, 0x7de7, 0x9def, 0x9def, 0x9eef, 0x7def, 0x1cdf, 0xfbde, 0xfbde, 0xfbde, 0xfbde, 0xf7ed, 0xd5ed, 0x52ee, 0xf4ed, 0x96f5, 0xd4ed, 0x32ee, 0x12ee, 0xd4ed, 0x95ed, 0xd3ed, 0x11ee, 0xb4ed, 0x95ed, 0xd3ed, 0x94ed, 0x95ed, 0xd5ed, 0x96f5,
  0x1d8f, 0x5dc7, 0x5dd7, 0x5dd7, 0x7de7, 0x7def, 0x9def, 0x9eef, 0x9ef7, 0x9ef7, 0x9ef7, 0x7def, 0x7def, 0x7def, 0x7def, 0x7de7, 0x5de7, 0x5ddf, 0x5ddf, 0x7de7, 0x5de7, 0x5de7, 0x5ddf, 0x1ccf, 0x7abe, 0x96a5, 0xaf73, 0x4c63, 0xe741, 0x8639, 0x475a, 0x6b93, 0xcc9b, 0xec9b, 0x2dac, 0x2dac, 0x0cac, 0x0cb4, 0x2cc4, 0x0bbc, 0x499b, 0x8782, 0xe99a, 0xacbb, 0x4fd4, 0x13dd, 0x54dd, 0x54e5, 0xf2dc, 0x4fd4, 0x6ed4, 0xebb3, 0xcbb3, 0x6ccc, 0xced4, 0xeedc, 0xced4, 0xcbb3, 0x4672, 0x6441, 0x0329, 0xe320, 0xe428, 0x0429, 0x4531, 0xa641, 0xeb62, 0x139d, 0x38c6, 0xfbde, 0x5de7, 0x7de7, 0x9eef, 0x9def, 0x9eef, 0x9eef, 0x5de7, 0xfbde, 0xfbde, 0xfbde, 0xfbde, 0xf8ed, 0xf4ed, 0x32ee, 0xd5ed, 0x96f5, 0xb5f5, 0x13ee, 0x33ee, 0xf4ed, 0xb5ed, 0xf2ed, 0x11ee, 0xb4ed, 0xb5f5, 0x13ee, 0x95ed, 0x95ed, 0xd5ed, 0xb6ed,
  0xfd86, 0x3db7, 0x5dcf, 0x5dd7, 0x7ddf, 0x7de7, 0x9def, 0x9def, 0x7def, 0x7def, 0x7def, 0x7def, 0x7def, 0x7def, 0x7def, 0x7de7, 0x7de7, 0x5ddf, 0x5ddf, 0x7de7, 0x7de7, 0x5de7, 0x5ddf, 0x5ddf, 0x3dd7, 0xfbce, 0xd7ad, 0x2c6b, 0x8a52, 0xc739, 0x074a, 0xac93, 0xab9b, 0x298b, 0xcc9b, 0x2dac, 0xecab, 0xebab, 0xebbb, 0x0bc4, 0x6dc4, 0x8ec4, 0x6ec4, 0x8fd4, 0xb0dc, 0x12e5, 0x93e5, 0xb4e5, 0x93ed, 0x72ed, 0x31e5, 0xaec4, 0x4dbc, 0x6dcc, 0xcedc, 0xefdc, 0xced4, 0xaaab, 0x667a, 0x6441, 0xe320, 0xe320, 0x0429, 0x6531, 0x2842, 0xab52, 0x0c63, 0xd394, 0xbace, 0x5ce7, 0x7de7, 0x7de7, 0x9eef, 0x9eef, 0x9eef, 0x9eef, 0x9eef, 0x5ce7, 0x1cdf, 0x1bdf, 0xfbde, 0xf8ed, 0x13ee, 0xf3ed, 0xb5ed, 0x96f5, 0xd5ed, 0xf4ed, 0xf3ed, 0xd4ed, 0xd3ed, 0x10ee, 0xf2ed, 0xb4ed, 0xb4ed, 0xf2ed, 0x95f5, 0x75ed, 0xf4ed, 0xf3ed,
  0xbd6e, 0x3da7, 0x5dcf, 0x5dcf, 0x5dd7, 0x7de7, 0x7def, 0x7def, 0x7def, 0x7def, 0x7def, 0x7def, 0x7def, 0x7def, 0x7def, 0x7def, 0x7de7, 0x5ddf, 0x5ddf, 0x5ddf, 0x7de7, 0x5de7, 0x5ddf, 0x5ddf, 0x5dd7, 0x3ddf, 0x7abe, 0xd384, 0x4d5b, 0x8a42, 0x8629, 0x8639, 0xa541, 0x4431, 0xc972, 0x0dac, 0x0cac, 0xebab, 0xebb3, 0x0bbc, 0x8dcc, 0xefd4, 0xaecc, 0x6dcc, 0x6dcc, 0x8ecc, 0xafd4, 0xf0d4, 0x30dd, 0x51e5, 0x91e5, 0xd2e5, 0x50dd, 0xced4, 0xced4, 0xefdc, 0xadcc, 0xaaab, 0xe88a, 0xc551, 0xe320, 0xc318, 0x2529, 0x083a, 0x0c53, 0xaf63, 0x9284, 0x59be, 0x3ce7, 0x7de7, 0x7de7, 0x7de7, 0x9eef, 0x9eef, 0x9def, 0x9eef, 0x9eef, 0x9eef, 0x5de7, 0x3ce7, 0xfbde, 0xf7ed, 0x32ee, 0xf3ed, 0x95ed, 0xb5ed, 0x13ee, 0x13ee, 0xd4ed, 0xf2ed, 0x31ee, 0x11ee, 0xd3ed, 0xb4ed, 0xf2ed, 0x12ee, 0x96f5, 0x95f5, 0x32ee, 0x50ee,
  0x9c56, 0x1d97, 0x5dc7, 0x5dcf, 0x5dd7, 0x7ddf, 0x7de7, 0x7def, 0x7def, 0x7def, 0x7def, 0x7def, 0x7def, 0x7def, 0x7def, 0x7def, 0x7de7, 0x5ddf, 0x5ddf, 0x5ddf, 0x5ddf, 0x5ddf, 0x5ddf, 0x5ddf, 0x5ddf, 0x3cdf, 0xbbc6, 0x7aae, 0xf484, 0xf05b, 0xc731, 0xe418, 0xa210, 0xa210, 0xc549, 0x6b93, 0x0cac, 0xebab, 0xebb3, 0x2cbc, 0x8dcc, 0xaecc, 0xcfd4, 0xefd4, 0x30dd, 0x51dd, 0x52dd, 0x72dd, 0x91e5, 0x91e5, 0xb2e5, 0xb2e5, 0x50dd, 0xeedc, 0xeedc, 0xeedc, 0xcbab, 0x065a, 0x0652, 0x6439, 0xe318, 0xe320, 0x6631, 0x6a4a, 0x4e5b, 0x5274, 0xd89d, 0xfbce, 0x5de7, 0x7def, 0x7de7, 0x7de7, 0x9eef, 0x9eef, 0x7def, 0x9eef, 0x9eef, 0x9eef, 0x9eef, 0x7def, 0x1ce7, 0xf7ed, 0x12ee, 0xf4ed, 0xb6ed, 0xd4ed, 0x12ee, 0xf3ed, 0x94ed, 0xd2ed, 0x11ee, 0xb3ed, 0xb3ed, 0xf2ed, 0x31ee, 0xf3ed, 0x75f5, 0x95f5, 0x32ee, 0xb3ed,
  0x5c4e, 0xfd86, 0x3dbf, 0x5dc7, 0x5dc7, 0x5dd7, 0x7de7, 0x7def, 0x7def, 0x7def, 0x7def, 0x7def, 0x7def, 0x7def, 0x7def, 0x7def, 0x7de7, 0x5ddf, 0x5ddf, 0x5dd7, 0x5ddf, 0x5ddf, 0x5ddf, 0x5ddf, 0x5ddf, 0x5ddf, 0x3dd7, 0xfcc6, 0x358d, 0x2d5b, 0xc739, 0x0421, 0xc318, 0xa210, 0xe320, 0xa86a, 0xcca3, 0xcbab, 0xebab, 0x2cbc, 0xaecc, 0xefd4, 0xefd4, 0x30dd, 0xd2e5, 0x34e6, 0x76ee, 0x75ee, 0x34ee, 0xf2ed, 0xd2ed, 0xb1e5, 0x70e5, 0x0fdd, 0xeedc, 0x6dc4, 0x676a, 0xe320, 0xc318, 0xc318, 0xe320, 0x4529, 0x083a, 0xaf63, 0x1575, 0xb885, 0xbbae, 0x3cd7, 0x5de7, 0x7def, 0x7def, 0x7def, 0x9eef, 0x9eef, 0x7de7, 0x7de7, 0x9eef, 0x9def, 0x9def, 0x9eef, 0x3cef, 0xf7ed, 0x12ee, 0xd4ed, 0x95ed, 0xd4ed, 0x12ee, 0xd3ed, 0xb4ed, 0xf2ed, 0xb3ed, 0x74ed, 0xb2ed, 0x10ee, 0x91ed, 0xb2ed, 0xf2ec, 0x72ed, 0x70ee, 0xb0ec,
  0x3c46, 0xbd6e, 0x3daf, 0x5dbf, 0x5dbf, 0x5dcf, 0x5ddf, 0x7de7, 0x7def, 0x7def, 0x7def, 0x7def, 0x7def, 0x7def, 0x7def, 0x7def, 0x7de7, 0x5de7, 0x5ddf, 0x3dd7, 0x5ddf, 0x5ddf, 0x5ddf, 0x5ddf, 0x5ddf, 0x5ddf, 0x3dd7, 0xfbc6, 0xf484, 0xcb52, 0x8631, 0x0421, 0xe318, 0xc318, 0xc318, 0x0652, 0x6b93, 0xcca3, 0xcba3, 0x0cb4, 0x6dc4, 0xcecc, 0x0fd5, 0x0fd5, 0x51dd, 0xd2e5, 0x34e6, 0x34e6, 0x13e6, 0xf2ed, 0xf2ed, 0xb1e5, 0x50e5, 0xeedc, 0x6dcc, 0x088b, 0x4431, 0xa218, 0xc318, 0xc318, 0x2421, 0xe739, 0x0d53, 0xb37c, 0xb87d, 0x1a76, 0xdca6, 0x3dd7, 0x7de7, 0x7def, 0x7def, 0x7def, 0x9eef, 0x9eef, 0x7de7, 0x7de7, 0x7de7, 0x9ee7, 0x9def, 0x9def, 0x5def, 0xf6ed, 0xd2ed, 0x72ed, 0x73ed, 0x72ed, 0x91ed, 0x92ed, 0xb1ed, 0xf0ed, 0x10ed, 0xd1ec, 0x70ed, 0x2fe5, 0x6fec, 0x2fe5, 0x2ee4, 0xaeed, 0x4fee, 0xaddb,
  0x1c3e, 0x9c5e, 0x1d97, 0x3db7, 0x3daf, 0x3db7, 0x5dcf, 0x5ddf, 0x7de7, 0x7def, 0x7def, 0x7def, 0x7def, 0x7def, 0x7def, 0x7def, 0x7de7, 0x5de7, 0x5ddf, 0x5dd7, 0x5dd7, 0x5ddf, 0x5ddf, 0x5ddf, 0x5ddf, 0x5ddf, 0x5ddf, 0x39b6, 0xf48c, 0x4d5b, 0x8631, 0x0421, 0xe320, 0xc318, 0xe320, 0x0652, 0x2a8b, 0xcc9b, 0xeca3, 0xcca3, 0x0cac, 0x4dbc, 0x8dbc, 0x6dbc, 0x8ec4, 0xefcc, 0x30d5, 0x70dd, 0x70dd, 0xb1e5, 0xb1e5, 0x70dd, 0xeed4, 0x6dc4, 0x2993, 0x8441, 0xc318, 0xc318, 0xc318, 0xe420, 0x8631, 0xcb4a, 0x937c, 0x199e, 0x5b8e, 0x5b76, 0xdc9e, 0x5dd7, 0x7de7, 0x7def, 0x7def, 0x7def, 0x9eef, 0x9eef, 0x9def, 0x7ddf, 0x5dd7, 0x7de7, 0x9de7, 0x7def, 0x7def, 0x54e5, 0xefe4, 0x6fec, 0x0fed, 0xafec, 0xefe4, 0x8fed, 0xafe5, 0xaee5, 0xaddc, 0x6ddc, 0x4ee5, 0xecd3, 0xacd3, 0x2edd, 0x2ee5, 0x2ee6, 0xeee5, 0xcaca,
  0xdc2d, 0x7c4e, 0xfd86, 0x3da7, 0x3da7, 0x3da7, 0x3dbf, 0x5dd7, 0x7de7, 0x7def, 0x7de7, 0x7de7, 0x7def, 0x7def, 0x7def, 0x7def, 0x7de7, 0x5de7, 0x5ddf, 0x5ddf, 0x5dd7, 0x5ddf, 0x5ddf, 0x5ddf, 0x5ddf, 0x5ddf, 0x3dd7, 0xf8b5, 0x317c, 0xeb52, 0x8631, 0x2429, 0x0421, 0x0419, 0x2421, 0x275a, 0x298b, 0x8b93, 0xcc9b, 0xed9b, 0xec9b, 0xeca3, 0xeca3, 0xcba3, 0xcba3, 0xebab, 0x2cb4, 0x6dbc, 0xaec4, 0xefd4, 0xefd4, 0x8dc4, 0x0cbc, 0x8aa3, 0xc549, 0xe318, 0xc318, 0xe320, 0x0421, 0xa729, 0x293a, 0x6e5b, 0x9795, 0xdcb6, 0xbc96, 0x9c7e, 0xfca6, 0x5dd7, 0x7de7, 0x7def, 0x7de7, 0x7def, 0x9eef, 0x9eef, 0x9eef, 0x3dcf, 0x1cc7, 0x7ddf, 0x7de7, 0x7def, 0x7def, 0x13d5, 0xcdcb, 0xccd3, 0x8dd4, 0xecd3, 0xcccb, 0x0dd5, 0x0dd5, 0xacd4, 0x4ddd, 0x4ddd, 0x2ddd, 0x2ac3, 0xabc3, 0x8ddd, 0x8edd, 0x6dd5, 0x4dd5, 0x89ba,
  0xbc2d, 0x3c46, 0xdd76, 0x1d9f, 0x3d9f, 0x3d9f, 0x3daf, 0x3dcf, 0x5ddf, 0x7de7, 0x7de7, 0x5ddf, 0x7de7, 0x7def, 0x7def, 0x7def, 0x7de7, 0x5de7, 0x5de7, 0x5ddf, 0x5ddf, 0x5ddf, 0x5ddf, 0x5de7, 0x5ddf, 0x5ddf, 0x3dd7, 0xdbc6, 0xf48c, 0xaf63, 0x4942, 0x6629, 0x2421, 0x2521, 0x6531, 0x6762, 0x298b, 0x6a93, 0xac9b, 0xcc9b, 0xcc9b, 0xcc9b, 0xab9b, 0x6b9b, 0x6a93, 0x6a93, 0x6a9b, 0x8a9b, 0xcba3, 0x0cac, 0x0cac, 0xcbab, 0x8aa3, 0x2893, 0x4439, 0xc318, 0xc318, 0xe420, 0x6629, 0x0932, 0x0832, 0xec52, 0x158d, 0x9bae, 0xbc9e, 0x9c86, 0xfca6, 0x5dcf, 0x7de7, 0x7def, 0x7de7, 0x7def, 0x9eef, 0x9eef, 0x7def, 0x1cb7, 0xfcae, 0x5ddf, 0x7ddf, 0x7de7, 0x7def, 0x13c5, 0x4bbb, 0xabc3, 0x2bcc, 0x4ac3, 0xc9ba, 0x2bcc, 0x4bcc, 0x6ac3, 0xccd4, 0x8dd5, 0x8bcc, 0xcac3, 0x0cd5, 0x4cd5, 0x8ac3, 0x8bcc, 0xecd4, 0x89ba,
  0xdc35, 0x1c3e, 0xbd6e, 0x1d97, 0x3d9f, 0x1d9f, 0x3d9f, 0x3db7, 0x5dcf, 0x5ddf, 0x5ddf, 0x5dd7, 0x5dd7, 0x7de7, 0x7def, 0x7de7, 0x7de7, 0x5de7, 0x5de7, 0x5de7, 0x5ddf, 0x5ddf, 0x5ddf, 0x5ddf, 0x5ddf, 0x3dd7, 0x1ccf, 0xdbc6, 0x358d, 0xb374, 0xcb4a, 0xc731, 0x6629, 0xe829, 0x2842, 0xc972, 0x4a8b, 0x4a8b, 0x6b93, 0x8b9b, 0xab9b, 0x8b9b, 0x8b9b, 0x6a9b, 0x6a9b, 0x6a9b, 0x6a9b, 0x6a9b, 0x8b9b, 0x8b9b, 0xaba3, 0xaba3, 0x89a3, 0x2893, 0x4431, 0xc318, 0xe318, 0xe420, 0x4529, 0xa729, 0xa731, 0x0c53, 0x1585, 0x5aa6, 0xbc96, 0x9c86, 0xdca6, 0x3cc7, 0x5ddf, 0x5de7, 0x7de7, 0x7de7, 0x9def, 0x9eef, 0x7de7, 0xdc9e, 0xdc9e, 0x5dd7, 0x7ddf, 0x7de7, 0x7de7, 0x33c5, 0x2bb3, 0x2bc4, 0xebc3, 0xe9b2, 0x89ba, 0x2bcc, 0x4bcc, 0x09bb, 0xaabb, 0xaabb, 0x0bc4, 0x2cd5, 0x6dd5, 0xabcc, 0x29bb, 0x2cd5, 0xaccc, 0x89ba,
  0xdc35, 0xdc35, 0x7c66, 0xfd8e, 0x1d97, 0x1d97, 0x1d97, 0x1da7, 0x3dbf, 0x5dcf, 0x5dd7, 0x5dc7, 0x3dcf, 0x5ddf, 0x7de7, 0x7de7, 0x7de7, 0x5de7, 0x5ddf, 0x7de7, 0x7ddf, 0x5dd7, 0x5dd7, 0x5ddf, 0x5ddf, 0x1cd7, 0x39b6, 0xf48c, 0x6e6b, 0x0c5b, 0xab4a, 0x2d43, 0x6b32, 0x2d43, 0x8e5b, 0x6b83, 0x4a8b, 0x4a8b, 0x4a8b, 0x6a93, 0x6a93, 0x6a93, 0x4a93, 0x4a93, 0x6a9b, 0x6a9b, 0x8a9b, 0x8a9b, 0x8b9b, 0xaba3, 0xcbab, 0xaaab, 0xcab3, 0x499b, 0x2431, 0xc318, 0xe318, 0x0421, 0x2529, 0x4529, 0x8631, 0x0c53, 0x1585, 0x5a9e, 0x9c96, 0x9c86, 0xdc9e, 0x1cc7, 0x5ddf, 0x5de7, 0x5de7, 0x7de7, 0x9def, 0x9def, 0x7de7, 0xbc8e, 0xdc96, 0x5dd7, 0x7ddf, 0x7ddf, 0x7de7, 0x54c5, 0x4bb3, 0x6ccc, 0xebc3, 0xe9b2, 0xc9b2, 0x4bcc, 0x8bcc, 0x8abb, 0x69bb, 0x09b3, 0xcac3, 0x2dd5, 0x2bc4, 0xabcc, 0x8bc4, 0x4cd5, 0x6bc4, 0x89b2,
  0xdb3d, 0xdc35, 0x3c4e, 0xdd7e, 0x1d97, 0x1d97, 0x1d97, 0x1d97, 0x1da7, 0x3dbf, 0x5dcf, 0x5dc7, 0x3dbf, 0x5dcf, 0x5ddf, 0x7de7, 0x5de7, 0x5ddf, 0x5ddf, 0x5ddf, 0x7ddf, 0x5dd7, 0x5dcf, 0x3dd7, 0x3cd7, 0xdbc6, 0x19ae, 0xd89d, 0x937c, 0x316c, 0xaf5b, 0x7354, 0x6f43, 0xd464, 0xb27c, 0xac8b, 0x6a93, 0x4a93, 0x4a93, 0x4a8b, 0x4a8b, 0x4a93, 0x4a93, 0x4a93, 0x4993, 0x4993, 0x6a9b, 0x6a9b, 0xaba3, 0xecab, 0xebb3, 0xcbb3, 0x0bbc, 0x699b, 0x4431, 0xc318, 0xe318, 0xe320, 0x0421, 0x4529, 0x8631, 0x4942, 0x1174, 0x1996, 0x9c96, 0x9c8e, 0xdc9e, 0x1cbf, 0x3dd7, 0x5ddf, 0x5ddf, 0x7de7, 0x7def, 0x9def, 0x7de7, 0x9c86, 0x9c7e, 0x5dcf, 0x7ddf, 0x5ddf, 0x7de7, 0x95c5, 0x6cab, 0xcccc, 0x0bc4, 0x6abb, 0x4ab3, 0xaabb, 0xabcc, 0x6bcc, 0xaabb, 0x69b3, 0xcabb, 0x8abb, 0x6abb, 0xaddd, 0xcddd, 0x0ac4, 0x6bc4, 0xcccc,
  0xdb45, 0xdb35, 0x1c46, 0x9c76, 0xfd96, 0x1d97, 0xfd96, 0xfd8e, 0x1d97, 0x1da7, 0x3db7, 0x5dbf, 0x3dbf, 0x5dc7, 0x5ddf, 0x5ddf, 0x5ddf, 0x5ddf, 0x5ddf, 0x5ddf, 0x5ddf, 0x5dd7, 0x3dbf, 0xfcc6, 0xfcce, 0xbbbe, 0x18ae, 0xb795, 0xd47c, 0x4e5b, 0xec4a, 0x0d43, 0x5354, 0x9364, 0x6d73, 0x2a8b, 0x6a9b, 0x6a93, 0x4a93, 0x4a93, 0x6a93, 0x6a93, 0x4a93, 0x4a93, 0x6a9b, 0x6a9b, 0x8aa3, 0xaba3, 0xcbab, 0x0cbc, 0x0cb4, 0x2cbc, 0x4cc4, 0x699b, 0x8539, 0x0421, 0x0421, 0x0421, 0x2429, 0x8629, 0x0932, 0x8b42, 0x8f63, 0x778d, 0x9c96, 0x9c8e, 0xdca6, 0x1cbf, 0x3dcf, 0x5dd7, 0x5dd7, 0x5ddf, 0x7de7, 0x7def, 0x7de7, 0x7c7e, 0x7c76, 0x3dc7, 0x5ddf, 0x5ddf, 0x5de7, 0xb5c5, 0xacab, 0x0dcd, 0x2bbc, 0xebb3, 0x8ab3, 0xe9aa, 0x6bc4, 0xaddd, 0xabcc, 0x0ac4, 0x8bc4, 0x6bc4, 0xabcc, 0x0bcd, 0xeccc, 0x89b2, 0x29b3, 0xeedd,
  0xbb45, 0xbb3d, 0xfb3d, 0x7c66, 0xdd8e, 0xfd96, 0xfd8e, 0xdd8e, 0xfd96, 0x1d9f, 0x3daf, 0x3db7, 0x3db7, 0x3db7, 0x5dcf, 0x5ddf, 0x5ddf, 0x5ddf, 0x5dd7, 0x5ddf, 0x3ddf, 0x3dd7, 0x1cb7, 0xdcae, 0xbbb6, 0x39b6, 0x5695, 0x927c, 0x7274, 0xaf63, 0xcf63, 0x367d, 0xb78d, 0x6e63, 0x8862, 0x298b, 0x6a9b, 0x6a9b, 0x4a93, 0x6a93, 0x6a93, 0x6a93, 0x4a93, 0x6a9b, 0x8aa3, 0xaaab, 0xebb3, 0x2cbc, 0x2cbc, 0x4cc4, 0x4cc4, 0x6dc4, 0x6dcc, 0x699b, 0x4431, 0x0421, 0x0421, 0x2421, 0xc731, 0xb04b, 0x5765, 0xd46c, 0x116c, 0x3685, 0x9b8e, 0x9c8e, 0xdca6, 0x1cb7, 0x1cc7, 0x3dd7, 0x3dcf, 0x5ddf, 0x5ddf, 0x7def, 0x5ddf, 0x9c7e, 0x7c76, 0x1db7, 0x5dd7, 0x5dd7, 0x5ddf, 0xd6c5, 0xcdab, 0xeccc, 0x4bbc, 0x0abc, 0x6ab3, 0x89a2, 0x09b3, 0x8bcc, 0x6cd5, 0x2cd5, 0x2cd5, 0xeccc, 0xabcc, 0x2ccd, 0x6bc4, 0x89b2, 0x29b3, 0x8ddd,
  0x9b3d, 0x9b3d, 0xbb35, 0x3c56, 0xbc7e, 0xfd96, 0xfd8e, 0xdd8e, 0xdc8e, 0xfd96, 0x1d9f, 0x3daf, 0x3daf, 0x3daf, 0x3dbf, 0x3dcf, 0x5ddf, 0x5dd7, 0x3dd7, 0x3dd7, 0x3dd7, 0x3dd7, 0x1cb7, 0xbb9e, 0x7aa6, 0x979d, 0x9384, 0xb384, 0x1485, 0xb795, 0x7aae, 0xbbb6, 0xb6ad, 0xaa5a, 0x4762, 0x298b, 0x6a9b, 0x4a9b, 0x6a9b, 0x6a9b, 0x6a9b, 0x6a9b, 0x8a9b, 0x8aa3, 0xcbab, 0xebb3, 0x0cbc, 0x4cc4, 0x4dc4, 0x4cc4, 0x6dcc, 0xadcc, 0x8dcc, 0x8aa3, 0x4431, 0x2429, 0xa731, 0x6a3a, 0x2e43, 0xd55c, 0xd96d, 0x7775, 0xd47c, 0x9785, 0x7b86, 0x7b86, 0xbca6, 0xfcae, 0x1cbf, 0x3dcf, 0x3dcf, 0x3dd7, 0x5dd7, 0x7de7, 0x5dd7, 0x7c76, 0x5c6e, 0xfdae, 0x5dd7, 0x5dd7, 0x5ddf, 0x17c6, 0xedab, 0xeccc, 0xacc4, 0x0bbc, 0x4ab3, 0x89aa, 0x89b2, 0x29bb, 0xcbcc, 0x2cd5, 0x8ac4, 0x8ac4, 0x4ac4, 0xecd4, 0x4ac4, 0xa9b2, 0xeabb, 0x8ddd,
  0xbb45, 0x9a3d, 0x9b3d, 0xfb4d, 0x9c76, 0xdd8e, 0xdd8e, 0xdd8e, 0xdd8e, 0xdd8e, 0xfd8e, 0x1d9f, 0x3da7, 0x3da7, 0x3daf, 0x3dc7, 0x3dd7, 0x3dd7, 0x3dcf, 0x3dcf, 0x3dd7, 0x3dd7, 0x3dc7, 0xfc9e, 0xbb9e, 0xf8a5, 0xb79d, 0x7ab6, 0xdbae, 0x1cbf, 0x1ccf, 0x1cdf, 0x38c6, 0xeb6a, 0x2762, 0x098b, 0x4a93, 0x4a9b, 0x6a9b, 0x6a9b, 0x6a9b, 0x8b9b, 0xaba3, 0xebab, 0x2cbc, 0x4cc4, 0x6dcc, 0x8ecc, 0x8ecc, 0x8ecc, 0xaecc, 0xaed4, 0x8dcc, 0xaaa3, 0x6539, 0xe741, 0xb063, 0x535c, 0xb554, 0x585d, 0x986d, 0x7775, 0x978d, 0x3a96, 0x7b7e, 0x7b7e, 0xdc9e, 0xfcae, 0x1cb7, 0x3cbf, 0x3dc7, 0x3dc7, 0x5dcf, 0x7de7, 0x5dcf, 0x9c76, 0x3c6e, 0xfc9e, 0x3dcf, 0x5dcf, 0x5ddf, 0x59ce, 0xedab, 0xeccc, 0x2ccd, 0x0abc, 0x09b3, 0x88aa, 0xa9b2, 0x49bb, 0x2ac4, 0xeabb, 0x2ac4, 0x6cd5, 0x0cd5, 0xcac3, 0x4bc4, 0x49bb, 0xebcc, 0x2ccd,
  0xdb45, 0x7a3d, 0x7a45, 0x9b45, 0x5c6e, 0xbc86, 0xdd8e, 0xdd8e, 0xbd86, 0xbd86, 0xdd7e, 0xfd8e, 0x1d9f, 0x1d9f, 0x1d9f, 0x3daf, 0x3dc7, 0x3dcf, 0x3dc7, 0x3dc7, 0x3dcf, 0x3dcf, 0x3dcf, 0x3daf, 0x1d9f, 0xfcae, 0xdbbe, 0x1ccf, 0x3ccf, 0x5ddf, 0x7def, 0x7def, 0xbbde, 0x6d7b, 0x2762, 0xe882, 0x4993, 0x6a9b, 0x6a9b, 0x6a9b, 0x8a9b, 0x8b9b, 0xcba3, 0x0cb4, 0x4dbc, 0x8dcc, 0xaed4, 0xcfd4, 0xcfd4, 0xaecc, 0xaed4, 0xadcc, 0x6cc4, 0xaaa3, 0xc649, 0x8e7b, 0xd7ad, 0x987d, 0xf75c, 0x3765, 0x786d, 0x987d, 0x399e, 0xbb9e, 0x7c76, 0x5b76, 0xbc9e, 0xfcae, 0x1cb7, 0x1cb7, 0x3dbf, 0x3dbf, 0x3cbf, 0x7ddf, 0x5dcf, 0x9c7e, 0x5c6e, 0xdc96, 0x3dc7, 0x3dc7, 0x5dd7, 0x9ac6, 0xeeab, 0xeccc, 0x8dd5, 0xeabb, 0xc9aa, 0xc9b2, 0x09b3, 0x49bb, 0x2acc, 0xabcc, 0xcbcc, 0xabc4, 0xaccc, 0xe9b2, 0x2bc4, 0x0ccd, 0x2cd5, 0x4ac4,
  0x1b46, 0x7a3d, 0x7a45, 0x9a45, 0xfb5d, 0x9c7e, 0xbd8e, 0xdd8e, 0xbd86, 0x9c7e, 0xbc76, 0xdd7e, 0xfd86, 0xfd8e, 0xfd96, 0x1d9f, 0x3db7, 0x3dc7, 0x3dc7, 0x3dbf, 0x3dbf, 0x3dbf, 0x3dc7, 0x3dbf, 0x3daf, 0x5dbf, 0x7ddf, 0x9ee7, 0x9eef, 0x9ef7, 0x9ef7, 0x9ef7, 0x3ce7, 0xef93, 0x486a, 0xc882, 0x4993, 0x6a9b, 0x8a9b, 0x8a9b, 0x8b9b, 0xab9b, 0xcca3, 0x0cb4, 0x4dc4, 0x8ecc, 0xaed4, 0xcfd4, 0xaed4, 0xaecc, 0xaed4, 0x8dcc, 0x4cbc, 0xaba3, 0x2762, 0xd3a4, 0xdbde, 0x9bae, 0xb96d, 0xd96d, 0x1a7e, 0x5a8e, 0xbbae, 0xdc9e, 0x7c76, 0x5b6e, 0xbc96, 0xfcae, 0x1cb7, 0x1cb7, 0x1cb7, 0x1cb7, 0x1cb7, 0x5dd7, 0x5dcf, 0x9c7e, 0x5c6e, 0xbc8e, 0x3dbf, 0x3dbf, 0x3dc7, 0xbbc6, 0xeea3, 0xccc4, 0x8ddd, 0xeabb, 0x88aa, 0x49bb, 0x49bb, 0xc9ba, 0x2acc, 0x6cdd, 0xabcc, 0xeabb, 0xaccc, 0xe9b2, 0x4bcc, 0x6dd5, 0xaab3, 0xcabb,
  0x5c56, 0xbb3d, 0x7a45, 0x9a45, 0xdb4d, 0x5c6e, 0x9c86, 0xbd86, 0xbc86, 0x9c76, 0x9c76, 0x9c76, 0xbd7e, 0xdd86, 0xfd8e, 0xfd96, 0x1daf, 0x3dbf, 0x3dbf, 0x3dbf, 0x1db7, 0x3db7, 0x3dbf, 0x7edf, 0xbee7, 0xbeef, 0xdff7, 0xdfff, 0xdfff, 0xbef7, 0xbef7, 0xbef7, 0x9ef7, 0xb3ac, 0xc97a, 0xc882, 0x4a93, 0x8a9b, 0x8a9b, 0x8a9b, 0x8a9b, 0xaba3, 0xcba3, 0x0cb4, 0x2dbc, 0x6dc4, 0x6ecc, 0x8ecc, 0x8ecc, 0x8dcc, 0x8dcc, 0x4cc4, 0x4dbc, 0xcba3, 0x0b7b, 0xf7c5, 0x5def, 0x1cd7, 0x7b96, 0x9b86, 0xbc86, 0xdc96, 0xfcae, 0xdc9e, 0x7c6e, 0x5b6e, 0xbc96, 0xfcae, 0xfcb6, 0x1cb7, 0x1cb7, 0x1caf, 0x1cb7, 0x5ccf, 0x5dc7, 0x9c7e, 0x5c6e, 0xbc86, 0x1db7, 0x3dbf, 0x3dbf, 0xfcbe, 0xeea3, 0x8bc4, 0x6cd5, 0xcabb, 0xa8aa, 0x69bb, 0x69bb, 0x68ba, 0xaac3, 0x0bd5, 0x6bcc, 0xabcc, 0xcbcc, 0x29bb, 0x0cd5, 0x6ac4, 0x88aa, 0x09b3,
  0x7c5e, 0xdb45, 0x7a45, 0x9a45, 0xba4d, 0x1b5e, 0x7c7e, 0xbc86, 0x9c86, 0x7c76, 0x7c6e, 0x9c6e, 0xbc76, 0xbd7e, 0xdd86, 0xfd8e, 0xfd9e, 0x1caf, 0x1cbf, 0x3cbf, 0x5dc7, 0x7ed7, 0xbeef, 0xdff7, 0xffff, 0xffff, 0xffff, 0xffff, 0xffff, 0xdfff, 0xdfff, 0xdfff, 0xdff7, 0xd7c5, 0x6c93, 0xe88a, 0x6a9b, 0x8aa3, 0x8aa3, 0x8a9b, 0x8aa3, 0xaba3, 0xcbab, 0x0cb4, 0x2cbc, 0x4dc4, 0x4dc4, 0x4dc4, 0x6dc4, 0x6dc4, 0x4cc4, 0x4cbc, 0x4dbc, 0xecab, 0x919c, 0xdbde, 0x9ef7, 0x7def, 0x3dd7, 0x3dcf, 0x1caf, 0xfc9e, 0xfca6, 0xdc96, 0x7c6e, 0x3b66, 0x9c8e, 0xfca6, 0xfcae, 0x1cb7, 0x1cb7, 0x1caf, 0x1caf, 0x3cbf, 0x3dbf, 0x9c7e, 0x5c6e, 0xbc86, 0x1cb7, 0x3db7, 0x3dbf, 0xfcb6, 0x0f9c, 0x2bbc, 0x2cd5, 0xaabb, 0xe9aa, 0x89b3, 0x29bb, 0x68b2, 0xaac3, 0x0bd5, 0x8bcc, 0x4cd5, 0xebcc, 0x2ac4, 0xabcc, 0x2ac4, 0x68aa, 0xa8b2,
  0x7c5e, 0x1b4e, 0x9a45, 0x9a45, 0x9a45, 0xdb55, 0x3b6e, 0x9c86, 0x9c86, 0x5c76, 0x5c6e, 0x7c6e, 0x9c76, 0xbd7e, 0xdd86, 0xdd86, 0xfc96, 0x1db7, 0x7dd7, 0xbeef, 0xdff7, 0xffff, 0xffff, 0xffff, 0xffff, 0xffff, 0xffff, 0xffff, 0xffff, 0xffff, 0xffff, 0xffff, 0xffff, 0xdbde, 0x50ac, 0x6a9b, 0xaaa3, 0xcbab, 0xcbab, 0xaaa3, 0xaaa3, 0xcbab, 0xebab, 0x0cb4, 0x2cbc, 0x4dc4, 0x4cc4, 0x2cc4, 0x4cc4, 0x2cbc, 0x2cbc, 0x4cbc, 0x4dbc, 0x2eac, 0xf8bd, 0x7eef, 0xbef7, 0xbef7, 0xbef7, 0xbef7, 0x9eef, 0x5dd7, 0x1cbf, 0xdc96, 0x7c6e, 0x3b5e, 0x7b7e, 0xdc9e, 0xfcae, 0x1cb7, 0x1cb7, 0x1cb7, 0x1ca7, 0x1caf, 0x1cb7, 0xbc7e, 0x7c76, 0x9c86, 0xfcae, 0x1db7, 0x3dbf, 0xfcae, 0x0f9c, 0xcab3, 0x0ccd, 0xcabb, 0x49b3, 0x89bb, 0xc8b2, 0xa8b2, 0xeac3, 0x8cdd, 0x2cd5, 0xabcc, 0xabcc, 0x0bd5, 0x89bb, 0x6ac4, 0x68aa, 0x69bb,
  0x7d66, 0x3c56, 0xbb45, 0x9a45, 0x9a45, 0xba4d, 0x1b66, 0x7c7e, 0x9c86, 0x5c76, 0x3c66, 0x7c6e, 0x9c76, 0x9c76, 0xbc86, 0xfda6, 0x7ed7, 0xdff7, 0xffff, 0xffff, 0xffff, 0xffff, 0xffff, 0xffff, 0xffff, 0xffff, 0xffff, 0xffff, 0xffff, 0xffff, 0xffff, 0xffff, 0xffff, 0x9eef, 0x75c5, 0x2eac, 0x2cb4, 0x2cbc, 0x0cb4, 0xebb3, 0xebb3, 0x0cb4, 0xebb3, 0x0cbc, 0x2cc4, 0x4cc4, 0x4cc4, 0x4cc4, 0x6dcc, 0x4cc4, 0x4cc4, 0x6dc4, 0x4cbc, 0x13b5, 0xdbd6, 0xbff7, 0xdfff, 0xdfff, 0xffff, 0xdfff, 0xdfff, 0xdfff, 0xbeef, 0x1dbf, 0x7c6e, 0x3b56, 0x5b76, 0xdc96, 0xfca6, 0x1caf, 0x1cb7, 0x1daf, 0x1ca7, 0x1ca7, 0x1ca7, 0xbc7e, 0x7c76, 0x9c7e, 0xfca6, 0x1cb7, 0x1db7, 0xfca6, 0x309c, 0x6aab, 0xcbcc, 0xcabb, 0xaabb, 0xcabb, 0xa8b2, 0xe9ba, 0x4acc, 0x2bd5, 0x8bcc, 0x69bb, 0x69bb, 0xcac3, 0xc9b2, 0x6ac4, 0xc8aa, 0xebcc,
  0x9c66, 0x7c5e, 0xfb4d, 0x9a45, 0x9a45, 0x9a45, 0xdb55, 0x5c76, 0x7c7e, 0x5c76, 0x3b66, 0x5b66, 0x7c6e, 0xbc8e, 0x3ecf, 0xdff7, 0xffff, 0xffff, 0xffff, 0xffff, 0xffff, 0xffff, 0xffff, 0xffff, 0xffff, 0xffff, 0xffff, 0xffff, 0xffff, 0xffff, 0xffff, 0xffff, 0xffff, 0xdfff, 0xdbde, 0x53cd, 0xcfc4, 0xcfcc, 0x8ec4, 0x6dbc, 0x4dbc, 0x4dc4, 0x4cc4, 0x4cc4, 0x4dc4, 0x4dc4, 0x6dcc, 0xaed4, 0xced4, 0xced4, 0xefd4, 0xefcc, 0x4dbc, 0x38ce, 0x7def, 0xdfff, 0xffff, 0xffff, 0xffff, 0xffff, 0xffff, 0xffff, 0xffff, 0x9eef, 0x9bae, 0xb96d, 0x3b6e, 0xbc8e, 0xdc9e, 0xfcae, 0x1cb7, 0x1caf, 0x1da7, 0xfca6, 0xfc9e, 0xbc7e, 0x7c76, 0x9c76, 0xfca6, 0x1cb7, 0x1cb7, 0xfca6, 0x719c, 0x0aa3, 0x8bc4, 0x0abc, 0x2abc, 0x0ac4, 0xa8aa, 0x09bb, 0x4acc, 0x4acc, 0x6ac3, 0x29c3, 0x89bb, 0x8abb, 0xa8b2, 0xeac3, 0x6ac4, 0x8cdd,
  0x5c5e, 0x7d66, 0x3c56, 0xbb45, 0x9a45, 0x7a45, 0x9a45, 0x1b66, 0x7c7e, 0x5c76, 0x3b66, 0x5b6e, 0xddae, 0x9ee7, 0xffff, 0xffff, 0xffff, 0xffff, 0xffff, 0xffff, 0xffff, 0xffff, 0xffff, 0xffff, 0xffff, 0xffff, 0xffff, 0xffff, 0xffff, 0xffff, 0xffff, 0xffff, 0xffff, 0xffff, 0x7eef, 0x37de, 0x72dd, 0x30d5, 0x0fd5, 0xefcc, 0xcfcc, 0xefd4, 0xcfd4, 0xced4, 0xaed4, 0xced4, 0xefd4, 0x50dd, 0x71dd, 0xd2e5, 0x13e6, 0xf3e5, 0x94cd, 0x1cdf, 0xbff7, 0xffff, 0xffff, 0xffff, 0xffff, 0xffff, 0xffff, 0xffff, 0xbef7, 0x39ce, 0x929c, 0x518c, 0xf494, 0xd895, 0x9b9e, 0xfcae, 0x1cb7, 0x1caf, 0x1da7, 0xfc9e, 0xdc96, 0x9c76, 0x7c76, 0x7c76, 0xdc9e, 0x1cb7, 0x1cb7, 0xfcae, 0xb29c, 0xea9a, 0x4ac4, 0x8ac4, 0xabcc, 0x0ac4, 0x88aa, 0x29bb, 0x6acc, 0x2acc, 0x8ac3, 0x6abb, 0x4bc4, 0x0bbc, 0x88b2, 0x89bb, 0xacdd, 0x6acc,
  0x1c56, 0x5c5e, 0x3c56, 0xdb45, 0x9a3d, 0x7a3d, 0x5a3d, 0xbb4d, 0x5c6e, 0x5c76, 0x9c8e, 0x3dcf, 0xdff7, 0xffff, 0xffff, 0xffff, 0xffff, 0xffff, 0xffff, 0xffff, 0xffff, 0xffff, 0xffff, 0xffff, 0xffff, 0xffff, 0xffff, 0xffff, 0xffff, 0xffff, 0xffff, 0xffff, 0xffff, 0xffff, 0xbff7, 0xdae6, 0x15e6, 0xd2e5, 0x92e5, 0x71dd, 0x71dd, 0xb2dd, 0xf4dd, 0x35e6, 0xf4dd, 0xb3dd, 0x92e5, 0xf3e5, 0x55ee, 0x75ee, 0x76e6, 0x35e6, 0xbade, 0x7eef, 0xdfff, 0xffff, 0xffff, 0xffff, 0xffff, 0xffff, 0xdfff, 0x9ef7, 0xd7c5, 0xf08b, 0x8e7b, 0xcf83, 0x108c, 0x5194, 0xd39c, 0xb7a5, 0xbbae, 0x1caf, 0x1ca7, 0xdc96, 0xbc8e, 0x7c76, 0x7c76, 0x5c6e, 0xbc8e, 0xfcae, 0x1cb7, 0x1caf, 0xf49c, 0x0b9b, 0xa9b3, 0xcbcc, 0x2bd5, 0xeac3, 0x68b2, 0x49bb, 0x8bcc, 0x0acc, 0x6ac3, 0xc9bb, 0xcbd4, 0x4bcc, 0xe9ba, 0xabd4, 0xace5, 0xece3,
  0x9b45, 0x3c5e, 0x5c56, 0xdb3d, 0x7a3d, 0x5a35, 0x1a3d, 0x3a3d, 0xdb55, 0x9c9e, 0x7edf, 0xffff, 0xffff, 0xffff, 0xffff, 0xffff, 0xffff, 0xffff, 0xffff, 0xffff, 0xffff, 0xffff, 0xffff, 0xffff, 0xffff, 0xdfff, 0xffff, 0xffff, 0xffff, 0xffff, 0xffff, 0xffff, 0xffff, 0xffff, 0xdff7, 0x5cef, 0xb8e6, 0x55ee, 0x34e6, 0x34ee, 0x34ee, 0x13ee, 0x13ee, 0x55e6, 0x76e6, 0x35e6, 0x14e6, 0x55ee, 0x96ee, 0x97ee, 0xb7ee, 0x98e6, 0x3de7, 0xbff7, 0xffff, 0xffff, 0xffff, 0xffff, 0xffff, 0xdfff, 0x3ce7, 0x76b5, 0xaf83, 0x2d6b, 0x4d73, 0x6e73, 0x6e7b, 0xcf83, 0x308c, 0x929c, 0xf8b5, 0x3dbf, 0x1ca7, 0xfc96, 0xbc86, 0x5c6e, 0x5c76, 0x3c6e, 0x9c86, 0xfca6, 0x1cb7, 0x1caf, 0x96a5, 0x4ca3, 0xe9aa, 0x8bc4, 0x6cd5, 0xeac3, 0x68ba, 0x49c3, 0x8bd4, 0xeacb, 0xcacb, 0x0cdd, 0xacdc, 0xcde4, 0x2de4, 0x8de5, 0x6de5, 0x4de4,
  0x1a3d, 0xdb4d, 0x3c56, 0xdb3d, 0x7b35, 0x3a35, 0xf934, 0xf93c, 0x1b7e, 0x7ed7, 0xffff, 0xffff, 0xffff, 0xffff, 0xffff, 0xffff, 0xffff, 0xffff, 0xffff, 0xffff, 0xffff, 0xffff, 0xffff, 0xffff, 0xffff, 0xbef7, 0xffff, 0xffff, 0xffff, 0xffff, 0xffff, 0xffff, 0xffff, 0xffff, 0xdfff, 0x7def, 0xd9ee, 0x76ee, 0x55ee, 0x55ee, 0x35ee, 0x14ee, 0x13ee, 0x75ee, 0xb7ee, 0x96ee, 0x55ee, 0x34ee, 0x75ee, 0x96ee, 0xb8e6, 0xfcde, 0x7eef, 0xdff7, 0xffff, 0xffff, 0xffff, 0xffff, 0xdfff, 0x3def, 0x55ad, 0x6e73, 0xec6a, 0x2c6b, 0x2c6b, 0x2d6b, 0x6e7b, 0xcf83, 0xf08b, 0x929c, 0xbade, 0xbeef, 0x3dbf, 0xfc96, 0x9c7e, 0x5c6e, 0x3b6e, 0x1b66, 0x7c76, 0xfc9e, 0x1caf, 0x1caf, 0x7aa6, 0xefa3, 0x89a2, 0xeac3, 0x4bd5, 0x2acc, 0xa9c2, 0x8ad3, 0xabdc, 0x0be4, 0xece3, 0x4ee5, 0x8ee4, 0x2ee5, 0x0de5, 0x6fe5, 0x6fe5, 0x30e5,
  0xb93c, 0x7a3d, 0x1c56, 0xfc45, 0x7b3d, 0x3a35, 0xf93c, 0x7a65, 0xfdc6, 0xdfff, 0xffff, 0xffff, 0xffff, 0xffff, 0xffff, 0xffff, 0xffff, 0xffff, 0xffff, 0xffff, 0xffff, 0xffff, 0xffff, 0xffff, 0xffff, 0xbef7, 0xdfff, 0xffff, 0xffff, 0xffff, 0xdfff, 0x9ef7, 0x7df7, 0x5def, 0x7def, 0x7def, 0xdaee, 0x76ee, 0x55ee, 0x55ee, 0x34ee, 0x14ee, 0x55ee, 0xb7ee, 0xf8ee, 0xd8ee, 0x96ee, 0x55ee, 0x34ee, 0x56e6, 0xdade, 0x3ddf, 0x9fef, 0xffff, 0xffff, 0xffff, 0xffff, 0xdfff, 0xbef7, 0xd7c5, 0x8e7b, 0xcb62, 0xec6a, 0xec6a, 0x0c6b, 0x4d73, 0xae7b, 0xaf83, 0xf083, 0x14ad, 0x9ef7, 0xffff, 0xbff7, 0x3dbf, 0x9c86, 0x5b6e, 0x3b6e, 0x1b66, 0x5c6e, 0xdc96, 0x1caf, 0xfca6, 0xdca6, 0xf49c, 0x0bb3, 0x29cb, 0xcbdc, 0xacdc, 0x6cdb, 0x0de4, 0xede4, 0xaee4, 0xafe4, 0x6fe5, 0x12e5, 0x6fe5, 0x8ee5, 0x32ed, 0x50e5, 0x50e5,
  0x993c, 0x1a3d, 0xbb45, 0xfc4d, 0x9b3d, 0x3a3d, 0x5a5d, 0xbdbe, 0xbff7, 0xffff, 0xffff, 0xffff, 0xffff, 0xffff, 0xffff, 0xffff, 0xffff, 0xffff, 0xffff, 0xffff, 0xffff, 0xffff, 0xffff, 0xffff, 0xffff, 0xbef7, 0x9ef7, 0xbef7, 0x9ef7, 0x3cef, 0xfbe6, 0xbade, 0x99de, 0x79d6, 0x99de, 0x1ce7, 0xfbe6, 0x77ee, 0x55ee, 0x55ee, 0x55ee, 0x75ee, 0x96ee, 0xd8ee, 0xf9ee, 0xf9ee, 0xd8ee, 0xb7ee, 0x97ee, 0xb9e6, 0x5de7, 0x7ee7, 0xbff7, 0xffff, 0xffff, 0xffff, 0xdfff, 0xbef7, 0x5def, 0xb3a4, 0x0c6b, 0xec62, 0xeb62, 0xeb62, 0x0c6b, 0x6e73, 0x8e7b, 0x8e7b, 0x318c, 0x19ce, 0xffff, 0xffff, 0xffff, 0xbeef, 0xdca6, 0x5b6e, 0x3b6e, 0xfb65, 0x3b66, 0xbc8e, 0xfca6, 0xfca6, 0xfca6, 0x1996, 0xefbb, 0x2bdb, 0x8ce4, 0x2de5, 0xafe4, 0xb0e4, 0x4fe5, 0x50e5, 0x31e5, 0x8fe5, 0x53ed, 0x6fe5, 0x50e5, 0x14ed, 0x11e5, 0x4ee5,
  0x9934, 0xb93c, 0x5a3d, 0xbb3d, 0x9b3d, 0x5a45, 0x7ca6, 0x9fef, 0xffff, 0xffff, 0xffff, 0xdfff, 0xdfff, 0xdfff, 0xdfff, 0xffff, 0xffff, 0xffff, 0xffff, 0xffff, 0xffff, 0xffff, 0xffff, 0xffff, 0xffff, 0xbef7, 0x7def, 0x3ce7, 0xdade, 0x79d6, 0x58d6, 0x58d6, 0x79d6, 0x79d6, 0x79de, 0xdade, 0x1ce7, 0xfaee, 0xb7ee, 0x96ee, 0x96ee, 0x96ee, 0xb7ee, 0xd8ee, 0xf9ee, 0xf9ee, 0xf8ee, 0xf9ee, 0x3bef, 0x3de7, 0x7eef, 0x9eef, 0x7def, 0x5cef, 0x9ef7, 0xdfff, 0xbef7, 0xbef7, 0x59d6, 0xf08b, 0xec62, 0xeb62, 0xcb62, 0xec6a, 0x4d6b, 0x6d73, 0x6d73, 0x8e7b, 0xd3a4, 0x7df7, 0xffff, 0xffff, 0xffff, 0xffff, 0x9ee7, 0x7c86, 0x3b6e, 0xfb65, 0x1b66, 0x9c7e, 0xfc9e, 0xfca6, 0xfca6, 0x9b96, 0x15bd, 0x51e4, 0xd0e4, 0x8fe5, 0x8fe5, 0x52e5, 0x70e5, 0x6fe5, 0x2fe5, 0x8ee5, 0x72ed, 0x6fe5, 0x50ed, 0x14ed, 0x13ed, 0x6de5,
  0x993c, 0x9934, 0xfa3c, 0x5a3d, 0x9b3d, 0x1b7e, 0x7edf, 0xffff, 0xffff, 0xffff, 0xffff, 0xdfff, 0xdfff, 0xdfff, 0xbef7, 0xdfff, 0xffff, 0xffff, 0xdfff, 0xffff, 0xffff, 0xffff, 0xffff, 0xffff, 0xffff, 0xdfff, 0x9ef7, 0xfbe6, 0x99de, 0x79d6, 0x58d6, 0x79d6, 0x99d6, 0x99de, 0x79de, 0x99de, 0xfbe6, 0x5def, 0x5cf7, 0xf9ee, 0xd7ee, 0xd7ee, 0xd7ee, 0xf8ee, 0xf9ee, 0xf9ee, 0x1aef, 0x9df7, 0xbef7, 0x7ee7, 0x7eef, 0x5de7, 0x99de, 0x37ce, 0x17ce, 0xfbe6, 0x9ef7, 0x7def, 0x35ad, 0x6e7b, 0xec62, 0xcb62, 0xec62, 0x0c6b, 0x4d6b, 0x4d6b, 0x4d6b, 0x108c, 0x59d6, 0xffff, 0xffff, 0xffff, 0xffff, 0xffff, 0xffff, 0x1dc7, 0x3b76, 0xfb65, 0xfb5d, 0x7c76, 0xdc96, 0xfca6, 0xfca6, 0xbc96, 0xd8b5, 0x14dd, 0x31e5, 0x8fe5, 0xcfe5, 0x90e5, 0x50e5, 0x8ee5, 0x6fe5, 0x8fe5, 0xb0e5, 0x6ee5, 0x70e5, 0x33ed, 0x34ed, 0x6fe5,
  0x993c, 0x993c, 0xb93c, 0x1a3d, 0x7b45, 0xddbe, 0xbff7, 0xffff, 0xffff, 0xffff, 0xffff, 0xdfff, 0xdfff, 0xdfff, 0xbef7, 0xbef7, 0xffff, 0xffff, 0xffff, 0xffff, 0xffff, 0xffff, 0xffff, 0xffff, 0xffff, 0xffff, 0xbef7, 0x3ce7, 0xdade, 0xbade, 0x99d6, 0x99d6, 0x9ade, 0xbade, 0x99de, 0x99de, 0xdae6, 0x3cef, 0x9ef7, 0x9df7, 0x3aef, 0xf8ee, 0xf8ee, 0xf9ee, 0x1aef, 0x5bf7, 0xbeff, 0xffff, 0xbef7, 0x5de7, 0xfbde, 0x99de, 0x37ce, 0xd6c5, 0xb1a4, 0x5094, 0x9ad6, 0xfbe6, 0x7194, 0x0c6b, 0xcb62, 0xec62, 0x0c6b, 0x2d6b, 0x2d6b, 0x2d6b, 0xaf7b, 0x56b5, 0xbef7, 0xffff, 0xffff, 0xffff, 0xffff, 0xffff, 0xffff, 0xdff7, 0x7c96, 0xfb6d, 0xda5d, 0x5b6e, 0xdc8e, 0xdc9e, 0xdca6, 0xbc96, 0x19a6, 0x55cd, 0x71e5, 0x50e5, 0x50e5, 0xafe5, 0xaee5, 0x6ee5, 0x11e5, 0x32ed, 0x90e5, 0xaee5, 0x70e5, 0x33ed, 0x54ed, 0x51e5,
  0x993c, 0x993c, 0xb83c, 0xf944, 0x9a6d, 0x5edf, 0xdfff, 0xdfff, 0xffff, 0xffff, 0xffff, 0xffff, 0xdfff, 0xdfff, 0xbef7, 0x9ef7, 0xdfff, 0xffff, 0xffff, 0xffff, 0xffff, 0xffff, 0xffff, 0xffff, 0xffff, 0xffff, 0xdfff, 0x7def, 0x3ce7, 0x1ce7, 0xfbde, 0xbade, 0xdade, 0xdade, 0x9ade, 0x99de, 0xbade, 0xdbe6, 0x5cef, 0xbef7, 0x9df7, 0x1aef, 0xf9ee, 0x19ef, 0x3bf7, 0xbef7, 0xbef7, 0x9ef7, 0x1be7, 0xbade, 0x78d6, 0x58d6, 0x37ce, 0x34ad, 0x8a5a, 0x8639, 0xb29c, 0x76b5, 0xaf7b, 0xcb62, 0xec62, 0x2c6b, 0x2d6b, 0x2c6b, 0x2d6b, 0x4d73, 0xb39c, 0x5def, 0xffff, 0xffff, 0xffff, 0xffff, 0xffff, 0xffff, 0xffff, 0xffff, 0x1dcf, 0xfb75, 0xda5d, 0x3b66, 0xbc86, 0xdc9e, 0xdc9e, 0xdc9e, 0x5a9e, 0x75c5, 0x50e5, 0x30e5, 0xb2e4, 0x51e5, 0xeee5, 0x8de5, 0x11e5, 0x13ed, 0x13ed, 0x31e5, 0x70ed, 0x13ed, 0x53ed, 0x31ed,
  0x783c, 0x983c, 0x983c, 0xf94c, 0x3b9e, 0x9eef, 0xffff, 0xdfff, 0xffff, 0xffff, 0xffff, 0xffff, 0xdfff, 0xdfff, 0xdfff, 0x9ef7, 0x9ef7, 0xffff, 0xdfff, 0xffff, 0xffff, 0xdfff, 0xffff, 0xffff, 0xffff, 0xffff, 0xdfff, 0x9ef7, 0x7def, 0x5def, 0x3ce7, 0x1ce7, 0xfbde, 0xfbde, 0xbade, 0x99de, 0x9ade, 0xbade, 0xfbe6, 0x3cef, 0x9df7, 0x5bf7, 0xf9ee, 0x19ef, 0x3cef, 0xfae6, 0x98de, 0x98de, 0xb9de, 0xbade, 0xbade, 0xbade, 0x38ce, 0x0c6b, 0x8639, 0x4529, 0x084a, 0xeb62, 0xec62, 0xec62, 0x2c6b, 0x2d6b, 0x2c6b, 0x2c6b, 0x2d6b, 0x318c, 0x9ade, 0xdfff, 0xbef7, 0x9ef7, 0x9ef7, 0xdfff, 0xffff, 0xffff, 0xffff, 0xffff, 0xbef7, 0x3b86, 0xda65, 0xfb5d, 0x9c7e, 0xdc8e, 0xdc9e, 0xdca6, 0x7b8e, 0x96bd, 0x50e5, 0x11e5, 0xb2e4, 0xd2e4, 0x50e5, 0xade5, 0x50e5, 0x13ed, 0x14ed, 0x13ed, 0x70e5, 0x12ed, 0x72ed, 0x51ed,
  0x573c, 0x983c, 0x983c, 0xd94c, 0xdcc6, 0x9eef, 0xdfff, 0xdfff, 0xffff, 0xffff, 0xffff, 0xffff, 0xdfff, 0xbef7, 0xdfff, 0xbef7, 0x7df7, 0xdfff, 0xdfff, 0xffff, 0xffff, 0xdfff, 0xffff, 0xffff, 0xffff, 0xffff, 0xdfff, 0xbef7, 0x9ef7, 0x7def, 0x5def, 0x3ce7, 0x1ce7, 0x1ce7, 0xfbde, 0xbade, 0x99de, 0x9ade, 0xbade, 0xdae6, 0x3cef, 0x5cf7, 0xf9ee, 0x1bef, 0x1be7, 0xdade, 0x99de, 0xb9de, 0xfade, 0xfbe6, 0x1be7, 0xbad6, 0x8e7b, 0xc741, 0xa639, 0xe841, 0x6952, 0xab5a, 0xeb62, 0x0c6b, 0x2c6b, 0x0c6b, 0x0c6b, 0x2c6b, 0x8e7b, 0x75b5, 0x9ef7, 0x9ef7, 0x7def, 0x7def, 0x7def, 0xbef7, 0xffff, 0xffff, 0xffff, 0xffff, 0xffff, 0xbcae, 0xda6d, 0xda5d, 0x7c76, 0xbc86, 0xdc96, 0xfc9e, 0x9b86, 0xd6ad, 0x51dd, 0x11e5, 0xb2e4, 0xb2e4, 0x10e5, 0x8ce5, 0x6ee5, 0x13ed, 0xf3ec, 0x33ed, 0x70ed, 0x31ed, 0x91ed, 0x8fe5,
  0x373c, 0x783c, 0x9844, 0x5a75, 0x5edf, 0x7def, 0x9ef7, 0xbef7, 0xffff, 0xffff, 0xffff, 0xffff, 0xdfff, 0xbef7, 0xbef7, 0xbef7, 0x9ef7, 0xbef7, 0xbef7, 0xffff, 0xffff, 0xdfff, 0xffff, 0xffff, 0xffff, 0xffff, 0xdfff, 0xdfff, 0xbef7, 0x9ef7, 0x7def, 0x5def, 0x3ce7, 0x3ce7, 0x1ce7, 0xfbde, 0xbade, 0xbade, 0xbade, 0xbade, 0xfbe6, 0x5cef, 0x3bef, 0x3ce7, 0x1be7, 0xfbde, 0xdade, 0xfbde, 0x1be7, 0x3ce7, 0xdbde, 0x318c, 0x0842, 0xe741, 0x284a, 0x6952, 0x8a5a, 0xcb62, 0xec62, 0x0c63, 0x0c63, 0x0c6b, 0x2c6b, 0x8e7b, 0x14ad, 0xfbe6, 0x9ef7, 0xdfff, 0xbef7, 0x9ef7, 0x7def, 0x7def, 0xbef7, 0xffff, 0xffff, 0xffff, 0xffff, 0x5ddf, 0xfa75, 0xba5d, 0x5b6e, 0x9c7e, 0xbc86, 0xdc96, 0xbc96, 0x189e, 0x73cd, 0x12ed, 0xd3e4, 0xd2e4, 0x10e5, 0x6de5, 0x6ee5, 0x31e5, 0x14ed, 0x33ed, 0x51e5, 0x4fe5, 0x52ed, 0xeeed,
  0x3744, 0x3644, 0x7844, 0xfb9d, 0x9eef, 0x9ef7, 0x3ce7, 0x7def, 0xdfff, 0xffff, 0xffff, 0xffff, 0xffff, 0xbef7, 0x9ef7, 0xbef7, 0x9ef7, 0x9ef7, 0xbef7, 0xdfff, 0xdfff, 0xdfff, 0xdfff, 0xdfff, 0xdfff, 0xdfff, 0xdfff, 0xdfff, 0xbef7, 0xbef7, 0x9ef7, 0x7def, 0x5def, 0x5def, 0x5def, 0x3ce7, 0x1be7, 0x1be7, 0x1be7, 0x1be7, 0x1ce7, 0x5def, 0x7def, 0x5def, 0x5def, 0x1ce7, 0xfbe6, 0x1ce7, 0x3ce7, 0xdbde, 0x7194, 0x294a, 0x0842, 0x494a, 0x6952, 0x8a52, 0xaa5a, 0xeb62, 0x0c63, 0xec62, 0xec62, 0x0c6b, 0x6e73, 0x14ad, 0x3cef, 0xbef7, 0x9ef7, 0xdfff, 0xffff, 0xbeff, 0x7def, 0x5def, 0x9ef7, 0xdfff, 0xffff, 0xffff, 0xffff, 0xdfff, 0x3b8e, 0xb95d, 0x1b66, 0x9c76, 0xbc7e, 0xdc8e, 0xdc9e, 0x3a96, 0x55bd, 0xd2ec, 0xf3ec, 0xf2e4, 0x0fe5, 0x4ee5, 0x4fe5, 0x8fe5, 0x33ed, 0x34ed, 0x52ed, 0x6de5, 0xf3ec, 0x33ed,
  0x3744, 0x1644, 0x574c, 0xbcc6, 0xbef7, 0x9ef7, 0x3ce7, 0x7def, 0xdfff, 0xffff, 0xffff, 0xffff, 0xffff, 0xdfff, 0x9ef7, 0x9ef7, 0x9ef7, 0x9ef7, 0xbef7, 0xbef7, 0xdfff, 0xbef7, 0xbef7, 0xdfff, 0xdfff, 0xdfff, 0xdfff, 0xbef7, 0xbef7, 0xbef7, 0x9ef7, 0x9ef7, 0x7def, 0x7def, 0x7def, 0x5def, 0x5def, 0x5def, 0x5def, 0x7def, 0x7def, 0x7def, 0x7def, 0x7def, 0x7def, 0x5def, 0x5def, 0x5def, 0xdbde, 0xb29c, 0x4952, 0x294a, 0x494a, 0x6952, 0x6952, 0x8a5a, 0xcb5a, 0xeb62, 0xec62, 0xec62, 0x0c6b, 0x4d73, 0xb39c, 0xbbde, 0xdfff, 0xdfff, 0xbef7, 0xbef7, 0xdfff, 0xdfff, 0x9ef7, 0x7def, 0x7def, 0xbef7, 0xffff, 0xffff, 0xffff, 0xffff, 0x3b8e, 0x9945, 0xda55, 0x7c6e, 0x9c7e, 0xbc86, 0xbc96, 0x7b8e, 0x76b5, 0xf3e4, 0xf3ec, 0xf2e4, 0x0fe5, 0x30e5, 0x11e5, 0x8ee5, 0x51e5, 0x13ed, 0x32ed, 0x8de5, 0xf1ec, 0x14ed,
  0x3744, 0x3644, 0x9764, 0x3ddf, 0xbef7, 0x9ef7, 0x7def, 0x7def, 0xdfff, 0xffff, 0xffff, 0xffff, 0xffff, 0xdfff, 0x9ef7, 0x9ef7, 0x7df7, 0x7df7, 0x9ef7, 0xbef7, 0xbef7, 0xbef7, 0xbef7, 0xbef7, 0xbef7, 0xbef7, 0xbef7, 0xbef7, 0xbef7, 0xbef7, 0xbef7, 0x9ef7, 0x7df7, 0x7def, 0x9ef7, 0x7def, 0x7def, 0x7def, 0x9ef7, 0x9ef7, 0x9ef7, 0x9df7, 0x9ef7, 0xbef7, 0xbef7, 0x7def, 0x7def, 0xfbde, 0xb29c, 0x6952, 0x294a, 0x6952, 0x6952, 0x6952, 0x8a52, 0xab5a, 0xeb62, 0xeb62, 0xcb62, 0x0c63, 0x4d6b, 0x7294, 0x9ad6, 0xbef7, 0xdfff, 0xffff, 0xdfff, 0xbef7, 0xdfff, 0xffff, 0xbeff, 0x7def, 0x7def, 0xbef7, 0xffff, 0xffff, 0xffff, 0xdfff, 0x3b7e, 0x5935, 0x9945, 0x3b66, 0x9c76, 0x7c6e, 0x7b76, 0x5b76, 0x97a5, 0xf3e4, 0xd3e4, 0xf2e4, 0x2fe5, 0x10ed, 0xf2ec, 0x50e5, 0x8ee5, 0x51ed, 0x13ed, 0x6ee5, 0x2fe5, 0xf3ec,
  0x1644, 0x3744, 0x598d, 0x7eef, 0xdfff, 0x9ef7, 0x9ef7, 0x9ef7, 0xdfff, 0xffff, 0xffff, 0xffff, 0xffff, 0xdfff, 0xbef7, 0x9ef7, 0x7def, 0x5def, 0x7def, 0xbef7, 0xbef7, 0xbef7, 0x9ef7, 0x9ef7, 0x9ef7, 0xbef7, 0xbef7, 0xbef7, 0xbef7, 0xbef7, 0xbef7, 0xbef7, 0x9ef7, 0x9ef7, 0x9ef7, 0x9ef7, 0x9ef7, 0x9ef7, 0x9ef7, 0x9ef7, 0x9ef7, 0xbef7, 0xdfff, 0xdfff, 0xdfff, 0x7def, 0x1ce7, 0xf4a4, 0x8a52, 0x294a, 0x494a, 0x6952, 0x6952, 0x6a52, 0xaa5a, 0xcb5a, 0xcb62, 0xcb62, 0xec62, 0x2c6b, 0x318c, 0x59d6, 0xbfff, 0xffff, 0xdfff, 0xdfff, 0xffff, 0xffff, 0xffff, 0xffff, 0xdfff, 0x9ef7, 0x9ef7, 0xbef7, 0xffff, 0xdfff, 0xdfff, 0xbef7, 0x5b7e, 0x5935, 0x592d, 0xfa5d, 0x7c76, 0x5c5e, 0x1b4e, 0x1b56, 0x5795, 0xd3dc, 0xd3e4, 0xf1e4, 0x4fe5, 0x30ed, 0xd3ec, 0xf2e4, 0x4fe5, 0xaee5, 0x70e5, 0x6fe5, 0x6ce5, 0xd2ec,
  0xf643, 0x364c, 0x3bb6, 0xbef7, 0xdfff, 0x9ef7, 0x9ef7, 0x9ef7, 0xdfff, 0xffff, 0xffff, 0xffff, 0xffff, 0xffff, 0xbef7, 0x9ef7, 0x7def, 0x5def, 0x7def, 0xbef7, 0xbef7, 0xbef7, 0x9ef7, 0x7def, 0x9ef7, 0x9ef7, 0x9ef7, 0xbef7, 0xbef7, 0xbef7, 0xbef7, 0xbef7, 0xbef7, 0x9ef7, 0x9ef7, 0xbef7, 0x9ef7, 0x9ef7, 0x9ef7, 0x9ef7, 0xbef7, 0xdfff, 0xdfff, 0xffff, 0xdfff, 0x3ce7, 0x55b5, 0xcb5a, 0x294a, 0x494a, 0x494a, 0x6952, 0x6a52, 0x8a52, 0xab5a, 0xcb5a, 0xcb5a, 0xeb62, 0x0c6b, 0x108c, 0x38ce, 0x9ef7, 0xffff, 0xdfff, 0xdfff, 0xdfff, 0xffff, 0xffff, 0xffff, 0xffff, 0xdfff, 0x9ef7, 0x9ef7, 0xbef7, 0xffff, 0xbef7, 0xbef7, 0xbef7, 0xbc9e, 0x9a3d, 0x392d, 0x9945, 0x3b66, 0x5b66, 0xfb3d, 0xdb35, 0x577d, 0xb3d4, 0xd3ec, 0x12e5, 0x4fe5, 0x30e5, 0xd2ec, 0xf3ec, 0x31ed, 0xcde5, 0x8de5, 0x8de5, 0x8bdd, 0x0fe5,
  0xf643, 0x3654, 0x1ddf, 0xdfff, 0xdfff, 0x9ef7, 0x7def, 0x9ef7, 0xbef7, 0xdfff, 0xffff, 0xffff, 0xdfff, 0xffff, 0xdfff, 0x9ef7, 0x7def, 0x5def, 0x7def, 0x9ef7, 0xdfff, 0xbef7, 0x9ef7, 0x7def, 0x9ef7, 0x9ef7, 0x9ef7, 0x9ef7, 0xbef7, 0xbef7, 0xbef7, 0xbef7, 0xbef7, 0x9ef7, 0xbef7, 0xbef7, 0xbef7, 0x9ef7, 0x9ef7, 0x9ef7, 0xdfff, 0xdfff, 0xdfff, 0xdfff, 0x5def, 0xb7bd, 0xec62, 0x294a, 0x494a, 0x494a, 0x494a, 0x6952, 0x8a52, 0xaa5a, 0xaa5a, 0xab5a, 0xcb62, 0x0c63, 0xaf83, 0xf8c5, 0x9ef7, 0xffff, 0xffff, 0xbef7, 0x9ef7, 0xdfff, 0xffff, 0xffff, 0xffff, 0xdfff, 0xbef7, 0x9ef7, 0x9ef7, 0xbef7, 0xffff, 0xbef7, 0x9ef7, 0x9ef7, 0x1cbf, 0xda4d, 0x3925, 0x182d, 0xda4d, 0x5b5e, 0xfb3d, 0xbb2d, 0x576d, 0xd3c4, 0xb2ec, 0xf1ec, 0x2fe5, 0x30e5, 0xb2ec, 0xf3ec, 0x31ed, 0x8fed, 0x30e5, 0x8de5, 0x6ddd, 0x4cdd,
  0xf543, 0xb774, 0x7eef, 0xffff, 0xffff, 0x9ef7, 0x5def, 0x7def, 0x9ef7, 0xdfff, 0xdfff, 0xdfff, 0xdfff, 0xdfff, 0xdfff, 0xbef7, 0x7def, 0x7def, 0x7def, 0x9ef7, 0xbef7, 0x9ef7, 0x9ef7, 0x7def, 0x9ef7, 0x7def, 0x9ef7, 0x9ef7, 0x9ef7, 0xbef7, 0xbef7, 0xbef7, 0xbef7, 0x9ef7, 0xbef7, 0xbef7, 0xbef7, 0x9ef7, 0x9ef7, 0xbef7, 0xdfff, 0xdfff, 0xdfff, 0x7def, 0x18c6, 0x2d6b, 0x494a, 0x494a, 0x494a, 0x494a, 0x494a, 0x8a52, 0xaa5a, 0xaa5a, 0xaa5a, 0xcb62, 0x0c63, 0x6e7b, 0xb7bd, 0x7def, 0xffff, 0xffff, 0xffff, 0xbef7, 0x9ef7, 0xbef7, 0xffff, 0xffff, 0xffff, 0xbef7, 0x9ef7, 0x9ef7, 0x9ef7, 0xbef7, 0xdfff, 0xbef7, 0x9ef7, 0xbef7, 0x5ddf, 0x3b5e, 0x7a2d, 0x1825, 0x593d, 0x1a56, 0x1b46, 0xdb2d, 0x5765, 0xd3bc, 0xb2ec, 0xf1e4, 0x2fe5, 0x2fe5, 0xb2ec, 0xf2e4, 0x51e5, 0x70e5, 0xf2e4, 0x4ee5, 0x30e5, 0x6bdd,
  0xf643, 0x999d, 0x9ef7, 0xffff, 0xffff, 0xbef7, 0x5def, 0x5def, 0x7def, 0xdfff, 0xdfff, 0xdfff, 0xdfff, 0xdfff, 0xdfff, 0xbef7, 0x7def, 0x7def, 0x9ef7, 0x9ef7, 0xbef7, 0x9ef7, 0x7def, 0x7def, 0x9ef7, 0x7def, 0x9ef7, 0x9ef7, 0x9ef7, 0x9ef7, 0x9ef7, 0xbef7, 0xbef7, 0x9ef7, 0xbef7, 0xbef7, 0xbef7, 0x9ef7, 0x9ef7, 0xdfff, 0xffff, 0xdfff, 0x9ef7, 0x59ce, 0x6e73, 0x4952, 0x6a52, 0x694a, 0x494a, 0x494a, 0x6a52, 0x8a52, 0x8a5a, 0xaa5a, 0xcb5a, 0xec62, 0x0c6b, 0x76b5, 0x5def, 0xffff, 0xffff, 0xffff, 0xdfff, 0xbef7, 0x9ef7, 0xbef7, 0xdfff, 0xffff, 0xbeff, 0xbef7, 0xbef7, 0xbef7, 0xbef7, 0xbef7, 0xdfff, 0xdfff, 0xbef7, 0xbef7, 0x9def, 0x7b7e, 0xba35, 0x191d, 0xb724, 0x994d, 0x1b4e, 0xdb35, 0x384d, 0xb4ac, 0xb2ec, 0xf2ec, 0x4fe5, 0x2fe5, 0xb2e4, 0xf2e4, 0x51e5, 0x6fe5, 0xf2e4, 0x2ee5, 0xf1e4, 0x2fe5,
  0xf64b, 0x7bc6, 0xdff7, 0xffff, 0xffff, 0xbef7, 0x5def, 0x3ce7, 0x5def, 0x9ef7, 0xdfff, 0xdfff, 0xdfff, 0xbef7, 0xbef7, 0xdfff, 0x9ef7, 0x7def, 0x9ef7, 0x9ef7, 0xbef7, 0x9ef7, 0x7def, 0x7def, 0x9ef7, 0x7def, 0x7def, 0x9ef7, 0x9ef7, 0x9ef7, 0x9ef7, 0x9ef7, 0x9ef7, 0x9ef7, 0x9ef7, 0xbef7, 0x9ef7, 0x9ef7, 0xbef7, 0xbef7, 0xbef7, 0x9ef7, 0x7ad6, 0xd083, 0x6952, 0x6a52, 0x6a52, 0x494a, 0x494a, 0x6952, 0x8a52, 0x8a52, 0x8a52, 0xcb5a, 0xec62, 0xec62, 0xd3a4, 0xbbde, 0xbef7, 0xffff, 0xffff, 0xffff, 0xdfff, 0xbef7, 0x9ef7, 0x9ef7, 0x9ef7, 0x9ef7, 0x9ef7, 0x9ef7, 0xdfff, 0xdfff, 0xdfff, 0xbef7, 0xdfff, 0xdfff, 0xbef7, 0xbef7, 0xbef7, 0xdc9e, 0x1b4e, 0x3925, 0x771c, 0xb72c, 0x9a45, 0xba35, 0xf73c, 0x939c, 0xb2ec, 0xf2ec, 0x50e5, 0x4ee5, 0xb2e4, 0xf2e4, 0x51e5, 0x6fe5, 0xf2e4, 0x2ee5, 0x11e5, 0xd2e4,
  0x365c, 0x5de7, 0xdfff, 0xffff, 0xffff, 0xdfff, 0x7def, 0x3ce7, 0x3ce7, 0x7def, 0xdfff, 0xffff, 0xdfff, 0xbef7, 0xbef7, 0xdfff, 0x9ef7, 0x7def, 0x7def, 0x9ef7, 0xbef7, 0x9ef7, 0x7def, 0x9ef7, 0x9ef7, 0x7def, 0x7def, 0x9ef7, 0x9ef7, 0x9ef7, 0x9ef7, 0x9ef7, 0x9ef7, 0x9ef7, 0x9ef7, 0x9ef7, 0x9ef7, 0x9ef7, 0x9ef7, 0xbef7, 0x9ef7, 0xbad6, 0x5294, 0x6a52, 0x6a52, 0x8a52, 0x494a, 0x294a, 0x6952, 0x6a52, 0x8a52, 0x8a52, 0xab5a, 0xcb5a, 0xec62, 0x929c, 0xfbe6, 0x9ef7, 0x9ef7, 0xbef7, 0xffff, 0xffff, 0xdfff, 0xbef7, 0x9ef7, 0x9ef7, 0x9ef7, 0x9ef7, 0x9ef7, 0xbef7, 0xffff, 0xdfff, 0xbef7, 0xbef7, 0xbef7, 0xdfff, 0xdfff, 0xbef7, 0xbef7, 0x1cbf, 0x5b66, 0x9a2d, 0x9724, 0x5624, 0xd72c, 0x7a2d, 0xf82c, 0x748c, 0xb2e4, 0xd2e4, 0x4fe5, 0x6de5, 0xb1e4, 0xd2e4, 0x51e5, 0x8fe5, 0xf2e4, 0x0ddd, 0x2cd4, 0xead2,
  0xf87c, 0x9eef, 0xffff, 0xffff, 0xffff, 0xdfff, 0x9ef7, 0x5def, 0x3ce7, 0x5def, 0xbef7, 0xffff, 0xdfff, 0xbef7, 0xbef7, 0xbef7, 0xbef7, 0x7def, 0x7def, 0x7def, 0xbef7, 0x9ef7, 0x7def, 0x9ef7, 0x9ef7, 0x7def, 0x7def, 0x9ef7, 0x9ef7, 0x9ef7, 0x9ef7, 0x9ef7, 0x9ef7, 0x7df7, 0x9ef7, 0x9ef7, 0x9ef7, 0x9ef7, 0x9ef7, 0x9ef7, 0xfce6, 0xf4a4, 0x8a52, 0x6a52, 0x6a52, 0x494a, 0x294a, 0x6952, 0x6a52, 0x8a52, 0x6a52, 0xaa5a, 0xcb5a, 0xec62, 0x5194, 0xfbde, 0xbef7, 0xdfff, 0x9ef7, 0x9ef7, 0xdfff, 0xffff, 0xdfff, 0xbef7, 0x9ef7, 0x9ef7, 0x9ef7, 0x9ef7, 0xbef7, 0xdfff, 0xffff, 0xdfff, 0xbef7, 0xbef7, 0xbef7, 0xdfff, 0xffff, 0xdfff, 0xbef7, 0x3dcf, 0x9c7e, 0xfb45, 0xf824, 0x3624, 0x3624, 0x9624, 0x5524, 0x337c, 0x92dc, 0xd2e4, 0x2fe5, 0x6de5, 0xd1e4, 0xb2e4, 0xf0e4, 0x2ddd, 0xcdcb, 0x6ad4, 0xa9cb, 0x68d2,
  0xdaad, 0x9ef7, 0xdfff, 0xffff, 0xffff, 0xdfff, 0xbef7, 0x5def, 0x5def, 0x5def, 0x9ef7, 0xdfff, 0xffff, 0xffff, 0xdfff, 0xbef7, 0xbef7, 0x9ef7, 0x7df7, 0x7def, 0xbef7, 0x9ef7, 0x7def, 0x9ef7, 0x9ef7, 0x7def, 0x7def, 0x9ef7, 0x7df7, 0x7def, 0x7def, 0x9ef7, 0x7def, 0x7def, 0x7def, 0x7def, 0x9ef7, 0x9ef7, 0x9ef7, 0x3ce7, 0x76b5, 0xec62, 0x6952, 0x6a52, 0x494a, 0x284a, 0x494a, 0x6a52, 0x6a52, 0x6a52, 0x8a52, 0xab5a, 0xcb62, 0xf083, 0xbad6, 0xdfff, 0xffff, 0xffff, 0xbef7, 0x9ef7, 0xbef7, 0xdfff, 0xdfff, 0x9ef7, 0x9ef7, 0x9ef7, 0x9ef7, 0x9ef7, 0xbef7, 0xbef7, 0xbeff, 0xbef7, 0x9ef7, 0x9ef7, 0xbef7, 0xdfff, 0xffff, 0xffff, 0xdfff, 0x5ddf, 0xbc86, 0x3b4e, 0x9a35, 0x9724, 0x1524, 0xf523, 0xb32b, 0xf26b, 0x72cc, 0xb2e4, 0x0fe5, 0x6ce5, 0xcfdc, 0xeed3, 0xebcb, 0xcad4, 0xeac2, 0x09cc, 0xe9cb, 0x27b2,
  0xbcce, 0x9ef7, 0xdfff, 0xffff, 0xffff, 0xffff, 0xbef7, 0x7def, 0x5def, 0x5def, 0x7def, 0xbef7, 0xffff, 0xffff, 0xdfff, 0xdfff, 0xbef7, 0x9ef7, 0x9ef7, 0x7def, 0xbef7, 0xbef7, 0x9ef7, 0x9ef7, 0x7def, 0x5def, 0x7def, 0x7def, 0x7def, 0x5def, 0x7def, 0x7def, 0x7def, 0x7def, 0x7def, 0x7def, 0x7def, 0x9def, 0x3de7, 0xb7bd, 0x4e73, 0x6a52, 0x6a52, 0x294a, 0x284a, 0x494a, 0x6952, 0x6952, 0x6a52, 0x8a52, 0xab5a, 0xcb5a, 0xaf7b, 0x7ad6, 0x9ef7, 0xdfff, 0xffff, 0xffff, 0xdfff, 0x9ef7, 0x9ef7, 0xbef7, 0xbef7, 0x9ef7, 0x7df7, 0x9ef7, 0x9ef7, 0xbef7, 0xdfff, 0xbeff, 0xbef7, 0x9ef7, 0x9ef7, 0xbef7, 0xbef7, 0xdfff, 0xffff, 0xffff, 0xffff, 0x7ee7, 0x7c76, 0x3b56, 0xfb3d, 0xf824, 0x1524, 0xb42b, 0x732b, 0xb25b, 0x52b4, 0x71dc, 0xaedc, 0x2bdd, 0x4bd4, 0xa9c2, 0x49c3, 0xcad4, 0xe9ba, 0xc9c3, 0x48c4, 0x07a2,
  0x7def, 0x9ef7, 0xbef7, 0xffff, 0xffff, 0xffff, 0xdfff, 0x9ef7, 0x5def, 0x5def, 0x5def, 0x9ef7, 0xdfff, 0xffff, 0xdfff, 0xdfff, 0xbef7, 0x9ef7, 0x9ef7, 0x7def, 0xbef7, 0xbef7, 0x9ef7, 0x9ef7, 0x7def, 0x5def, 0x5def, 0x5def, 0x3cef, 0x3ce7, 0x5def, 0x5def, 0x5def, 0x5def, 0x5def, 0x7def, 0x7def, 0x5def, 0xf8c5, 0xaf7b, 0x6a52, 0x6952, 0x494a, 0x284a, 0x494a, 0x6a52, 0x6952, 0x6952, 0x6a52, 0x8b5a, 0xab5a, 0x8e7b, 0xf7c5, 0x7def, 0xbef7, 0xdfff, 0xdfff, 0xffff, 0xffff, 0xbef7, 0x9ef7, 0xbef7, 0xbef7, 0x9ef7, 0x7df7, 0x9ef7, 0x9ef7, 0xbef7, 0xdfff, 0xbef7, 0x9ef7, 0x9ef7, 0xbef7, 0xbef7, 0xbef7, 0xbef7, 0xdfff, 0xffff, 0xffff, 0x7ee7, 0x5c76, 0x3b56, 0x1b46, 0x792d, 0x5624, 0xb42b, 0x532b, 0x5143, 0x8f93, 0x6ccb, 0xabcb, 0xaad4, 0x4acc, 0x68aa, 0xe8aa, 0x69c4, 0xe8b2, 0x68b3, 0xa9cc, 0x27a2,
  0xbef7, 0xbef7, 0xbef7, 0xffff, 0xffff, 0xffff, 0xffff, 0xbef7, 0x7def, 0x5def, 0x5def, 0x7def, 0xdfff, 0xffff, 0xffff, 0xdfff, 0xbef7, 0x9ef7, 0x9ef7, 0x7def, 0xbef7, 0xbef7, 0x9ef7, 0x9ef7, 0x7def, 0x3ce7, 0x5def, 0x5def, 0x3ce7, 0x3ce7, 0x5def, 0x5def, 0x3ce7, 0x5def, 0x5def, 0x5def, 0x3ce7, 0x18c6, 0xd083, 0x6a52, 0x494a, 0x294a, 0x284a, 0x494a, 0x6952, 0x6952, 0x4952, 0x6a52, 0x8a52, 0xab5a, 0x4d73, 0xf8c5, 0x5def, 0x5def, 0x9ef7, 0x9ef7, 0xbef7, 0xffff, 0xffff, 0xdfff, 0x9ef7, 0x9ef7, 0x9ef7, 0x9ef7, 0x9ef7, 0x9ef7, 0xbef7, 0xdfff, 0xbef7, 0x9ef7, 0x9ef7, 0xbef7, 0xbef7, 0xbef7, 0xbef7, 0xbef7, 0xdfff, 0xffff, 0xdfff, 0x7def, 0x5b76, 0x1b4e, 0x3b4e, 0xdb35, 0xb724, 0xb423, 0x532b, 0x1133, 0xcd72, 0x89b2, 0xe8b2, 0x29c4, 0x89cc, 0xa7a2, 0x87a2, 0xc8b3, 0x68b3, 0xe8aa, 0x29d5, 0x47a2,
  0xbef7, 0xdfff, 0x9ef7, 0xdfff, 0xffff, 0xffff, 0xffff, 0xdfff, 0x9ef7, 0x5def, 0x5def, 0x5def, 0xbef7, 0xffff, 0xffff, 0xffff, 0xbef7, 0x7def, 0x7def, 0x7def, 0xbef7, 0xbef7, 0x9ef7, 0x9ef7, 0x7def, 0x5def, 0x5def, 0x5def, 0x3ce7, 0x5def, 0x5def, 0x3ce7, 0x3ce7, 0x5def, 0x5def, 0x3ce7, 0x39ce, 0xf083, 0x6a52, 0x294a, 0x284a, 0x284a, 0x294a, 0x4952, 0x6a52, 0x6952, 0x6952, 0x8a52, 0xab5a, 0x2d6b, 0xb7bd, 0x5def, 0xbef7, 0x7def, 0x5def, 0x7def, 0x9ef7, 0xdfff, 0xffff, 0xdfff, 0xbef7, 0x9ef7, 0x9ef7, 0x9ef7, 0x9ef7, 0x9ef7, 0xbef7, 0xbef7, 0xbef7, 0xbef7, 0xdfff, 0xdfff, 0xbef7, 0xbef7, 0xbef7, 0xbef7, 0xdfff, 0xffff, 0xdfff, 0x7eef, 0x5c76, 0x1b4e, 0x1c46, 0x1b3e, 0x392d, 0xf523, 0x522b, 0x112b, 0xad62, 0x489a, 0x67a2, 0xa8b3, 0xe9cc, 0x48ab, 0x67a2, 0x48ab, 0xe8bb, 0x87a2, 0x29d5, 0xc7aa,
  0xbef7, 0xdfff, 0xbef7, 0xbef7, 0xdfff, 0xffff, 0xffff, 0xffff, 0xbef7, 0x7def, 0x5def, 0x5def, 0x9ef7, 0xdfff, 0xffff, 0xdfff, 0x9ef7, 0x7def, 0x7def, 0x7def, 0x9ef7, 0xbef7, 0x9ef7, 0x9ef7, 0x7def, 0x5def, 0x5def, 0x7def, 0x3ce7, 0x5def, 0x5def, 0x3ce7, 0x3ce7, 0x5def, 0x3ce7, 0x7ad6, 0x518c, 0x6a52, 0x284a, 0x0842, 0x0842, 0x284a, 0x494a, 0x4952, 0x4a52, 0x4952, 0x6a52, 0x8b5a, 0x0c63, 0x34ad, 0x3ce7, 0x7def, 0xbef7, 0xbef7, 0x5def, 0x3ce7, 0x5def, 0x9ef7, 0xdfff, 0xffff, 0xdfff, 0xbef7, 0x9ef7, 0x9ef7, 0x9ef7, 0x9ef7, 0xbef7, 0xbef7, 0xdfff, 0xdfff, 0xdfff, 0xbef7, 0xbef7, 0x9ef7, 0x9ef7, 0xbef7, 0xbef7, 0xffff, 0xdfff, 0x9eef, 0x5b7e, 0xfb45, 0xfb45, 0x1c3e, 0x9a2d, 0x3624, 0x522b, 0xf02a, 0x8d52, 0x488a, 0x27a2, 0x28ab, 0xc9cc, 0xe9bb, 0x279a, 0xc7a2, 0x49c4, 0x67a2, 0xa9c4, 0xa7b3,
  0xbef7, 0xdfff, 0xdfff, 0xbef7, 0xdfff, 0xffff, 0xffff, 0xffff, 0xdfff, 0x9ef7, 0x7def, 0x5def, 0x7def, 0xbef7, 0xdfff, 0xbef7, 0x7def, 0x7def, 0x9ef7, 0x7def, 0x9ef7, 0xbef7, 0x9ef7, 0x9ef7, 0x7def, 0x5def, 0x5def, 0x7def, 0x3ce7, 0x5def, 0x5def, 0x3ce7, 0x3ce7, 0x3ce7, 0xdbde, 0xb39c, 0xab5a, 0x0842, 0x0842, 0x0842, 0x084a, 0x494a, 0x494a, 0x494a, 0x494a, 0x6a52, 0x8b5a, 0x2d6b, 0x96b5, 0xdade, 0x1ce7, 0x5def, 0x7def, 0xbef7, 0x9ef7, 0x5def, 0x3ce7, 0x5def, 0x9ef7, 0xdfff, 0xdfff, 0xbef7, 0xbef7, 0x9ef7, 0x9ef7, 0x9ef7, 0x9ef7, 0xbef7, 0xdfff, 0xdfff, 0xbef7, 0x9ef7, 0x9ef7, 0x9ef7, 0x9ef7, 0x9ef7, 0xbef7, 0xffff, 0xdfff, 0x9ef7, 0x5b7e, 0xdb45, 0xdb3d, 0x1b3e, 0xdb35, 0x9724, 0x932b, 0x112b, 0x8d4a, 0x4982, 0x27a2, 0xc7a2, 0x69c4, 0xa9c4, 0x679a, 0x87a2, 0xe8bb, 0xc7a2, 0xa8b3, 0xa8c4,
  0xffff, 0xdfff, 0xdfff, 0xdfff, 0xdfff, 0xffff, 0xffff, 0xffff, 0xffff, 0xdfff, 0x9ef7, 0x9ef7, 0x9ef7, 0xbef7, 0xdfff, 0xbef7, 0x5def, 0x5def, 0x9ef7, 0x7def, 0x9ef7, 0xbef7, 0x9ef7, 0x9ef7, 0x7def, 0x5def, 0x5def, 0x7def, 0x3ce7, 0x5def, 0x5def, 0x3ce7, 0x3ce7, 0x1ce7, 0x15a5, 0xcb62, 0x0842, 0x0842, 0x0842, 0x0842, 0x294a, 0x494a, 0x494a, 0x494a, 0x6a52, 0x8a52, 0x0d6b, 0x96bd, 0x5def, 0x5def, 0x1ce7, 0x1ce7, 0x3ce7, 0x7def, 0x9ef7, 0x7def, 0x5def, 0x3ce7, 0x5def, 0x9ef7, 0x9ef7, 0x9ef7, 0x9ef7, 0x9ef7, 0x9ef7, 0x9ef7, 0x9ef7, 0xbef7, 0xbef7, 0xbef7, 0xbef7, 0x9ef7, 0x9ef7, 0x9ef7, 0x9ef7, 0x9ef7, 0xbef7, 0xdfff, 0xdfff, 0x9ef7, 0x3b86, 0xba45, 0xba35, 0xdb3d, 0xdb35, 0x1825, 0xd423, 0x1133, 0xce4a, 0x6a7a, 0x479a, 0x67a2, 0xc8b3, 0x09cd, 0x07ab, 0x479a, 0x27ab, 0xa8b3, 0xa7a2, 0x69d5,
  0xffff, 0xffff, 0xdfff, 0xbef7, 0xdfff, 0xffff, 0xffff, 0xffff, 0xffff, 0xdfff, 0xbef7, 0x9ef7, 0x9ef7, 0x9ef7, 0xdfff, 0xdfff, 0x7def, 0x5def, 0x9ef7, 0x7def, 0x9ef7, 0xbef7, 0x9ef7, 0x9ef7, 0x7def, 0x5def, 0x7def, 0x7def, 0x3ce7, 0x5def, 0x5def, 0x3ce7, 0x1ce7, 0xd7bd, 0x4d6b, 0xe841, 0xe841, 0xe841, 0x0842, 0x294a, 0x494a, 0x494a, 0x494a, 0x4a52, 0x8a52, 0x2d6b, 0xd7bd, 0x7def, 0xbef7, 0x7df7, 0x3ce7, 0x1ce7, 0x1ce7, 0x5def, 0x9ef7, 0x9ef7, 0x5def, 0x5def, 0x5def, 0x5def, 0x7def, 0x7def, 0x9ef7, 0x9ef7, 0x7def, 0x7def, 0x7def, 0x9ef7, 0x9ef7, 0xbef7, 0xbef7, 0xbef7, 0x9ef7, 0x9ef7, 0x9ef7, 0xbef7, 0xbef7, 0xdfff, 0xdfff, 0x9ef7, 0x3b8e, 0x7a35, 0x9a35, 0xbb35, 0xbb35, 0x5a2d, 0x152c, 0x3133, 0x0f4b, 0x2b7b, 0xa7a2, 0x279a, 0x28ab, 0xe9d4, 0xc8bb, 0x279a, 0x87a2, 0x29bc, 0x479a, 0x88cc,
  0xbef7, 0xffff, 0xffff, 0xdfff, 0xffff, 0xffff, 0xffff, 0xffff, 0xffff, 0xffff, 0xbef7, 0x9ef7, 0x7df7, 0x9ef7, 0xbef7, 0xdfff, 0xbef7, 0x7def, 0xbef7, 0x9ef7, 0x9ef7, 0xbef7, 0x9ef7, 0x9ef7, 0x7def, 0x5def, 0x7def, 0x7def, 0x3ce7, 0x5def, 0x5def, 0x1ce7, 0x59ce, 0x8f7b, 0x0842, 0xe741, 0xe741, 0xe841, 0x294a, 0x294a, 0x294a, 0x294a, 0x494a, 0x6a52, 0x0c63, 0x14ad, 0x7def, 0xbef7, 0xdfff, 0xbef7, 0x5def, 0x3ce7, 0x1ce7, 0x3ce7, 0x7def, 0x9ef7, 0x7def, 0x5def, 0x5def, 0x5def, 0x7def, 0x7def, 0x9ef7, 0x9ef7, 0x7def, 0x5def, 0x3ce7, 0x5def, 0x7def, 0x9ef7, 0x9ef7, 0x9ef7, 0x9ef7, 0x9ef7, 0xbef7, 0xbef7, 0xbef7, 0xdfff, 0xbef7, 0x9ef7, 0x5b9e, 0x393d, 0x1925, 0x7a35, 0xbb3d, 0x9a2d, 0x7624, 0x522b, 0x0f43, 0x6b7b, 0x28ab, 0x279a, 0xa7a2, 0x49c4, 0x89cc, 0x479a, 0x67a2, 0xa8b3, 0xe8aa, 0x07ab,
  0xbef7, 0xdfff, 0xdfff, 0xffff, 0xffff, 0xffff, 0xffff, 0xffff, 0xffff, 0xffff, 0xdfff, 0xbef7, 0x9ef7, 0x9ef7, 0xbef7, 0xdfff, 0xffff, 0xdfff, 0xbef7, 0x9ef7, 0x9ef7, 0xbef7, 0xbef7, 0x9ef7, 0x7def, 0x5def, 0x7def, 0x7def, 0x5def, 0x5def, 0x3ce7, 0x9ad6, 0x1184, 0x494a, 0xc739, 0xe841, 0xe841, 0x0942, 0x294a, 0x294a, 0x294a, 0x4a4a, 0x8a52, 0x2d6b, 0xf3a4, 0xbad6, 0x7def, 0xbef7, 0xdfff, 0xbef7, 0x9ef7, 0x3ce7, 0x3ce7, 0x1ce7, 0x5def, 0x7def, 0x7def, 0x7def, 0x5def, 0x5def, 0x7def, 0x7def, 0x9ef7, 0x9ef7, 0x7def, 0x3ce7, 0x3ce7, 0x5def, 0x7def, 0x7def, 0x9ef7, 0x9ef7, 0x9ef7, 0xbef7, 0xbef7, 0xbef7, 0xbef7, 0xbef7, 0xbef7, 0x9ef7, 0x7bae, 0x1945, 0x981c, 0x192d, 0xba35, 0x9a2d, 0xb824, 0x932b, 0x1033, 0x8c73, 0xa8b3, 0x479a, 0x479a, 0x67b3, 0xa8cc, 0xa7a2, 0x27aa, 0xa8aa, 0x0abc, 0x47a2,
  0xbef7, 0xbef7, 0xbef7, 0xdfff, 0xffff, 0xffff, 0xffff, 0xffff, 0xffff, 0xffff, 0xffff, 0xffff, 0xdfff, 0xdfff, 0xdfff, 0xdfff, 0xffff, 0xffff, 0xbef7, 0x9ef7, 0x7def, 0xbef7, 0xbef7, 0x9ef7, 0x7def, 0x5def, 0x7def, 0x5def, 0x3cef, 0x5def, 0xfbde, 0xf49c, 0x8a52, 0xe739, 0xe739, 0xe841, 0x0842, 0x294a, 0x294a, 0x294a, 0x494a, 0x8a52, 0x4d6b, 0x14a5, 0xfbde, 0x1ce7, 0x5def, 0xbef7, 0xdfff, 0xdfff, 0x9ef7, 0x7def, 0x3ce7, 0x3ce7, 0x3ce7, 0x5def, 0x7def, 0x7def, 0x7def, 0x5def, 0x5def, 0x7def, 0x7def, 0x9ef7, 0x7def, 0x5def, 0x5def, 0x5def, 0x5def, 0x7def, 0x9ef7, 0x9ef7, 0xbef7, 0xbef7, 0xbef7, 0xbef7, 0x9ef7, 0x9ef7, 0x9ef7, 0x9ef7, 0xbcbe, 0x394d, 0x9824, 0x9824, 0x1925, 0x5a25, 0xd81c, 0xd523, 0x1133, 0xad6b, 0x09b4, 0x87a2, 0x279a, 0xe7aa, 0xa9cc, 0xc8bb, 0x27aa, 0x68aa, 0x0abc, 0x87a2,
  0xbef7, 0xdfff, 0xbef7, 0xdfff, 0xffff, 0xffff, 0xffff, 0xffff, 0xffff, 0xffff, 0xffff, 0xffff, 0xffff, 0xdfff, 0xdfff, 0xdfff, 0xffff, 0xffff, 0xdfff, 0x7def, 0x7def, 0xbef7, 0x9ef7, 0x9ef7, 0x7def, 0x5def, 0x7def, 0x5def, 0x3ce7, 0x3ce7, 0xb7b5, 0xec62, 0xe841, 0xe739, 0xe841, 0x0842, 0x294a, 0x294a, 0x294a, 0x494a, 0x8a52, 0x8e73, 0x75b5, 0xdbde, 0x3ce7, 0x3ce7, 0x5def, 0x9ef7, 0xdfff, 0xdfff, 0xbef7, 0x9ef7, 0x5def, 0x3ce7, 0x3ce7, 0x3ce7, 0x5def, 0x5def, 0x5def, 0x5def, 0x5def, 0x7def, 0x7def, 0x9ef7, 0xbef7, 0xbef7, 0x9ef7, 0x5def, 0x5def, 0x7def, 0x7def, 0x9ef7, 0xbef7, 0x9ef7, 0x9ef7, 0xbef7, 0xbef7, 0x9ef7, 0x9ef7, 0x9ef7, 0xdcce, 0x5955, 0x972c, 0x3724, 0x771c, 0x191d, 0x191d, 0x3624, 0x312b, 0x6e5b, 0xeaa3, 0x47b3, 0x07a2, 0xa7b2, 0xa9cc, 0x89cc, 0x67aa, 0x27aa, 0x28ab, 0xcab3,
  0xbef7, 0xdfff, 0xdfff, 0xdfff, 0xdfff, 0xffff, 0xffff, 0xffff, 0xdfff, 0xdfff, 0xdfff, 0xbef7, 0xbef7, 0xbef7, 0xbef7, 0xdfff, 0xffff, 0xffff, 0xdfff, 0x7def, 0x5def, 0x9ef7, 0x9ef7, 0x9ef7, 0x7def, 0x5def, 0x5def, 0x5def, 0x3ce7, 0x59ce, 0x8f73, 0x0842, 0xc739, 0xe841, 0x0842, 0x2942, 0x294a, 0x294a, 0x494a, 0x8b52, 0xaf7b, 0xb7bd, 0x5def, 0x9ef7, 0x7def, 0x5def, 0x3ce7, 0x7def, 0xdfff, 0xdfff, 0xdfff, 0xbef7, 0x7def, 0x5def, 0x3ce7, 0x3ce7, 0x3ce7, 0x3ce7, 0x5def, 0x5def, 0x5def, 0x5def, 0x7def, 0x9ef7, 0xbef7, 0xbef7, 0xbef7, 0x7def, 0x5def, 0x7def, 0x7def, 0x9ef7, 0xbef7, 0xbef7, 0xbef7, 0xbef7, 0xbef7, 0x9ef7, 0x9ef7, 0x9ef7, 0x1dd7, 0x595d, 0x9734, 0x362c, 0xf523, 0x771c, 0xf914, 0x561c, 0x522b, 0x2f4b, 0xcb8b, 0xe8c3, 0x47aa, 0xa7b2, 0x88cc, 0x09d5, 0x27b3, 0x07aa, 0x67a2, 0x8bc4,
  0xdfff, 0xdfff, 0xbef7, 0xbef7, 0xbef7, 0xbef7, 0xdfff, 0xdfff, 0xbef7, 0xbef7, 0xbef7, 0xbef7, 0xbef7, 0x9ef7, 0xbef7, 0xbef7, 0xdfff, 0xffff, 0xdfff, 0x7def, 0x3ce7, 0x7def, 0x9ef7, 0x9ef7, 0x7def, 0x5def, 0x5def, 0x5def, 0xbad6, 0x1184, 0x294a, 0xc739, 0xe839, 0x0842, 0x2942, 0x294a, 0x294a, 0x494a, 0x8b5a, 0xcf7b, 0xd7bd, 0x5def, 0x9ef7, 0x7def, 0x9ef7, 0x7def, 0x3ce7, 0x5def, 0xdfff, 0xffff, 0xffff, 0xbef7, 0x9ef7, 0x5def, 0x3ce7, 0x3ce7, 0x3ce7, 0x3ce7, 0x3ce7, 0x5def, 0x5def, 0x5def, 0x7def, 0x7def, 0x9ef7, 0xbef7, 0xbef7, 0x9ef7, 0x7def, 0x7def, 0x7def, 0x9ef7, 0x9ef7, 0xbef7, 0x9ef7, 0x9ef7, 0x9ef7, 0x9ef7, 0x9ef7, 0x9ef7, 0x3de7, 0x3965, 0x5634, 0x152c, 0xd52b, 0xb423, 0x161c, 0xf523, 0x722b, 0x1033, 0x8c73, 0x28c4, 0x07b3, 0x87aa, 0x28c4, 0x69dd, 0x48c4, 0x26a2, 0x07a2, 0x48b3,
  0xdfff, 0xdfff, 0xbef7, 0xbef7, 0xbef7, 0xbef7, 0xdfff, 0xdfff, 0xdfff, 0xdfff, 0xdfff, 0xdfff, 0xdfff, 0xbef7, 0xbef7, 0xbef7, 0xdfff, 0xdfff, 0x9ef7, 0x5def, 0x1ce7, 0x7def, 0x9ef7, 0x9ef7, 0x7def, 0x3ce7, 0x5def, 0x1ce7, 0xb39c, 0x6a4a, 0xc739, 0xe839, 0x0842, 0x0942, 0x2942, 0x294a, 0x494a, 0xab5a, 0xf083, 0x18c6, 0x7def, 0xbef7, 0x9ef7, 0x5def, 0x5def, 0x7def, 0x5def, 0x5def, 0xbef7, 0xffff, 0xffff, 0xdfff, 0xbef7, 0x7def, 0x5def, 0x3ce7, 0x3ce7, 0x3ce7, 0x3ce7, 0x5def, 0x5def, 0x5def, 0x7def, 0x7def, 0x9ef7, 0xbef7, 0xdfff, 0xbef7, 0x9ef7, 0x7def, 0x7def, 0x7def, 0x9ef7, 0x9ef7, 0x9ef7, 0x9ef7, 0x9ef7, 0x9ef7, 0x9ef7, 0x9ef7, 0x5def, 0x186d, 0x1634, 0xf52b, 0xd52b, 0x742b, 0x5323, 0x5323, 0x522b, 0x312b, 0x0e53, 0xc9a3, 0x08c4, 0x87aa, 0xa7bb, 0x69dd, 0xe9d4, 0xc7aa, 0xe6a9, 0x27a2,
  0xbef7, 0xbef7, 0xbef7, 0xbef7, 0x9ef7, 0x9ef7, 0xbef7, 0xbef7, 0xdfff, 0xffff, 0xffff, 0xffff, 0xdfff, 0xdfff, 0xbef7, 0xbef7, 0xbef7, 0xbef7, 0x7def, 0x5def, 0x1ce7, 0x5def, 0x9ef7, 0x9ef7, 0x7def, 0x3ce7, 0x3ce7, 0x96b5, 0xab5a, 0xe839, 0xe839, 0xe841, 0x0942, 0x294a, 0x294a, 0x494a, 0x8b52, 0x318c, 0x59ce, 0x7def, 0xdfff, 0xffff, 0xdfff, 0xbef7, 0x7def, 0x5def, 0x7def, 0x7def, 0x9ef7, 0xdfff, 0xffff, 0xffff, 0xdfff, 0x9ef7, 0x7def, 0x5def, 0x5def, 0x5def, 0x5def, 0x5def, 0x5def, 0x5def, 0x7def, 0x7def, 0x9ef7, 0xbef7, 0xdfff, 0xdfff, 0xbef7, 0x9ef7, 0x7def, 0x7def, 0x9ef7, 0x9ef7, 0x7def, 0x5def, 0x7def, 0x9ef7, 0x9ef7, 0x9ef7, 0x7def, 0x1875, 0xf533, 0xd52b, 0xf52b, 0x942b, 0x332b, 0x122b, 0x322b, 0x322b, 0xef3a, 0x4b7b, 0x48c4, 0x47bb, 0x27b3, 0x29d5, 0xa8cc, 0x28c4, 0x06a2, 0xe7a1,
  0xdfff, 0xbef7, 0xbef7, 0xbef7, 0x9ef7, 0x9ef7, 0x9ef7, 0x9ef7, 0xbef7, 0xdfff, 0xdfff, 0xdfff, 0xdfff, 0xbef7, 0x9ef7, 0x9ef7, 0x9ef7, 0x9ef7, 0x7def, 0x3ce7, 0x1ce7, 0x5def, 0x9ef7, 0x9ef7, 0x7def, 0x1ce7, 0x18c6, 0xed62, 0xe841, 0xc839, 0xe841, 0x0842, 0x294a, 0x294a, 0x494a, 0x6a52, 0x1084, 0x79d6, 0x9ef7, 0xdef7, 0xdfff, 0xffff, 0xffff, 0xffff, 0xdfff, 0x9ef7, 0x7def, 0x7def, 0x9ef7, 0xbef7, 0xffff, 0xffff, 0xffff, 0xbef7, 0x9ef7, 0x7def, 0x5def, 0x5def, 0x5def, 0x5def, 0x5def, 0x5def, 0x7def, 0x7def, 0x7df7, 0xbef7, 0xdfff, 0xffff, 0xdfff, 0x9ef7, 0x9ef7, 0x7def, 0x7def, 0x7def, 0x5ce7, 0x3ce7, 0x3ce7, 0x7def, 0x9ef7, 0x9ef7, 0x7def, 0x798d, 0xd53b, 0xb42b, 0xd52b, 0xb42b, 0x5323, 0x122b, 0x122b, 0x112b, 0x1033, 0xec5a, 0xc8b3, 0x68cc, 0x27b3, 0xc8d4, 0xc7c3, 0x09d5, 0xc7aa, 0xe7a1,
  0xdfff, 0xbef7, 0xbef7, 0xbef7, 0xdfff, 0xbef7, 0xbef7, 0x9ef7, 0x9ef7, 0xbef7, 0xbef7, 0x9ef7, 0x9ef7, 0x9ef7, 0x9ef7, 0x9ef7, 0x9ef7, 0x9ef7, 0x7def, 0x3ce7, 0xfce6, 0x5def, 0x9ef7, 0x9ef7, 0x5def, 0xbad6, 0x6e73, 0xe841, 0xc839, 0xe841, 0x0842, 0x2942, 0x294a, 0x494a, 0x4a52, 0xd083, 0x38c6, 0x9ef7, 0xffff, 0xffff, 0xffff, 0xffff, 0xffff, 0xdfff, 0xbef7, 0xbef7, 0x9ef7, 0x7def, 0x7def, 0xbef7, 0xdfff, 0xffff, 0xffff, 0xdfff, 0xbef7, 0x9ef7, 0x7def, 0x5def, 0x5def, 0x5def, 0x5def, 0x5def, 0x7def, 0x7def, 0x7def, 0x9ef7, 0xdfff, 0xffff, 0xdfff, 0xbef7, 0x9ef7, 0x9ef7, 0x7def, 0x5def, 0x3ce7, 0x3ce7, 0x5def, 0x7def, 0x9ef7, 0x9ef7, 0xbef7, 0xdaa5, 0xf543, 0xb523, 0xd623, 0x9423, 0x532b, 0x332b, 0x122b, 0xf12a, 0xf12a, 0xae42, 0xe992, 0x68cc, 0x08c4, 0x68cc, 0x47bb, 0xa8cc, 0x27c4, 0xe699,
  0xbef7, 0xbef7, 0x9ef7, 0x9ef7, 0x9ef7, 0x9ef7, 0xbef7, 0xbef7, 0xbef7, 0xbef7, 0xbef7, 0xbef7, 0x9ef7, 0x7def, 0x7def, 0x7def, 0x9ef7, 0x9ef7, 0x5def, 0x3ce7, 0xfbde, 0x5def, 0x9ef7, 0x7def, 0xfcde, 0x1184, 0xe841, 0xc841, 0xe841, 0x0842, 0x0942, 0x294a, 0x294a, 0x294a, 0xd083, 0x39ce, 0x7def, 0xbef7, 0xffff, 0xffff, 0xffff, 0xffff, 0xffff, 0xbef7, 0xbef7, 0xbef7, 0x9ef7, 0x7def, 0x7def, 0x9ef7, 0xbef7, 0xffff, 0xffff, 0xffff, 0xdfff, 0x9ef7, 0x7def, 0x7def, 0x5def, 0x7def, 0x5def, 0x7def, 0x7def, 0x7def, 0x7def, 0x9ef7, 0xbef7, 0xffff, 0xffff, 0xdfff, 0x9ef7, 0x7def, 0x7def, 0x5def, 0x3ce7, 0x5def, 0x5def, 0x7def, 0xbef7, 0xdfff, 0xdfff, 0x3abe, 0x364c, 0xb523, 0xd623, 0xd523, 0x532b, 0x132b, 0xf22a, 0xd12a, 0xd12a, 0xaf32, 0x8b6a, 0x67bb, 0x09d5, 0x68cc, 0x87bb, 0x27bb, 0x08d5, 0xc7a2,
  0xbef7, 0xbef7, 0xbef7, 0xdfff, 0xdfff, 0xffff, 0xffff, 0xffff, 0xdfff, 0xbef7, 0x9ef7, 0x9ef7, 0x7def, 0x7def, 0x7def, 0x5def, 0x7def, 0x7def, 0x7def, 0x3ce7, 0xfbde, 0x5de7, 0x1ce7, 0x55ad, 0xab5a, 0xe841, 0xc739, 0xe841, 0x0842, 0x0842, 0x0842, 0x0942, 0x294a, 0xf083, 0x59ce, 0x9ef7, 0xbef7, 0xdfff, 0xffff, 0xffff, 0xffff, 0xffff, 0xffff, 0xffff, 0xdfff, 0xbef7, 0x9ef7, 0x7def, 0x5def, 0x7def, 0x9ef7, 0xdfff, 0xffff, 0xffff, 0xffff, 0xbef7, 0x9ef7, 0x7def, 0x7def, 0x7def, 0x7def, 0x7def, 0x7def, 0x7def, 0x7def, 0x9ef7, 0x9ef7, 0xbef7, 0xdeff, 0xdfff, 0xbef7, 0x7def, 0x5def, 0x5def, 0x3ce7, 0x3ce7, 0x5def, 0x7def, 0xbef7, 0xdfff, 0xffff, 0x9cce, 0x1554, 0x742b, 0x9523, 0xb523, 0x5423, 0xf22a, 0xd12a, 0xb12a, 0xb12a, 0xb12a, 0x6d4a, 0xa8a2, 0x68cc, 0xe9d4, 0xc8c3, 0x26b2, 0x68cc, 0x68c4,
  0x7def, 0xbef7, 0xdfff, 0xffff, 0xffff, 0xffff, 0xdfff, 0xdfff, 0xbef7, 0x7def, 0x5def, 0x5def, 0x7def, 0x7def, 0x7def, 0x7def, 0x7def, 0x7def, 0x5def, 0x3ce7, 0xdbde, 0x79ce, 0x7294, 0x0842, 0xa731, 0xc739, 0xe839, 0xe841, 0xe841, 0x0842, 0x0842, 0x494a, 0xf083, 0x59ce, 0x7def, 0xbef7, 0xdfff, 0xdfff, 0xffff, 0xffff, 0xffff, 0xffff, 0xffff, 0xffff, 0xdfff, 0x9ef7, 0x7def, 0x5def, 0x5def, 0x5def, 0x7def, 0xbef7, 0xffff, 0xffff, 0xffff, 0xdfff, 0xbef7, 0x9ef7, 0x7def, 0x7def, 0x7def, 0x7def, 0x7def, 0x7def, 0x7def, 0x7def, 0x9ef7, 0x7def, 0x3cef, 0x7def, 0x9df7, 0x5def, 0x5def, 0x5def, 0x3ce7, 0x3ce7, 0x5def, 0x9ef7, 0xffff, 0xffff, 0xffff, 0xdcd6, 0x155c, 0x122b, 0x5423, 0x9423, 0x5323, 0xf22a, 0xd12a, 0xb12a, 0xb12a, 0xb12a, 0x6e3a, 0x4972, 0xe7b2, 0xa9cc, 0x48cc, 0x06b2, 0xc6ba, 0x08dd,
  0xfbde, 0x1ce7, 0x3ce7, 0x9ef7, 0xdfff, 0xdfff, 0x9ef7, 0x7def, 0x5def, 0x5def, 0x5def, 0x5def, 0x7def, 0x7def, 0x7def, 0x7def, 0x5def, 0x7def, 0x5def, 0xdbde, 0x76b5, 0x4e6b, 0xe839, 0xa631, 0x8631, 0x8631, 0xc739, 0xe841, 0xe739, 0xe839, 0x4a4a, 0x118c, 0x7ad6, 0x5def, 0x7def, 0x9ef7, 0xdfff, 0xffff, 0xffff, 0xffff, 0xffff, 0xffff, 0xffff, 0xffff, 0xffff, 0xbeff, 0x9ef7, 0x7def, 0x5def, 0x5def, 0x7def, 0x9ef7, 0xdfff, 0xffff, 0xffff, 0xffff, 0xdfff, 0xbef7, 0x9ef7, 0x7def, 0x7def, 0x7def, 0x5def, 0x5def, 0x7def, 0x7def, 0x7df7, 0x7def, 0x1be7, 0x1be7, 0x1ce7, 0x3ce7, 0x5def, 0x5def, 0x5def, 0x5def, 0x5def, 0xdfff, 0xffff, 0xffff, 0xffff, 0x9cd6, 0xf45b, 0xf22a, 0x122b, 0x5323, 0x3323, 0xf22a, 0xb12a, 0xb12a, 0xb12a, 0x902a, 0x6f2a, 0x4b52, 0x27aa, 0x67bb, 0x88cc, 0xa7c2, 0x26da, 0x08dc,
  0xdbde, 0xfbde, 0xfbde, 0xfbde, 0x7def, 0x7df7, 0x7def, 0x5def, 0x5def, 0x5def, 0x5def, 0x5def, 0x5def, 0x5def, 0x5def, 0x5def, 0x5def, 0x5def, 0xfbde, 0x35a5, 0xcc5a, 0xa739, 0x8631, 0x8631, 0x8631, 0x8631, 0xa731, 0xe739, 0xe739, 0x2942, 0x1084, 0x9ad6, 0x7def, 0x9ef7, 0x5def, 0x7def, 0xbef7, 0xdfff, 0xdfff, 0xdfff, 0xdfff, 0xdfff, 0xdfff, 0xffff, 0xffff, 0xffff, 0xbef7, 0x9ef7, 0x7def, 0x7def, 0x5def, 0x7def, 0x9ef7, 0xdfff, 0xffff, 0xffff, 0xffff, 0xdfff, 0xbef7, 0x9ef7, 0x7def, 0x7def, 0x7def, 0x7def, 0x7def, 0x7def, 0x7def, 0x7def, 0x3ce7, 0x1be7, 0x1ce7, 0x3ce7, 0x5def, 0x5def, 0x5def, 0x5def, 0x7def, 0xdfff, 0xffff, 0xffff, 0xffff, 0xd9b5, 0x9353, 0xf12a, 0xf22a, 0x122b, 0x1323, 0xf222, 0xd12a, 0xb12a, 0xb12a, 0x9022, 0x6f2a, 0x4d42, 0x078a, 0x46ba, 0xa8d3, 0x49dc, 0xc8e2, 0x8be3,
  0x3ce7, 0x3ce7, 0x1ce7, 0xfbde, 0x3ce7, 0x9ef7, 0xbef7, 0x9ef7, 0x7def, 0x5def, 0x5def, 0x5def, 0x3ce7, 0x3ce7, 0x3ce7, 0x3ce7, 0x5def, 0x3ce7, 0xf7bd, 0xac5a, 0xc739, 0xa631, 0x8631, 0x8631, 0xa731, 0xa731, 0xa731, 0xa731, 0xc739, 0x6e73, 0xd7bd, 0x5def, 0x9ef7, 0x7def, 0x5def, 0x5def, 0x7def, 0xbef7, 0xdfff, 0xdfff, 0xdfff, 0xbef7, 0xbef7, 0xdfff, 0xffff, 0xffff, 0xdfff, 0xbef7, 0x9ef7, 0x7def, 0x5def, 0x7def, 0x7def, 0xbef7, 0xffff, 0xffff, 0xffff, 0xffff, 0xdfff, 0xbef7, 0x9ef7, 0x7def, 0x7def, 0x7def, 0x7def, 0x5def, 0x7def, 0x7def, 0x3cef, 0xfbe6, 0x1be7, 0x3ce7, 0x5def, 0x5def, 0x5def, 0x5def, 0x7def, 0xffff, 0xffff, 0xffff, 0xbef7, 0xf78c, 0x3243, 0xd02a, 0xd02a, 0xd12a, 0xf22a, 0xf222, 0xd122, 0xb12a, 0x912a, 0x9122, 0x902a, 0x6e32, 0x2a72, 0x07d2, 0xa8da, 0xabdc, 0xacdc, 0x91e4,
  0x9ef7, 0x7def, 0x7def, 0x3ce7, 0x1ce7, 0x5def, 0x9ef7, 0xdfff, 0xbef7, 0x9ef7, 0x9ef7, 0x7def, 0x7def, 0x5def, 0x5def, 0x3ce7, 0x3ce7, 0x1ce7, 0x96b5, 0x294a, 0xa731, 0x8631, 0x8631, 0x8631, 0xa731, 0xa731, 0xa731, 0x8731, 0x294a, 0x14a5, 0xdbde, 0x3def, 0x9ef7, 0x9ef7, 0x7def, 0x3ce7, 0x5def, 0xbef7, 0xdfff, 0xdfff, 0xbef7, 0xbef7, 0xbef7, 0xbef7, 0xdfff, 0xffff, 0xffff, 0xdfff, 0x9ef7, 0x9ef7, 0x7def, 0x7def, 0x7def, 0x9ef7, 0xdfff, 0xffff, 0xffff, 0xffff, 0xffff, 0xdfff, 0x9ef7, 0x9ef7, 0x7def, 0x7def, 0x7def, 0x5def, 0x5def, 0x7def, 0x5def, 0x1be7, 0x3ce7, 0x5cef, 0x7def, 0x7def, 0x7def, 0x7def, 0x9ef7, 0xdfff, 0xdfff, 0xdfff, 0x3ce7, 0x146c, 0xf132, 0xd12a, 0x8f2a, 0xb02a, 0xd12a, 0xd22a, 0xd122, 0xb122, 0x912a, 0x912a, 0x9022, 0x6f2a, 0x6d52, 0xaaca, 0xaee3, 0x90e4, 0x0ddd, 0xcddc,
  0xbef7, 0xbef7, 0xbef7, 0x9ef7, 0x7def, 0x7def, 0x9ef7, 0xbef7, 0xdfff, 0xdfff, 0xdfff, 0xbef7, 0x9ef7, 0x7def, 0x5def, 0x5def, 0x3ce7, 0x1ce7, 0x96b5, 0x0942, 0x6629, 0x8631, 0xa731, 0x8631, 0xa731, 0xa731, 0xa731, 0xc839, 0x9294, 0x9ad6, 0x5def, 0x3ce7, 0x7def, 0xbef7, 0x9ef7, 0x5def, 0x5def, 0x9ef7, 0xdfff, 0xbef7, 0xbef7, 0xbef7, 0x9ef7, 0x9ef7, 0xbef7, 0xffff, 0xffff, 0xffff, 0xbef7, 0x9ef7, 0x9ef7, 0x7def, 0x7def, 0x9ef7, 0xbef7, 0xdfff, 0xffff, 0xffff, 0xffff, 0xffff, 0xdfff, 0xbef7, 0x9ef7, 0x7def, 0x7def, 0x7def, 0x7def, 0x7def, 0x7def, 0x5def, 0x7def, 0x9ef7, 0x9ef7, 0xbef7, 0xbef7, 0xdfff, 0xdfff, 0xdfff, 0xbef7, 0x9ef7, 0x5ac6, 0xb353, 0xd132, 0xd12a, 0xb02a, 0x8f2a, 0x8f2a, 0xb02a, 0xb12a, 0xb12a, 0x902a, 0x902a, 0x9022, 0x9022, 0xaf42, 0xaeb3, 0x92e4, 0x92e4, 0xb0e4, 0x2cdd,
  0xffff, 0xffff, 0xdfff, 0xbef7, 0x9ef7, 0x7def, 0x7def, 0x7def, 0x9ef7, 0xbef7, 0xdfff, 0xdfff, 0xdfff, 0xbef7, 0x9ef7, 0x7def, 0x5def, 0x1ce7, 0x55ad, 0xe841, 0x8631, 0x8631, 0x8631, 0xa731, 0xa731, 0xa731, 0x8731, 0x8f7b, 0xdbde, 0x5def, 0x7def, 0x3ce7, 0x5def, 0xbef7, 0xdfff, 0x7def, 0x5def, 0x9ef7, 0xdfff, 0xdfff, 0xbef7, 0xbef7, 0x9ef7, 0x9ef7, 0x9ef7, 0xdfff, 0xffff, 0xffff, 0xdfff, 0xbef7, 0x9ef7, 0x9ef7, 0x9ef7, 0x9ef7, 0x9ef7, 0xdfff, 0xffff, 0xffff, 0xffff, 0xffff, 0xffff, 0xdfff, 0xbef7, 0x9ef7, 0x7def, 0x7def, 0x7def, 0x7def, 0x9ef7, 0x9ef7, 0xbef7, 0xbef7, 0xdfff, 0xdfff, 0xdfff, 0xdfff, 0xbef7, 0x9ef7, 0xbef7, 0x9ef7, 0x579d, 0x5243, 0xd12a, 0xd12a, 0xd12a, 0x902a, 0x6e2a, 0x6e2a, 0x8f2a, 0x902a, 0x912a, 0x902a, 0x902a, 0x9022, 0xaf3a, 0xee9b, 0xd1e4, 0x71e4, 0x92e4, 0xf0e4,
  0xbef7, 0x9ef7, 0x9ef7, 0x7def, 0x5def, 0x5def, 0x5def, 0x3ce7, 0x5def, 0x7def, 0x7df7, 0xbef7, 0xdfff, 0xffff, 0xdfff, 0xbef7, 0x7def, 0xfbde, 0x14a5, 0xc839, 0xa739, 0xa731, 0xa731, 0xa631, 0xa731, 0x8631, 0x2942, 0x76b5, 0x7def, 0xbef7, 0x7def, 0x5def, 0x3ce7, 0x7def, 0xdfff, 0xdfff, 0x9ef7, 0x9ef7, 0xdfff, 0xbef7, 0xbef7, 0x9ef7, 0x9ef7, 0x7def, 0x7def, 0xbef7, 0xffff, 0xffff, 0xffff, 0xdfff, 0xbef7, 0x9ef7, 0x9ef7, 0x7def, 0x9ef7, 0xbef7, 0xdfff, 0xffff, 0xffff, 0xffff, 0xffff, 0xffff, 0xdfff, 0xbef7, 0x9ef7, 0x9ef7, 0x7def, 0x7def, 0x9ef7, 0x9ef7, 0xbef7, 0xdfff, 0xdfff, 0xdfff, 0xbef7, 0x9ef7, 0x7def, 0x9ef7, 0x9ef7, 0x5def, 0x757c, 0x123b, 0xd12a, 0xd12a, 0xd12a, 0xb02a, 0x8f2a, 0x4d2a, 0x6e2a, 0x8f2a, 0x902a, 0x902a, 0x902a, 0x7022, 0x8f32, 0x6c73, 0x8fe5, 0xb1e4, 0x92e4, 0x92e4,
  0xdfff, 0xdfff, 0xdfff, 0xdfff, 0xdfff, 0xdfff, 0xdfff, 0xbef7, 0xbef7, 0x9ef7, 0x9ef7, 0x9ef7, 0xbef7, 0xdfff, 0xdfff, 0xdfff, 0xbef7, 0xfce6, 0x9394, 0xa739, 0xc739, 0xc839, 0xc739, 0xa731, 0x8631, 0xc739, 0x718c, 0x39ce, 0x7ef7, 0xdfff, 0x7def, 0x7def, 0x3ce7, 0x5def, 0xbef7, 0xdfff, 0xbef7, 0xbef7, 0xdfff, 0xdfff, 0xbef7, 0xbef7, 0x9ef7, 0x7def, 0x5def, 0x9ef7, 0xdfff, 0xffff, 0xffff, 0xffff, 0xdfff, 0x9ef7, 0x9ef7, 0x9ef7, 0x9ef7, 0x9ef7, 0xbef7, 0xdfff, 0xffff, 0xffff, 0xffff, 0xffff, 0xffff, 0xdfff, 0xbef7, 0x9ef7, 0x9ef7, 0x7def, 0x7def, 0x5def, 0x5def, 0x7def, 0x7def, 0x7def, 0x7def, 0x7def, 0x7def, 0x7def, 0x7def, 0x3ce7, 0x1464, 0xd132, 0xd12a, 0xd12a, 0xd12a, 0xb02a, 0x8f2a, 0x4d2a, 0x4d2a, 0x6e2a, 0x902a, 0x902a, 0x902a, 0x6f2a, 0x4f2a, 0xcc5a, 0x2ee5, 0x6ee5, 0x71e4, 0x72e4,
  0x9ef7, 0xffff, 0xffff, 0xffff, 0xffff, 0xffff, 0xffff, 0xffff, 0xffff, 0xffff, 0xffff, 0xffff, 0xdfff, 0xbef7, 0xbef7, 0xbef7, 0xbef7, 0x9ad6, 0x8f7b, 0xa731, 0xc739, 0xe841, 0x0842, 0xe839, 0xec62, 0x1084, 0x39c6, 0x9ad6, 0x7ef7, 0xdfff, 0x9ef7, 0x7def, 0x5def, 0x3ce7, 0x7def, 0xbef7, 0xbef7, 0xbef7, 0xdfff, 0xdeff, 0xbef7, 0xbef7, 0xbef7, 0x9ef7, 0x5def, 0x7def, 0xbef7, 0xffff, 0xffff, 0xffff, 0xffff, 0xbef7, 0x9ef7, 0x9ef7, 0x9ef7, 0x9ef7, 0x9ef7, 0xbef7, 0xdfff, 0xffff, 0xffff, 0xffff, 0xffff, 0xffff, 0xffff, 0xdfff, 0xbef7, 0x9ef7, 0x7def, 0x3ce7, 0x3ce7, 0x5def, 0x7def, 0x5def, 0x5def, 0x5def, 0x7def, 0x7def, 0x9ef7, 0x3def, 0x146c, 0xd032, 0xb02a, 0xb02a, 0xb02a, 0x902a, 0x6e2a, 0x6d2a, 0x6e2a, 0x6e2a, 0x8f2a, 0x902a, 0x902a, 0x6f2a, 0x4f22, 0x8d4a, 0x2fd4, 0x2edd, 0x0edd, 0x71e4
};
/* USER CODE END PV */

void SystemClock_Config(void);
/* USER CODE BEGIN PFP */
/* Private function prototypes -----------------------------------------------*/
uint16_t CRC_16_2(uint8_t *, uint8_t);
uint8_t isInCircle(int x, int y, int cx, int cy, int r);
uint16_t rgb565(uint8_t red, uint8_t green, uint8_t blue);
bool isInRectangle(int x, int y, int rx1, int ry1, int rx2, int ry2);
/* USER CODE END PFP */

int main(void)
{

  /* USER CODE BEGIN 1 */
	char str[50];
	uint8_t cmdBuffer[3];
	uint8_t dataBuffer[8];
	char group[20] = "Group No.028";
	char firstname[20] = "Chinnawat";
	char lastname[20] = "Chuabkhwamsuk";
	char studentId[20] = "64010182";

  /* USER CODE END 1 */

  /* Enable the CPU Cache */

  /* Enable I-Cache---------------------------------------------------------*/
  SCB_EnableICache();

  /* Enable D-Cache---------------------------------------------------------*/
  SCB_EnableDCache();

  /* MCU Configuration--------------------------------------------------------*/

  /* Reset of all peripherals, Initializes the Flash interface and the Systick. */
  HAL_Init();

  /* Configure the system clock */
  SystemClock_Config();

  /* Initialize all configured peripherals */
  MX_GPIO_Init();
  MX_USART3_UART_Init();
  MX_SPI5_Init();
  MX_TIM1_Init();
  MX_RNG_Init();
  MX_I2C1_Init();
  MX_TIM2_Init();
  MX_ADC1_Init();
  /* USER CODE BEGIN 2 */
  ILI9341_Init();//initial driver setup to drive ili9341
  sprintf(str, "\n\rAM2320 I2C DEMO Starting ...\n\r");
  HAL_UART_Transmit(&huart3, (uint8_t *) str, strlen(str), 200);
  HAL_TIM_Base_Start_IT(&htim2);

  cmdBuffer[0] = 0x03;
  cmdBuffer[1] = 0x00;
  cmdBuffer[2] = 0x04;

  HAL_ADC_Start(&hadc1);
  /* USER CODE END 2 */

  /* Infinite loop */
  /* USER CODE BEGIN WHILE */
  ILI9341_Fill_Screen(WHITE);
  ILI9341_Set_Rotation(SCREEN_HORIZONTAL_1);

	while (1)
  {

    /* USER CODE END WHILE */

    /* USER CODE BEGIN 3 */
	  // ========================= UART3 =======================
	  // sprintf(str, "Temperature = %4.1f\tHumidity = %4.1f\n\r\r\n", t, h);
	  // HAL_UART_Transmit(&huart3, (uint8_t*) str, strlen(str), 200);
	  // HAL_Delay(2000);

	  	  HAL_I2C_Master_Transmit(&hi2c1, 0x5c<<1, cmdBuffer, 3, 200);
	  	  HAL_I2C_Master_Transmit(&hi2c1, 0x5c<<1, cmdBuffer, 3, 200);
	  	  HAL_Delay(1);
	  	  HAL_I2C_Master_Receive(&hi2c1, 0x5c<<1, dataBuffer, 8, 200);
	  	  uint16_t Rcrc = dataBuffer[7] << 8;
	  	  Rcrc += dataBuffer[6];
	  	  if (Rcrc == CRC_16_2(dataBuffer, 6)){
	  		  uint16_t temperature = ((dataBuffer[4] & 0x7F) < 8) + dataBuffer[5];
	  		  t = temperature / 10.0;
	  		  uint16_t humidity = (dataBuffer[2] << 8) + dataBuffer[3];
	  		  h = humidity / 10.0;
	  	  }

	  	  // ========================= DRAW =======================

	  	 while (HAL_ADC_PollForConversion(&hadc1, 100) != HAL_OK) {}
	  		  adc_val = HAL_ADC_GetValue(&hadc1);

	  		  brightness = adc_val * 0.8 / 4096 + 0.2;
	  		  htim2.Instance -> CCR4 = 199 * brightness;
	  		  sprintf(str, "%d\n\r", adc_val);
	  		  HAL_UART_Transmit(&huart3, (uint8_t *) str, strlen(str), 200);
	  		  sprintf(str, "%.2f\n\r", brightness);
	  		   HAL_UART_Transmit(&huart3, (uint8_t *) str, strlen(str), 200);
	  		   	HAL_TIM_PWM_Start(&htim2, TIM_CHANNEL_4);

	  		  HAL_Delay(20);

	  	  char buffer[40];
	  	  char textBuffer[100];
	  	  snprintf(buffer, sizeof(buffer), "%2.2fC", t);
	  	  ILI9341_Draw_Text(buffer, 10, 20, BLACK, 2, WHITE);

	  	  rgb = rgb565(Red, Green, Blue);

	  	  ILI9341_Draw_Filled_Circle(115, 30, 40/2, rgb);
	  	  snprintf(buffer, sizeof(buffer), "%2.2f%%RH", h);
	  	  ILI9341_Draw_Text(buffer, 150, 20, BLACK, 2, WHITE);

	  	  uint16_t redRecBackground = rgb565(255, 204, 204);
	  	  uint16_t redRec = rgb565(255, 0, 0);

	  	  rLength = (14 * rCount) + 60;
	  	  ILI9341_Draw_Filled_Circle(30, 90, 35/2, RED);
	  	  ILI9341_Draw_Filled_Rectangle_Coord(60, 75, 200, 105, redRecBackground);
	  	  ILI9341_Draw_Filled_Rectangle_Coord(60, 75, rLength, 105, redRec);
	  	  snprintf(textBuffer, sizeof(textBuffer), "%3d%%", rCount * 10);
	  	  ILI9341_Draw_Text(textBuffer, 210, 80, BLACK, 2, WHITE);

	  	  uint16_t greenRecBackground = rgb565(204, 255, 204);
	  	  uint16_t greenRec = rgb565(0, 255, 0);
	  	  gLength = (14 * gCount) + 60;

	  	  ILI9341_Draw_Filled_Circle(30, 140, 35/2, GREEN);
	  	  ILI9341_Draw_Filled_Rectangle_Coord(60, 125, 200, 155, greenRecBackground);
	  	  ILI9341_Draw_Filled_Rectangle_Coord(60, 125, gLength, 155, greenRec);
	  	  snprintf(textBuffer, sizeof(textBuffer), "%3d%%", gCount * 10);
	  	  ILI9341_Draw_Text(textBuffer, 210, 130, BLACK, 2, WHITE);

	  	  uint16_t blueRecBackground = rgb565(204, 204, 255);
	  	  uint16_t blueRec = rgb565(0, 0, 255);
	  	  bLength = (14 * bCount) + 60;

	  	  ILI9341_Draw_Filled_Circle(30, 190, 35/2, BLUE);
	  	  ILI9341_Draw_Filled_Rectangle_Coord(60, 175, 200, 205, blueRecBackground);
	  	  ILI9341_Draw_Filled_Rectangle_Coord(60, 175, bLength, 205, blueRec);
	  	  snprintf(textBuffer, sizeof(textBuffer), "%3d%%", bCount * 10);
	  	  ILI9341_Draw_Text(textBuffer, 210, 180, BLACK, 2, WHITE);

	  	  if (TP_Touchpad_Pressed()) {
	  			  uint16_t position_array[2] = {0};

	  			  if (TP_Read_Coordinates(position_array) == TOUCHPAD_DATA_OK) {
	  				  x_pos = position_array[1];
	  				  y_pos = calculate_abs_difference(position_array[0]);

	  				if (isInCircle(x_pos, y_pos, 115, 30, 20)) {
	  					show_screen_2 = 1;
	  					prevCount = count;
	  					ILI9341_Fill_Screen(WHITE);
	  					ILI9341_Set_Rotation(SCREEN_HORIZONTAL_1);

	  				}

	  				if (isInCircle(x_pos, y_pos, 30, 90, 18)) {
	  					if(Red >= 255){
	  						Red = 0;

	  					}

	  					Red += 255 * 10 / 100;
	  					rCount += 1;

	  					if(rCount > 10){
	  						rCount = 0;
	  					}
	  				}

	  				if (isInCircle(x_pos, y_pos, 30, 140, 18)) {
	  					if(Green >= 255){
	  						Green = 0;

	  					}

	  					Green += 255 * 10 / 100;
	  					gCount += 1;

	  					if(gCount > 10){
	  						gCount = 0;
	  					}
	  				}

	  				if (isInCircle(x_pos, y_pos, 30, 190, 18)) {
	  					if(Blue >= 255){
	  						Blue = 0;

	  					}
	  					Blue += 255 * 10 / 100;
	  					bCount += 1;

	  					if(bCount > 10){
	  						bCount = 0;
	  					}
	  				}
	  			  }
	  		  }

	  	  while(count - prevCount < 5 && show_screen_2) {
	  		while (HAL_ADC_PollForConversion(&hadc1, 100) != HAL_OK) {}
	  		adc_val = HAL_ADC_GetValue(&hadc1);

	  			  		  brightness = adc_val * 0.8 / 4096 + 0.2;
	  			  		  htim2.Instance -> CCR4 = 199 * brightness;
	  		  if (TP_Touchpad_Pressed()){
	  			  uint16_t position_array[2] = {0};

	  			  if (TP_Read_Coordinates(position_array) == TOUCHPAD_DATA_OK) {
	  				  x_pos = position_array[1];
	  				  y_pos = calculate_abs_difference(position_array[0]);
	  				  if(isInRectangle(x_pos,y_pos,5,50,105,182)){
	  					ILI9341_Fill_Screen(WHITE);
	  					ILI9341_Set_Rotation(SCREEN_HORIZONTAL_1);
	  					show_screen_2 = 0;
	  					break;
//	  					exit_screen_2 = 0;
	  				  }
	  			  }
	  		  }

	  		  My_Draw_Image(&student_photo, 5, 50, P1011387_WIDTH, P1011387_HEIGHT);

	  		  rgb = rgb565(Red, Green, Blue);

	  		  snprintf(buffer, sizeof(buffer), "%s", group);
	  		  ILI9341_Draw_Text(buffer, 110, 45, rgb, 2, WHITE);

	  		  snprintf(buffer, sizeof(buffer), "%s", firstname);
	  		  ILI9341_Draw_Text(buffer, 110, 85, rgb, 2, WHITE);

	  		  snprintf(buffer, sizeof(buffer), "%s", lastname);
	  		  ILI9341_Draw_Text(buffer, 110, 125, rgb, 2, WHITE);

	  		  snprintf(buffer, sizeof(buffer), "%s", studentId);
	  		  ILI9341_Draw_Text(buffer, 110, 165, rgb, 2, WHITE);

	  		if(count - prevCount >= 5) {
	  			ILI9341_Fill_Screen(WHITE);
	  		}
	  	  }

	  	  if (exit_screen_2 == 0) {
	  		  exit_screen_2 = 1;
	  	  }
	  	exit_screen_2 = 1;
	  	  if(count - prevCount >= 5) {
	  		exit_screen_2 = 1;
	  	  }
	  	HAL_TIM_PWM_Stop(&htim2, TIM_CHANNEL_4);

//	   ========================= SPI =======================

  }
  /* USER CODE END 3 */
}

void SystemClock_Config(void)
{
  RCC_OscInitTypeDef RCC_OscInitStruct = {0};
  RCC_ClkInitTypeDef RCC_ClkInitStruct = {0};

  /** Configure LSE Drive Capability
  */
  HAL_PWR_EnableBkUpAccess();

  /** Configure the main internal regulator output voltage
  */
  __HAL_RCC_PWR_CLK_ENABLE();
  __HAL_PWR_VOLTAGESCALING_CONFIG(PWR_REGULATOR_VOLTAGE_SCALE1);

  /** Initializes the RCC Oscillators according to the specified parameters
  * in the RCC_OscInitTypeDef structure.
  */
  RCC_OscInitStruct.OscillatorType = RCC_OSCILLATORTYPE_HSE;
  RCC_OscInitStruct.HSEState = RCC_HSE_BYPASS;
  RCC_OscInitStruct.PLL.PLLState = RCC_PLL_ON;
  RCC_OscInitStruct.PLL.PLLSource = RCC_PLLSOURCE_HSE;
  RCC_OscInitStruct.PLL.PLLM = 4;
  RCC_OscInitStruct.PLL.PLLN = 200;
  RCC_OscInitStruct.PLL.PLLP = RCC_PLLP_DIV2;
  RCC_OscInitStruct.PLL.PLLQ = 9;
  RCC_OscInitStruct.PLL.PLLR = 2;
  if (HAL_RCC_OscConfig(&RCC_OscInitStruct) != HAL_OK)
  {
    Error_Handler();
  }

  /** Activate the Over-Drive mode
  */
  if (HAL_PWREx_EnableOverDrive() != HAL_OK)
  {
    Error_Handler();
  }

  /** Initializes the CPU, AHB and APB buses clocks
  */
  RCC_ClkInitStruct.ClockType = RCC_CLOCKTYPE_HCLK|RCC_CLOCKTYPE_SYSCLK
                              |RCC_CLOCKTYPE_PCLK1|RCC_CLOCKTYPE_PCLK2;
  RCC_ClkInitStruct.SYSCLKSource = RCC_SYSCLKSOURCE_PLLCLK;
  RCC_ClkInitStruct.AHBCLKDivider = RCC_SYSCLK_DIV1;
  RCC_ClkInitStruct.APB1CLKDivider = RCC_HCLK_DIV4;
  RCC_ClkInitStruct.APB2CLKDivider = RCC_HCLK_DIV2;

  if (HAL_RCC_ClockConfig(&RCC_ClkInitStruct, FLASH_LATENCY_6) != HAL_OK)
  {
    Error_Handler();
  }
}

/* USER CODE BEGIN 4 */
uint16_t CRC_16_2(uint8_t *ptr, uint8_t length)
{
	uint16_t crc = 0xFFFF;
	uint8_t s = 0x00;
	while (length--){
		crc ^= *ptr++;
		for (s = 0; s < 8; s++){
			if((crc & 0x01) != 0){
				crc >>= 1;
				crc ^= 0xA001;
			}
			else{
				crc >>= 1;
			}
		}
	}
	return crc;
}

uint8_t isInCircle(int x, int y, int cx, int cy, int r) {
    int dx = x - cx;
    int dy = y - cy;

    return (dx * dx + dy * dy) <= (r * r);
}

bool isInRectangle(int x, int y, int rx1, int ry1, int rx2, int ry2) {
    return (x >= rx1 && x <= rx2 && y >= ry1 && y <= ry2);
}

uint16_t rgb565(uint8_t red, uint8_t green, uint8_t blue) {
    // Convert 8-bit RGB to 5-6-5 bit format
    uint16_t r = (red >> 3) & 0x1F;   // 5 bits for Red
    uint16_t g = (green >> 2) & 0x3F; // 6 bits for Green
    uint16_t b = (blue >> 3) & 0x1F;  // 5 bits for Blue

    // Combine the bits into a single 16-bit value
    return (r << 11) | (g << 5) | b;
}

int calculate_abs_difference(int y) {
    return abs(240 - y);
}

void My_Draw_Image(const char *Image_Array, uint8_t x, uint8_t y, uint8_t w, uint8_t h)
{
    ILI9341_Set_Address(x, y, x + w - 1, y + h - 1);
    HAL_GPIO_WritePin(LCD_DC_PORT, LCD_DC_PIN, GPIO_PIN_SET);
    HAL_GPIO_WritePin(LCD_CS_PORT, LCD_CS_PIN, GPIO_PIN_RESET);
    unsigned char Temp_small_buffer[BURST_MAX_SIZE];
    uint32_t counter = 0;
    for (uint32_t i = 0; i < w * h * 2 / BURST_MAX_SIZE; i++)
    {
        for (uint32_t k = 0; k < BURST_MAX_SIZE; k++)
        {
            Temp_small_buffer[k] = Image_Array[counter + k];
        }
        HAL_SPI_Transmit(HSPI_INSTANCE, (unsigned char *)Temp_small_buffer, BURST_MAX_SIZE, 10);
        counter += BURST_MAX_SIZE;
    }
    if ((w * h * 2) % BURST_MAX_SIZE != 0)
    {
        uint32_t remaining = (w * h * 2) % BURST_MAX_SIZE;
        for (uint32_t k = 0; k < remaining; k++)
        {
            Temp_small_buffer[k] = Image_Array[counter + k];
        }
        HAL_SPI_Transmit(HSPI_INSTANCE, (unsigned char *)Temp_small_buffer, remaining, 10);
    }
    HAL_GPIO_WritePin(LCD_CS_PORT, LCD_CS_PIN, GPIO_PIN_SET);
}

/* USER CODE END 4 */

void Error_Handler(void)
{
  while(1)
  {
  }
}
